VERSION ""

NS_ :

BS_:
BU_: FR FC ADC

BO_ 373 FC_175: 64 FC
 SG_ FC_Obj16WSInfoPosType : 133|4@0+ (1.0000000000,0.0000000000) [0.0000000000|15.0000000000] ""  FC,ADC
 SG_ FC_CRCCheck_175 : 503|16@0+ (1.0000000000,0.0000000000) [0.0000000000|65535.0000000000] ""  FC,ADC
 SG_ FC_RollingCounter_175 : 491|4@0+ (1.0000000000,0.0000000000) [0.0000000000|15.0000000000] ""  FC,ADC
 SG_ FC_Obj16_Img2dBox_RightDown_V : 288|12@0+ (1.0000000000,0.0000000000) [0.0000000000|3000.0000000000] "pix"  FC,ADC
 SG_ FC_Obj16_Img2dBox_LeftTop_V : 284|12@0+ (1.0000000000,0.0000000000) [0.0000000000|3000.0000000000] "pix"  FC,ADC
 SG_ FC_Obj16_Img2dBox_RightDown_U : 264|12@0+ (1.0000000000,0.0000000000) [0.0000000000|4095.0000000000] "pix"  FC,ADC
 SG_ FC_Obj16_Img2dBox_LeftTop_U : 260|12@0+ (1.0000000000,0.0000000000) [0.0000000000|4095.0000000000] "pix"  FC,ADC
 SG_ FC_Obj16_TurnLight : 262|2@0+ (1.0000000000,0.0000000000) [0.0000000000|3.0000000000] ""  FC,ADC
 SG_ FC_Obj16_valid : 263|1@0+ (1.0000000000,0.0000000000) [0.0000000000|1.0000000000] ""  FC,ADC
 SG_ FC_Obj16_Vy_Vnce : 241|10@0+ (0.1250000000,-64.0000000000) [-64.0000000000|63.8750000000] "m/s"  FC,ADC
 SG_ FC_Obj16_Vx_Vnce : 237|12@0+ (0.0625000000,-128.0000000000) [-128.0000000000|127.9375000000] "m/s"  FC,ADC
 SG_ FC_Obj16_CenterAngle : 230|9@0+ (0.0100000000,-1.5700000000) [-1.5700000000|1.5700000000] ""  FC,ADC
 SG_ FC_Obj16_DistInLane : 209|11@0+ (0.0100000000,-10.0000000000) [-10.0000000000|10.0000000000] ""  FC,ADC
 SG_ FC_Obj16_objCutInLane : 211|2@0+ (1.0000000000,0.0000000000) [0.0000000000|2.0000000000] ""  FC,ADC
 SG_ FC_Obj16_objCutInFlag : 201|2@0+ (1.0000000000,0.0000000000) [0.0000000000|2.0000000000] ""  FC,ADC
 SG_ FC_Obj16_CornerPoint_y : 199|14@0+ (0.0100000000,-80.0000000000) [-80.0000000000|80.0000000000] ""  FC,ADC
 SG_ FC_Obj16_CornerPoint_x : 182|15@0+ (0.0100000000,0.0000000000) [0.0000000000|200.0000000000] ""  FC,ADC
 SG_ FC_Obj16_LaneAssignment : 169|3@0+ (1.0000000000,0.0000000000) [0.0000000000|7.0000000000] ""  FC,ADC
 SG_ FC_Obj16_MotionType : 172|3@0+ (1.0000000000,0.0000000000) [0.0000000000|4.0000000000] ""  FC,ADC
 SG_ FC_obj16_Brakelight_Info : 173|1@0+ (1.0000000000,0.0000000000) [0.0000000000|1.0000000000] ""  FC,ADC
 SG_ FC_Obj16_Width : 155|11@0+ (0.0100000000,0.0000000000) [0.0000000000|12.0000000000] "m"  FC,ADC
 SG_ FC_Obj16_Length : 148|9@0+ (0.0500000000,0.0000000000) [0.0000000000|25.5000000000] "m"  FC,ADC
 SG_ FC_Obj16_Height : 141|9@0+ (0.0100000000,0.0000000000) [0.0000000000|5.1100000000] "m"  FC,ADC
 SG_ FC_Obj16_HeadOrientation : 129|4@0+ (1.0000000000,0.0000000000) [0.0000000000|15.0000000000] ""  FC,ADC
 SG_ FC_Obj16_HeadingAngle : 308|10@0+ (0.0100000000,-3.1400000000) [-3.1400000000|3.1400000000] "rad"  FC,ADC
 SG_ FC_Obj16_ExistProb : 112|6@0+ (2.0000000000,0.0000000000) [0.0000000000|100.0000000000] "%"  FC,ADC
 SG_ FC_Obj16_Dy_Vnce : 106|10@0+ (0.0200000000,0.0000000000) [0.0000000000|20.0000000000] "m2"  FC,ADC
 SG_ FC_Obj16_Dy : 88|14@0+ (0.0100000000,-80.0000000000) [-80.0000000000|80.0000000000] "m"  FC,ADC
 SG_ FC_Obj16_Dx_Vnce : 86|14@0+ (0.0500000000,0.0000000000) [0.0000000000|50.0000000000] "m2"  FC,ADC
 SG_ FC_Obj16_Dx : 66|12@0+ (0.0500000000,0.0000000000) [0.0000000000|204.7000000000] "m"  FC,ADC
 SG_ FC_Obj16_RelVy : 60|10@0+ (0.1000000000,-50.0000000000) [-50.0000000000|50.0000000000] "m/s"  FC,ADC
 SG_ FC_Obj16_RelVx : 40|12@0+ (0.1000000000,-154.0000000000) [-154.0000000000|50.0000000000] "m/s"  FC,ADC
 SG_ FC_Obj16_RelAy : 32|8@0+ (0.1000000000,-12.0000000000) [-12.0000000000|12.0000000000] "m/s2"  FC,ADC
 SG_ FC_Obj16_RelAx : 25|9@0+ (0.1000000000,-16.0000000000) [-16.0000000000|16.0000000000] "m/s2"  FC,ADC
 SG_ FC_Obj16_TypeProb : 31|6@0+ (2.0000000000,0.0000000000) [0.0000000000|100.0000000000] "%"  FC,ADC
 SG_ FC_Obj16_Type : 19|4@0+ (1.0000000000,0.0000000000) [0.0000000000|15.0000000000] ""  FC,ADC
 SG_ FC_Obj16_Track_Age : 314|16@0+ (1.0000000000,0.0000000000) [0.0000000000|65535.0000000000] ""  FC,ADC
 SG_ FC_Obj16_Track_ID : 3|8@0+ (1.0000000000,0.0000000000) [0.0000000000|255.0000000000] ""  FC,ADC

BO_ 374 FC_176: 64 FC
 SG_ FC_Obj17WSInfoPosType : 133|4@0+ (1.0000000000,0.0000000000) [0.0000000000|15.0000000000] ""  FC,ADC
 SG_ FC_CRCCheck_176 : 503|16@0+ (1.0000000000,0.0000000000) [0.0000000000|65535.0000000000] ""  FC,ADC
 SG_ FC_RollingCounter_176 : 491|4@0+ (1.0000000000,0.0000000000) [0.0000000000|15.0000000000] ""  FC,ADC
 SG_ FC_Obj17_Img2dBox_RightDown_V : 288|12@0+ (1.0000000000,0.0000000000) [0.0000000000|3000.0000000000] "pix"  FC,ADC
 SG_ FC_Obj17_Img2dBox_LeftTop_V : 284|12@0+ (1.0000000000,0.0000000000) [0.0000000000|3000.0000000000] "pix"  FC,ADC
 SG_ FC_Obj17_Img2dBox_RightDown_U : 264|12@0+ (1.0000000000,0.0000000000) [0.0000000000|4095.0000000000] "pix"  FC,ADC
 SG_ FC_Obj17_Img2dBox_LeftTop_U : 260|12@0+ (1.0000000000,0.0000000000) [0.0000000000|4095.0000000000] "pix"  FC,ADC
 SG_ FC_Obj17_TurnLight : 262|2@0+ (1.0000000000,0.0000000000) [0.0000000000|3.0000000000] ""  FC,ADC
 SG_ FC_Obj17_valid : 263|1@0+ (1.0000000000,0.0000000000) [0.0000000000|1.0000000000] ""  FC,ADC
 SG_ FC_Obj17_Vy_Vnce : 241|10@0+ (0.1250000000,-64.0000000000) [-64.0000000000|63.8750000000] "m/s"  FC,ADC
 SG_ FC_Obj17_Vx_Vnce : 237|12@0+ (0.0625000000,-128.0000000000) [-128.0000000000|127.9375000000] "m/s"  FC,ADC
 SG_ FC_Obj17_CenterAngle : 230|9@0+ (0.0100000000,-1.5700000000) [-1.5700000000|1.5700000000] ""  FC,ADC
 SG_ FC_Obj17_DistInLane : 209|11@0+ (0.0100000000,-10.0000000000) [-10.0000000000|10.0000000000] ""  FC,ADC
 SG_ FC_Obj17_objCutInLane : 211|2@0+ (1.0000000000,0.0000000000) [0.0000000000|2.0000000000] ""  FC,ADC
 SG_ FC_Obj17_objCutInFlag : 201|2@0+ (1.0000000000,0.0000000000) [0.0000000000|2.0000000000] ""  FC,ADC
 SG_ FC_Obj17_CornerPoint_y : 199|14@0+ (0.0100000000,-80.0000000000) [-80.0000000000|80.0000000000] ""  FC,ADC
 SG_ FC_Obj17_CornerPoint_x : 182|15@0+ (0.0100000000,0.0000000000) [0.0000000000|200.0000000000] ""  FC,ADC
 SG_ FC_Obj17_LaneAssignment : 169|3@0+ (1.0000000000,0.0000000000) [0.0000000000|7.0000000000] ""  FC,ADC
 SG_ FC_Obj17_MotionType : 172|3@0+ (1.0000000000,0.0000000000) [0.0000000000|4.0000000000] ""  FC,ADC
 SG_ FC_obj17_Brakelight_Info : 173|1@0+ (1.0000000000,0.0000000000) [0.0000000000|1.0000000000] ""  FC,ADC
 SG_ FC_Obj17_Width : 155|11@0+ (0.0100000000,0.0000000000) [0.0000000000|12.0000000000] "m"  FC,ADC
 SG_ FC_Obj17_Length : 148|9@0+ (0.0500000000,0.0000000000) [0.0000000000|25.5000000000] "m"  FC,ADC
 SG_ FC_Obj17_Height : 141|9@0+ (0.0100000000,0.0000000000) [0.0000000000|5.1100000000] "m"  FC,ADC
 SG_ FC_Obj17_HeadOrientation : 129|4@0+ (1.0000000000,0.0000000000) [0.0000000000|15.0000000000] ""  FC,ADC
 SG_ FC_Obj17_HeadingAngle : 308|10@0+ (0.0100000000,-3.1400000000) [-3.1400000000|3.1400000000] "rad"  FC,ADC
 SG_ FC_Obj17_ExistProb : 112|6@0+ (2.0000000000,0.0000000000) [0.0000000000|100.0000000000] "%"  FC,ADC
 SG_ FC_Obj17_Dy_Vnce : 106|10@0+ (0.0200000000,0.0000000000) [0.0000000000|20.0000000000] "m2"  FC,ADC
 SG_ FC_Obj17_Dy : 88|14@0+ (0.0100000000,-80.0000000000) [-80.0000000000|80.0000000000] "m"  FC,ADC
 SG_ FC_Obj17_Dx_Vnce : 86|14@0+ (0.0500000000,0.0000000000) [0.0000000000|50.0000000000] "m2"  FC,ADC
 SG_ FC_Obj17_Dx : 66|12@0+ (0.0500000000,0.0000000000) [0.0000000000|204.7000000000] "m"  FC,ADC
 SG_ FC_Obj17_RelVy : 60|10@0+ (0.1000000000,-50.0000000000) [-50.0000000000|50.0000000000] "m/s"  FC,ADC
 SG_ FC_Obj17_RelVx : 40|12@0+ (0.1000000000,-154.0000000000) [-154.0000000000|50.0000000000] "m/s"  FC,ADC
 SG_ FC_Obj17_RelAy : 32|8@0+ (0.1000000000,-12.0000000000) [-12.0000000000|12.0000000000] "m/s2"  FC,ADC
 SG_ FC_Obj17_RelAx : 25|9@0+ (0.1000000000,-16.0000000000) [-16.0000000000|16.0000000000] "m/s2"  FC,ADC
 SG_ FC_Obj17_TypeProb : 31|6@0+ (2.0000000000,0.0000000000) [0.0000000000|100.0000000000] "%"  FC,ADC
 SG_ FC_Obj17_Type : 19|4@0+ (1.0000000000,0.0000000000) [0.0000000000|15.0000000000] ""  FC,ADC
 SG_ FC_Obj17_Track_Age : 314|16@0+ (1.0000000000,0.0000000000) [0.0000000000|65535.0000000000] ""  FC,ADC
 SG_ FC_Obj17_Track_ID : 3|8@0+ (1.0000000000,0.0000000000) [0.0000000000|255.0000000000] ""  FC,ADC

BO_ 375 FC_177: 64 FC
 SG_ FC_Obj18WSInfoPosType : 133|4@0+ (1.0000000000,0.0000000000) [0.0000000000|15.0000000000] ""  FC,ADC
 SG_ FC_CRCCheck_177 : 503|16@0+ (1.0000000000,0.0000000000) [0.0000000000|65535.0000000000] ""  FC,ADC
 SG_ FC_RollingCounter_177 : 491|4@0+ (1.0000000000,0.0000000000) [0.0000000000|15.0000000000] ""  FC,ADC
 SG_ FC_Obj18_Img2dBox_RightDown_V : 288|12@0+ (1.0000000000,0.0000000000) [0.0000000000|3000.0000000000] "pix"  FC,ADC
 SG_ FC_Obj18_Img2dBox_LeftTop_V : 284|12@0+ (1.0000000000,0.0000000000) [0.0000000000|3000.0000000000] "pix"  FC,ADC
 SG_ FC_Obj18_Img2dBox_RightDown_U : 264|12@0+ (1.0000000000,0.0000000000) [0.0000000000|4095.0000000000] "pix"  FC,ADC
 SG_ FC_Obj18_Img2dBox_LeftTop_U : 260|12@0+ (1.0000000000,0.0000000000) [0.0000000000|4095.0000000000] "pix"  FC,ADC
 SG_ FC_Obj18_TurnLight : 262|2@0+ (1.0000000000,0.0000000000) [0.0000000000|3.0000000000] ""  FC,ADC
 SG_ FC_Obj18_valid : 263|1@0+ (1.0000000000,0.0000000000) [0.0000000000|1.0000000000] ""  FC,ADC
 SG_ FC_Obj18_Vy_Vnce : 241|10@0+ (0.1250000000,-64.0000000000) [-64.0000000000|63.8750000000] "m/s"  FC,ADC
 SG_ FC_Obj18_Vx_Vnce : 237|12@0+ (0.0625000000,-128.0000000000) [-128.0000000000|127.9375000000] "m/s"  FC,ADC
 SG_ FC_Obj18_CenterAngle : 230|9@0+ (0.0100000000,-1.5700000000) [-1.5700000000|1.5700000000] ""  FC,ADC
 SG_ FC_Obj18_DistInLane : 209|11@0+ (0.0100000000,-10.0000000000) [-10.0000000000|10.0000000000] ""  FC,ADC
 SG_ FC_Obj18_objCutInLane : 211|2@0+ (1.0000000000,0.0000000000) [0.0000000000|2.0000000000] ""  FC,ADC
 SG_ FC_Obj18_objCutInFlag : 201|2@0+ (1.0000000000,0.0000000000) [0.0000000000|2.0000000000] ""  FC,ADC
 SG_ FC_Obj18_CornerPoint_y : 199|14@0+ (0.0100000000,-80.0000000000) [-80.0000000000|80.0000000000] ""  FC,ADC
 SG_ FC_Obj18_CornerPoint_x : 182|15@0+ (0.0100000000,0.0000000000) [0.0000000000|200.0000000000] ""  FC,ADC
 SG_ FC_Obj18_LaneAssignment : 169|3@0+ (1.0000000000,0.0000000000) [0.0000000000|7.0000000000] ""  FC,ADC
 SG_ FC_Obj18_MotionType : 172|3@0+ (1.0000000000,0.0000000000) [0.0000000000|4.0000000000] ""  FC,ADC
 SG_ FC_obj18_Brakelight_Info : 173|1@0+ (1.0000000000,0.0000000000) [0.0000000000|1.0000000000] ""  FC,ADC
 SG_ FC_Obj18_Width : 155|11@0+ (0.0100000000,0.0000000000) [0.0000000000|12.0000000000] "m"  FC,ADC
 SG_ FC_Obj18_Length : 148|9@0+ (0.0500000000,0.0000000000) [0.0000000000|25.5000000000] "m"  FC,ADC
 SG_ FC_Obj18_Height : 141|9@0+ (0.0100000000,0.0000000000) [0.0000000000|5.1100000000] "m"  FC,ADC
 SG_ FC_Obj18_HeadOrientation : 129|4@0+ (1.0000000000,0.0000000000) [0.0000000000|15.0000000000] ""  FC,ADC
 SG_ FC_Obj18_HeadingAngle : 308|10@0+ (0.0100000000,-3.1400000000) [-3.1400000000|3.1400000000] "rad"  FC,ADC
 SG_ FC_Obj18_ExistProb : 112|6@0+ (2.0000000000,0.0000000000) [0.0000000000|100.0000000000] "%"  FC,ADC
 SG_ FC_Obj18_Dy_Vnce : 106|10@0+ (0.0200000000,0.0000000000) [0.0000000000|20.0000000000] "m2"  FC,ADC
 SG_ FC_Obj18_Dy : 88|14@0+ (0.0100000000,-80.0000000000) [-80.0000000000|80.0000000000] "m"  FC,ADC
 SG_ FC_Obj18_Dx_Vnce : 86|14@0+ (0.0500000000,0.0000000000) [0.0000000000|50.0000000000] "m2"  FC,ADC
 SG_ FC_Obj18_Dx : 66|12@0+ (0.0500000000,0.0000000000) [0.0000000000|204.7000000000] "m"  FC,ADC
 SG_ FC_Obj18_RelVy : 60|10@0+ (0.1000000000,-50.0000000000) [-50.0000000000|50.0000000000] "m/s"  FC,ADC
 SG_ FC_Obj18_RelVx : 40|12@0+ (0.1000000000,-154.0000000000) [-154.0000000000|50.0000000000] "m/s"  FC,ADC
 SG_ FC_Obj18_RelAy : 32|8@0+ (0.1000000000,-12.0000000000) [-12.0000000000|12.0000000000] "m/s2"  FC,ADC
 SG_ FC_Obj18_RelAx : 25|9@0+ (0.1000000000,-16.0000000000) [-16.0000000000|16.0000000000] "m/s2"  FC,ADC
 SG_ FC_Obj18_TypeProb : 31|6@0+ (2.0000000000,0.0000000000) [0.0000000000|100.0000000000] "%"  FC,ADC
 SG_ FC_Obj18_Type : 19|4@0+ (1.0000000000,0.0000000000) [0.0000000000|15.0000000000] ""  FC,ADC
 SG_ FC_Obj18_Track_Age : 314|16@0+ (1.0000000000,0.0000000000) [0.0000000000|65535.0000000000] ""  FC,ADC
 SG_ FC_Obj18_Track_ID : 3|8@0+ (1.0000000000,0.0000000000) [0.0000000000|255.0000000000] ""  FC,ADC

BO_ 376 FC_178: 64 FC
 SG_ FC_Obj19WSInfoPosType : 133|4@0+ (1.0000000000,0.0000000000) [0.0000000000|15.0000000000] ""  FC,ADC
 SG_ FC_CRCCheck_178 : 503|16@0+ (1.0000000000,0.0000000000) [0.0000000000|65535.0000000000] ""  FC,ADC
 SG_ FC_RollingCounter_178 : 491|4@0+ (1.0000000000,0.0000000000) [0.0000000000|15.0000000000] ""  FC,ADC
 SG_ FC_Obj19_Img2dBox_RightDown_V : 288|12@0+ (1.0000000000,0.0000000000) [0.0000000000|3000.0000000000] "pix"  FC,ADC
 SG_ FC_Obj19_Img2dBox_LeftTop_V : 284|12@0+ (1.0000000000,0.0000000000) [0.0000000000|3000.0000000000] "pix"  FC,ADC
 SG_ FC_Obj19_Img2dBox_RightDown_U : 264|12@0+ (1.0000000000,0.0000000000) [0.0000000000|4095.0000000000] "pix"  FC,ADC
 SG_ FC_Obj19_Img2dBox_LeftTop_U : 260|12@0+ (1.0000000000,0.0000000000) [0.0000000000|4095.0000000000] "pix"  FC,ADC
 SG_ FC_Obj19_TurnLight : 262|2@0+ (1.0000000000,0.0000000000) [0.0000000000|3.0000000000] ""  FC,ADC
 SG_ FC_Obj19_valid : 263|1@0+ (1.0000000000,0.0000000000) [0.0000000000|1.0000000000] ""  FC,ADC
 SG_ FC_Obj19_Vy_Vnce : 241|10@0+ (0.1250000000,-64.0000000000) [-64.0000000000|63.8750000000] "m/s"  FC,ADC
 SG_ FC_Obj19_Vx_Vnce : 237|12@0+ (0.0625000000,-128.0000000000) [-128.0000000000|127.9375000000] "m/s"  FC,ADC
 SG_ FC_Obj19_CenterAngle : 230|9@0+ (0.0100000000,-1.5700000000) [-1.5700000000|1.5700000000] ""  FC,ADC
 SG_ FC_Obj19_DistInLane : 209|11@0+ (0.0100000000,-10.0000000000) [-10.0000000000|10.0000000000] ""  FC,ADC
 SG_ FC_Obj19_objCutInLane : 211|2@0+ (1.0000000000,0.0000000000) [0.0000000000|2.0000000000] ""  FC,ADC
 SG_ FC_Obj19_objCutInFlag : 201|2@0+ (1.0000000000,0.0000000000) [0.0000000000|2.0000000000] ""  FC,ADC
 SG_ FC_Obj19_CornerPoint_y : 199|14@0+ (0.0100000000,-80.0000000000) [-80.0000000000|80.0000000000] ""  FC,ADC
 SG_ FC_Obj19_CornerPoint_x : 182|15@0+ (0.0100000000,0.0000000000) [0.0000000000|200.0000000000] ""  FC,ADC
 SG_ FC_Obj19_LaneAssignment : 169|3@0+ (1.0000000000,0.0000000000) [0.0000000000|7.0000000000] ""  FC,ADC
 SG_ FC_Obj19_MotionType : 172|3@0+ (1.0000000000,0.0000000000) [0.0000000000|4.0000000000] ""  FC,ADC
 SG_ FC_obj19_Brakelight_Info : 173|1@0+ (1.0000000000,0.0000000000) [0.0000000000|1.0000000000] ""  FC,ADC
 SG_ FC_Obj19_Width : 155|11@0+ (0.0100000000,0.0000000000) [0.0000000000|12.0000000000] "m"  FC,ADC
 SG_ FC_Obj19_Length : 148|9@0+ (0.0500000000,0.0000000000) [0.0000000000|25.5000000000] "m"  FC,ADC
 SG_ FC_Obj19_Height : 141|9@0+ (0.0100000000,0.0000000000) [0.0000000000|5.1100000000] "m"  FC,ADC
 SG_ FC_Obj19_HeadOrientation : 129|4@0+ (1.0000000000,0.0000000000) [0.0000000000|15.0000000000] ""  FC,ADC
 SG_ FC_Obj19_HeadingAngle : 308|10@0+ (0.0100000000,-3.1400000000) [-3.1400000000|3.1400000000] "rad"  FC,ADC
 SG_ FC_Obj19_ExistProb : 112|6@0+ (2.0000000000,0.0000000000) [0.0000000000|100.0000000000] "%"  FC,ADC
 SG_ FC_Obj19_Dy_Vnce : 106|10@0+ (0.0200000000,0.0000000000) [0.0000000000|20.0000000000] "m2"  FC,ADC
 SG_ FC_Obj19_Dy : 88|14@0+ (0.0100000000,-80.0000000000) [-80.0000000000|80.0000000000] "m"  FC,ADC
 SG_ FC_Obj19_Dx_Vnce : 86|14@0+ (0.0500000000,0.0000000000) [0.0000000000|50.0000000000] "m2"  FC,ADC
 SG_ FC_Obj19_Dx : 66|12@0+ (0.0500000000,0.0000000000) [0.0000000000|204.7000000000] "m"  FC,ADC
 SG_ FC_Obj19_RelVy : 60|10@0+ (0.1000000000,-50.0000000000) [-50.0000000000|50.0000000000] "m/s"  FC,ADC
 SG_ FC_Obj19_RelVx : 40|12@0+ (0.1000000000,-154.0000000000) [-154.0000000000|50.0000000000] "m/s"  FC,ADC
 SG_ FC_Obj19_RelAy : 32|8@0+ (0.1000000000,-12.0000000000) [-12.0000000000|12.0000000000] "m/s2"  FC,ADC
 SG_ FC_Obj19_RelAx : 25|9@0+ (0.1000000000,-16.0000000000) [-16.0000000000|16.0000000000] "m/s2"  FC,ADC
 SG_ FC_Obj19_TypeProb : 31|6@0+ (2.0000000000,0.0000000000) [0.0000000000|100.0000000000] "%"  FC,ADC
 SG_ FC_Obj19_Type : 19|4@0+ (1.0000000000,0.0000000000) [0.0000000000|15.0000000000] ""  FC,ADC
 SG_ FC_Obj19_Track_Age : 314|16@0+ (1.0000000000,0.0000000000) [0.0000000000|65535.0000000000] ""  FC,ADC
 SG_ FC_Obj19_Track_ID : 3|8@0+ (1.0000000000,0.0000000000) [0.0000000000|255.0000000000] ""  FC,ADC

BO_ 377 FC_179: 64 FC
 SG_ FC_Obj20WSInfoPosType : 133|4@0+ (1.0000000000,0.0000000000) [0.0000000000|15.0000000000] ""  FC,ADC
 SG_ FC_CRCCheck_179 : 503|16@0+ (1.0000000000,0.0000000000) [0.0000000000|65535.0000000000] ""  FC,ADC
 SG_ FC_RollingCounter_179 : 491|4@0+ (1.0000000000,0.0000000000) [0.0000000000|15.0000000000] ""  FC,ADC
 SG_ FC_Obj20_Img2dBox_RightDown_V : 288|12@0+ (1.0000000000,0.0000000000) [0.0000000000|3000.0000000000] "pix"  FC,ADC
 SG_ FC_Obj20_Img2dBox_LeftTop_V : 284|12@0+ (1.0000000000,0.0000000000) [0.0000000000|3000.0000000000] "pix"  FC,ADC
 SG_ FC_Obj20_Img2dBox_RightDown_U : 264|12@0+ (1.0000000000,0.0000000000) [0.0000000000|4095.0000000000] "pix"  FC,ADC
 SG_ FC_Obj20_Img2dBox_LeftTop_U : 260|12@0+ (1.0000000000,0.0000000000) [0.0000000000|4095.0000000000] "pix"  FC,ADC
 SG_ FC_Obj20_TurnLight : 262|2@0+ (1.0000000000,0.0000000000) [0.0000000000|3.0000000000] ""  FC,ADC
 SG_ FC_Obj20_valid : 263|1@0+ (1.0000000000,0.0000000000) [0.0000000000|1.0000000000] ""  FC,ADC
 SG_ FC_Obj20_Vy_Vnce : 241|10@0+ (0.1250000000,-64.0000000000) [-64.0000000000|63.8750000000] "m/s"  FC,ADC
 SG_ FC_Obj20_Vx_Vnce : 237|12@0+ (0.0625000000,-128.0000000000) [-128.0000000000|127.9375000000] "m/s"  FC,ADC
 SG_ FC_Obj20_CenterAngle : 230|9@0+ (0.0100000000,-1.5700000000) [-1.5700000000|1.5700000000] ""  FC,ADC
 SG_ FC_Obj20_DistInLane : 209|11@0+ (0.0100000000,-10.0000000000) [-10.0000000000|10.0000000000] ""  FC,ADC
 SG_ FC_Obj20_objCutInLane : 211|2@0+ (1.0000000000,0.0000000000) [0.0000000000|2.0000000000] ""  FC,ADC
 SG_ FC_Obj20_objCutInFlag : 201|2@0+ (1.0000000000,0.0000000000) [0.0000000000|2.0000000000] ""  FC,ADC
 SG_ FC_Obj20_CornerPoint_y : 199|14@0+ (0.0100000000,-80.0000000000) [-80.0000000000|80.0000000000] ""  FC,ADC
 SG_ FC_Obj20_CornerPoint_x : 182|15@0+ (0.0100000000,0.0000000000) [0.0000000000|200.0000000000] ""  FC,ADC
 SG_ FC_Obj20_LaneAssignment : 169|3@0+ (1.0000000000,0.0000000000) [0.0000000000|7.0000000000] ""  FC,ADC
 SG_ FC_Obj20_MotionType : 172|3@0+ (1.0000000000,0.0000000000) [0.0000000000|4.0000000000] ""  FC,ADC
 SG_ FC_obj20_Brakelight_Info : 173|1@0+ (1.0000000000,0.0000000000) [0.0000000000|1.0000000000] ""  FC,ADC
 SG_ FC_Obj20_Width : 155|11@0+ (0.0100000000,0.0000000000) [0.0000000000|12.0000000000] "m"  FC,ADC
 SG_ FC_Obj20_Length : 148|9@0+ (0.0500000000,0.0000000000) [0.0000000000|25.5000000000] "m"  FC,ADC
 SG_ FC_Obj20_Height : 141|9@0+ (0.0100000000,0.0000000000) [0.0000000000|5.1100000000] "m"  FC,ADC
 SG_ FC_Obj20_HeadOrientation : 129|4@0+ (1.0000000000,0.0000000000) [0.0000000000|15.0000000000] ""  FC,ADC
 SG_ FC_Obj20_HeadingAngle : 308|10@0+ (0.0100000000,-3.1400000000) [-3.1400000000|3.1400000000] "rad"  FC,ADC
 SG_ FC_Obj20_ExistProb : 112|6@0+ (2.0000000000,0.0000000000) [0.0000000000|100.0000000000] "%"  FC,ADC
 SG_ FC_Obj20_Dy_Vnce : 106|10@0+ (0.0200000000,0.0000000000) [0.0000000000|20.0000000000] "m2"  FC,ADC
 SG_ FC_Obj20_Dy : 88|14@0+ (0.0100000000,-80.0000000000) [-80.0000000000|80.0000000000] "m"  FC,ADC
 SG_ FC_Obj20_Dx_Vnce : 86|14@0+ (0.0500000000,0.0000000000) [0.0000000000|50.0000000000] "m2"  FC,ADC
 SG_ FC_Obj20_Dx : 66|12@0+ (0.0500000000,0.0000000000) [0.0000000000|204.7000000000] "m"  FC,ADC
 SG_ FC_Obj20_RelVy : 60|10@0+ (0.1000000000,-50.0000000000) [-50.0000000000|50.0000000000] "m/s"  FC,ADC
 SG_ FC_Obj20_RelVx : 40|12@0+ (0.1000000000,-154.0000000000) [-154.0000000000|50.0000000000] "m/s"  FC,ADC
 SG_ FC_Obj20_RelAy : 32|8@0+ (0.1000000000,-12.0000000000) [-12.0000000000|12.0000000000] "m/s2"  FC,ADC
 SG_ FC_Obj20_RelAx : 25|9@0+ (0.1000000000,-16.0000000000) [-16.0000000000|16.0000000000] "m/s2"  FC,ADC
 SG_ FC_Obj20_TypeProb : 31|6@0+ (2.0000000000,0.0000000000) [0.0000000000|100.0000000000] "%"  FC,ADC
 SG_ FC_Obj20_Type : 19|4@0+ (1.0000000000,0.0000000000) [0.0000000000|15.0000000000] ""  FC,ADC
 SG_ FC_Obj20_Track_Age : 314|16@0+ (1.0000000000,0.0000000000) [0.0000000000|65535.0000000000] ""  FC,ADC
 SG_ FC_Obj20_Track_ID : 3|8@0+ (1.0000000000,0.0000000000) [0.0000000000|255.0000000000] ""  FC,ADC

BO_ 400 FC_190: 64 FC
 SG_ FC_SenceMode : 21|2@0+ (1.0000000000,0.0000000000) [0.0000000000|3.0000000000] ""  ADC,FC
 SG_ FC_WorkMode : 18|2@0+ (1.0000000000,0.0000000000) [0.0000000000|3.0000000000] ""  ADC,FC
 SG_ FC_CRCCheck_190 : 503|16@0+ (1.0000000000,0.0000000000) [0.0000000000|65535.0000000000] ""  FR,ADC,FC
 SG_ FC_RollingCounter_190 : 491|4@0+ (1.0000000000,0.0000000000) [0.0000000000|15.0000000000] ""  FR,ADC,FC
 SG_ FC_FrameID : 103|32@0+ (1.0000000000,0.0000000000) [0.0000000000|4294967295.0000000000] ""  FR,ADC,FC
 SG_ FC_CameraFailureStatus : 50|3@0+ (1.0000000000,0.0000000000) [0.0000000000|7.0000000000] ""  FR,ADC,FC
 SG_ FC_CameraCalibrationStatus : 41|2@0+ (1.0000000000,0.0000000000) [0.0000000000|3.0000000000] ""  FR,ADC,FC
 SG_ FC_CIPVFlag : 16|1@0+ (1.0000000000,0.0000000000) [0.0000000000|1.0000000000] ""  FR,ADC,FC
 SG_ FC_CIPV_ID : 15|8@0+ (1.0000000000,0.0000000000) [0.0000000000|255.0000000000] ""  FR,ADC,FC

BO_ 403 FC_193: 64 FC
 SG_ ADC_CRCCheck_193 : 503|16@0+ (1.0000000000,0.0000000000) [0.0000000000|65535.0000000000] ""  FC,ADC
 SG_ ADC_RollingCounter_193 : 491|4@0+ (1.0000000000,0.0000000000) [0.0000000000|15.0000000000] ""  FC,ADC
 SG_ FC_ObjMCUTiStamp : 47|8@0+ (1.0000000000,0.0000000000) [0.0000000000|255.0000000000] "um"  FC,ADC
 SG_ FC_ObjTiOut : 37|1@0+ (1.0000000000,0.0000000000) [0.0000000000|1.0000000000] "-"  FC,ADC
 SG_ FC_ObjTiLeap : 38|1@0+ (1.0000000000,0.0000000000) [0.0000000000|1.0000000000] "-"  FC,ADC
 SG_ FC_ObjTiBas : 39|1@0+ (1.0000000000,0.0000000000) [0.0000000000|1.0000000000] "-"  FC,ADC
 SG_ FC_ObjTiStamp : 7|32@0+ (0.0001000000,0.0000000000) [0.0000000000|429496.7295000000] "s"  FC,ADC

BO_ 405 FC_195: 64 FC
 SG_ FC_CRCCheck_195 : 503|16@0+ (1.0000000000,0.0000000000) [0.0000000000|65535.0000000000] ""  FC,ADC
 SG_ FC_RollingCounter_195 : 491|4@0+ (1.0000000000,0.0000000000) [0.0000000000|15.0000000000] ""  FC,ADC
 SG_ FC_TLA4_ShapeType : 228|2@0+ (1.0000000000,0.0000000000) [0.0000000000|3.0000000000] ""  FC,ADC
 SG_ FC_TLA4_BlindingStatus : 230|2@0+ (1.0000000000,0.0000000000) [0.0000000000|3.0000000000] ""  FC,ADC
 SG_ FC_TLA4_Confidence : 221|7@0+ (1.0000000000,0.0000000000) [0.0000000000|100.0000000000] "%"  FC,ADC
 SG_ FC_TLA4_PosZ : 213|8@0+ (0.1000000000,0.0000000000) [0.0000000000|25.6000000000] "m"  FC,ADC
 SG_ FC_TLA4_PosY : 193|12@0+ (0.0100000000,-20.0000000000) [-20.0000000000|20.9500000000] "m"  FC,ADC
 SG_ FC_TLA4_PosX : 188|11@0+ (0.1000000000,0.0000000000) [0.0000000000|204.7000000000] "m"  FC,ADC
 SG_ FC_TLA4_direction : 176|4@0+ (1.0000000000,0.0000000000) [0.0000000000|15.0000000000] ""  FC,ADC
 SG_ FC_TLA4_Color : 179|3@0+ (1.0000000000,0.0000000000) [0.0000000000|7.0000000000] ""  FC,ADC
 SG_ FC_TLA4_ClassificationType : 182|3@0+ (1.0000000000,0.0000000000) [0.0000000000|7.0000000000] ""  FC,ADC
 SG_ FC_TLA3_ShapeType : 175|2@0+ (1.0000000000,0.0000000000) [0.0000000000|3.0000000000] ""  FC,ADC
 SG_ FC_TLA3_BlindingStatus : 161|2@0+ (1.0000000000,0.0000000000) [0.0000000000|3.0000000000] ""  FC,ADC
 SG_ FC_TLA3_Confidence : 152|7@0+ (1.0000000000,0.0000000000) [0.0000000000|100.0000000000] "%"  FC,ADC
 SG_ FC_TLA3_PosZ : 144|8@0+ (0.1000000000,0.0000000000) [0.0000000000|25.6000000000] "m"  FC,ADC
 SG_ FC_TLA3_PosY : 140|12@0+ (0.0100000000,-20.0000000000) [-20.0000000000|20.9500000000] "m"  FC,ADC
 SG_ FC_TLA3_PosX : 135|11@0+ (0.1000000000,0.0000000000) [0.0000000000|204.7000000000] "m"  FC,ADC
 SG_ FC_TLA3_direction : 123|4@0+ (1.0000000000,0.0000000000) [0.0000000000|15.0000000000] ""  FC,ADC
 SG_ FC_TLA3_Color : 126|3@0+ (1.0000000000,0.0000000000) [0.0000000000|7.0000000000] ""  FC,ADC
 SG_ FC_TLA3_ClassificationType : 113|3@0+ (1.0000000000,0.0000000000) [0.0000000000|7.0000000000] ""  FC,ADC
 SG_ FC_TLA2_ShapeType : 106|2@0+ (1.0000000000,0.0000000000) [0.0000000000|3.0000000000] ""  FC,ADC
 SG_ FC_TLA2_BlindingStatus : 108|2@0+ (1.0000000000,0.0000000000) [0.0000000000|3.0000000000] ""  FC,ADC
 SG_ FC_TLA2_Confidence : 99|7@0+ (1.0000000000,0.0000000000) [0.0000000000|100.0000000000] "%"  FC,ADC
 SG_ FC_TLA2_PosZ : 91|8@0+ (0.1000000000,0.0000000000) [0.0000000000|25.6000000000] "m"  FC,ADC
 SG_ FC_TLA2_PosY : 87|12@0+ (0.0100000000,-20.0000000000) [-20.0000000000|20.9500000000] "m"  FC,ADC
 SG_ FC_TLA2_PosX : 66|11@0+ (0.1000000000,0.0000000000) [0.0000000000|204.7000000000] "m"  FC,ADC
 SG_ FC_TLA2_direction : 70|4@0+ (1.0000000000,0.0000000000) [0.0000000000|15.0000000000] ""  FC,ADC
 SG_ FC_TLA2_Color : 57|3@0+ (1.0000000000,0.0000000000) [0.0000000000|7.0000000000] ""  FC,ADC
 SG_ FC_TLA2_ClassificationType : 60|3@0+ (1.0000000000,0.0000000000) [0.0000000000|7.0000000000] ""  FC,ADC
 SG_ FC_TLA1_ShapeType : 53|2@0+ (1.0000000000,0.0000000000) [0.0000000000|3.0000000000] ""  FC,ADC
 SG_ FC_TLA1_BlindingStatus : 55|2@0+ (1.0000000000,0.0000000000) [0.0000000000|3.0000000000] ""  FC,ADC
 SG_ FC_TLA1_Confidence : 46|7@0+ (1.0000000000,0.0000000000) [0.0000000000|100.0000000000] "%"  FC,ADC
 SG_ FC_TLA1_PosZ : 38|8@0+ (0.1000000000,0.0000000000) [0.0000000000|25.6000000000] "m"  FC,ADC
 SG_ FC_TLA1_PosY : 18|12@0+ (0.0100000000,-20.0000000000) [-20.0000000000|20.9500000000] "m"  FC,ADC
 SG_ FC_TLA1_PosX : 13|11@0+ (0.1000000000,0.0000000000) [0.0000000000|204.7000000000] "m"  FC,ADC
 SG_ FC_TLA1_direction : 1|4@0+ (1.0000000000,0.0000000000) [0.0000000000|15.0000000000] ""  FC,ADC
 SG_ FC_TLA1_Color : 4|3@0+ (1.0000000000,0.0000000000) [0.0000000000|7.0000000000] ""  FC,ADC
 SG_ FC_TLA1_ClassificationType : 7|3@0+ (1.0000000000,0.0000000000) [0.0000000000|7.0000000000] ""  FC,ADC

BO_ 406 FC_196: 64 FC
 SG_ FC_CRCCheck_196 : 503|16@0+ (1.0000000000,0.0000000000) [0.0000000000|65535.0000000000] ""  FC,ADC
 SG_ FC_RollingCounter_196 : 491|4@0+ (1.0000000000,0.0000000000) [0.0000000000|15.0000000000] ""  FC,ADC
 SG_ FC_TFLMCUTiStamp : 327|8@0+ (1.0000000000,0.0000000000) [0.0000000000|255.0000000000] "um"  FC,ADC
 SG_ FC_TFLTiOut : 314|1@0+ (1.0000000000,0.0000000000) [0.0000000000|1.0000000000] "-"  FC,ADC
 SG_ FC_TFLTiLeap : 315|1@0+ (1.0000000000,0.0000000000) [0.0000000000|1.0000000000] "-"  FC,ADC
 SG_ FC_TFLTiBas : 316|1@0+ (1.0000000000,0.0000000000) [0.0000000000|1.0000000000] "-"  FC,ADC
 SG_ FC_TFLTiStamp : 284|32@0+ (0.0001000000,0.0000000000) [0.0000000000|429496.7295000000] "s"  FC,ADC
 SG_ FC_TLAMainObjectID : 247|4@0+ (1.0000000000,0.0000000000) [0.0000000000|15.0000000000] ""  FC,ADC
 SG_ FC_TLAObjectsNumber : 235|4@0+ (1.0000000000,0.0000000000) [0.0000000000|15.0000000000] ""  FC,ADC
 SG_ FC_TLA8_ShapeType : 228|2@0+ (1.0000000000,0.0000000000) [0.0000000000|3.0000000000] ""  FC,ADC
 SG_ FC_TLA8_BlindingStatus : 230|2@0+ (1.0000000000,0.0000000000) [0.0000000000|3.0000000000] ""  FC,ADC
 SG_ FC_TLA8_Confidence : 221|7@0+ (1.0000000000,0.0000000000) [0.0000000000|100.0000000000] "%"  FC,ADC
 SG_ FC_TLA8_PosZ : 213|8@0+ (0.1000000000,0.0000000000) [0.0000000000|25.6000000000] "m"  FC,ADC
 SG_ FC_TLA8_PosY : 193|12@0+ (0.0100000000,-20.0000000000) [-20.0000000000|20.9500000000] "m"  FC,ADC
 SG_ FC_TLA8_PosX : 188|11@0+ (0.1000000000,0.0000000000) [0.0000000000|204.7000000000] "m"  FC,ADC
 SG_ FC_TLA8_direction : 176|4@0+ (1.0000000000,0.0000000000) [0.0000000000|15.0000000000] ""  FC,ADC
 SG_ FC_TLA8_Color : 179|3@0+ (1.0000000000,0.0000000000) [0.0000000000|7.0000000000] ""  FC,ADC
 SG_ FC_TLA8_ClassificationType : 182|3@0+ (1.0000000000,0.0000000000) [0.0000000000|7.0000000000] ""  FC,ADC
 SG_ FC_TLA7_ShapeType : 175|2@0+ (1.0000000000,0.0000000000) [0.0000000000|3.0000000000] ""  FC,ADC
 SG_ FC_TLA7_BlindingStatus : 161|2@0+ (1.0000000000,0.0000000000) [0.0000000000|3.0000000000] ""  FC,ADC
 SG_ FC_TLA7_Confidence : 152|7@0+ (1.0000000000,0.0000000000) [0.0000000000|100.0000000000] "%"  FC,ADC
 SG_ FC_TLA7_PosZ : 144|8@0+ (0.1000000000,0.0000000000) [0.0000000000|25.6000000000] "m"  FC,ADC
 SG_ FC_TLA7_PosY : 140|12@0+ (0.0100000000,-20.0000000000) [-20.0000000000|20.9500000000] "m"  FC,ADC
 SG_ FC_TLA7_PosX : 135|11@0+ (0.1000000000,0.0000000000) [0.0000000000|204.7000000000] "m"  FC,ADC
 SG_ FC_TLA7_direction : 123|4@0+ (1.0000000000,0.0000000000) [0.0000000000|15.0000000000] ""  FC,ADC
 SG_ FC_TLA7_Color : 126|3@0+ (1.0000000000,0.0000000000) [0.0000000000|7.0000000000] ""  FC,ADC
 SG_ FC_TLA7_ClassificationType : 113|3@0+ (1.0000000000,0.0000000000) [0.0000000000|7.0000000000] ""  FC,ADC
 SG_ FC_TLA6_ShapeType : 106|2@0+ (1.0000000000,0.0000000000) [0.0000000000|3.0000000000] ""  FC,ADC
 SG_ FC_TLA6_BlindingStatus : 108|2@0+ (1.0000000000,0.0000000000) [0.0000000000|3.0000000000] ""  FC,ADC
 SG_ FC_TLA6_Confidence : 99|7@0+ (1.0000000000,0.0000000000) [0.0000000000|100.0000000000] "%"  FC,ADC
 SG_ FC_TLA6_PosZ : 91|8@0+ (0.1000000000,0.0000000000) [0.0000000000|25.6000000000] "m"  FC,ADC
 SG_ FC_TLA6_PosY : 87|12@0+ (0.0100000000,-20.0000000000) [-20.0000000000|20.9500000000] "m"  FC,ADC
 SG_ FC_TLA6_PosX : 66|11@0+ (0.1000000000,0.0000000000) [0.0000000000|204.7000000000] "m"  FC,ADC
 SG_ FC_TLA6_direction : 70|4@0+ (1.0000000000,0.0000000000) [0.0000000000|15.0000000000] ""  FC,ADC
 SG_ FC_TLA6_Color : 57|3@0+ (1.0000000000,0.0000000000) [0.0000000000|7.0000000000] ""  FC,ADC
 SG_ FC_TLA6_ClassificationType : 60|3@0+ (1.0000000000,0.0000000000) [0.0000000000|7.0000000000] ""  FC,ADC
 SG_ FC_TLA5_ShapeType : 53|2@0+ (1.0000000000,0.0000000000) [0.0000000000|3.0000000000] ""  FC,ADC
 SG_ FC_TLA5_BlindingStatus : 55|2@0+ (1.0000000000,0.0000000000) [0.0000000000|3.0000000000] ""  FC,ADC
 SG_ FC_TLA5_Confidence : 46|7@0+ (1.0000000000,0.0000000000) [0.0000000000|100.0000000000] "%"  FC,ADC
 SG_ FC_TLA5_PosZ : 38|8@0+ (0.1000000000,0.0000000000) [0.0000000000|25.6000000000] "m"  FC,ADC
 SG_ FC_TLA5_PosY : 18|12@0+ (0.0100000000,-20.0000000000) [-20.0000000000|20.9500000000] "m"  FC,ADC
 SG_ FC_TLA5_PosX : 13|11@0+ (0.1000000000,0.0000000000) [0.0000000000|204.7000000000] "m"  FC,ADC
 SG_ FC_TLA5_direction : 1|4@0+ (1.0000000000,0.0000000000) [0.0000000000|15.0000000000] ""  FC,ADC
 SG_ FC_TLA5_Color : 4|3@0+ (1.0000000000,0.0000000000) [0.0000000000|7.0000000000] ""  FC,ADC
 SG_ FC_TLA5_ClassificationType : 7|3@0+ (1.0000000000,0.0000000000) [0.0000000000|7.0000000000] ""  FC,ADC

BO_ 407 FC_197: 64 FC
 SG_ FC_Pole2_LiftAng : 137|9@0+ (0.0100000000,0.0000000000) [0.0000000000|3.1400000000] "rad"  FC,ADC
 SG_ FC_Pole2_Dy : 133|12@0+ (0.0100000000,-20.0000000000) [-20.0000000000|20.9500000000] "m"  FC,ADC
 SG_ FC_Pole2_Dx : 126|9@0+ (0.1000000000,0.0000000000) [0.0000000000|51.1000000000] "m"  FC,ADC
 SG_ FC_Pole2_Type : 154|3@0+ (1.0000000000,0.0000000000) [0.0000000000|7.0000000000] ""  FC,ADC
 SG_ FC_Pole2_Detected : 127|1@0+ (1.0000000000,0.0000000000) [0.0000000000|1.0000000000] ""  FC,ADC
 SG_ FC_Pole1_LiftAng : 104|9@0+ (0.0100000000,0.0000000000) [0.0000000000|3.1400000000] "rad"  FC,ADC
 SG_ FC_Pole1_Dy : 100|12@0+ (0.0100000000,-20.0000000000) [-20.0000000000|20.9500000000] "m"  FC,ADC
 SG_ FC_Pole1_Dx : 93|9@0+ (0.1000000000,0.0000000000) [0.0000000000|51.1000000000] "m"  FC,ADC
 SG_ FC_Pole1_Type : 158|3@0+ (1.0000000000,0.0000000000) [0.0000000000|7.0000000000] ""  FC,ADC
 SG_ FC_Pole1_Detected : 94|1@0+ (1.0000000000,0.0000000000) [0.0000000000|1.0000000000] ""  FC,ADC
 SG_ FC_CRCCheck_197 : 503|16@0+ (1.0000000000,0.0000000000) [0.0000000000|65535.0000000000] ""  FC,ADC
 SG_ FC_RollingCounter_197 : 491|4@0+ (1.0000000000,0.0000000000) [0.0000000000|15.0000000000] ""  FC,ADC
 SG_ FC_SpeedBump_Dist : 61|10@0+ (0.1000000000,0.0000000000) [0.0000000000|102.3000000000] "m"  FC,ADC
 SG_ FC_SpeedBump_Detect : 62|1@0+ (1.0000000000,0.0000000000) [0.0000000000|1.0000000000] ""  FC,ADC
 SG_ FC_Crosswalk_Dist : 40|10@0+ (0.1000000000,0.0000000000) [0.0000000000|102.3000000000] "m"  FC,ADC
 SG_ FC_Crosswalk_Detect : 41|1@0+ (1.0000000000,0.0000000000) [0.0000000000|1.0000000000] ""  FC,ADC
 SG_ FC_StopLine_Dist : 35|10@0+ (0.1000000000,0.0000000000) [0.0000000000|102.3000000000] "m"  FC,ADC
 SG_ FC_StopLine_Detected : 36|1@0+ (1.0000000000,0.0000000000) [0.0000000000|1.0000000000] ""  FC,ADC
 SG_ FC_TSRWarningSign : 24|4@0+ (1.0000000000,0.0000000000) [0.0000000000|15.0000000000] ""  FC,ADC
 SG_ FC_TSRProhibitionSign : 19|5@0+ (1.0000000000,0.0000000000) [0.0000000000|31.0000000000] ""  FC,ADC
 SG_ FC_TSRMandatorySign : 23|4@0+ (1.0000000000,0.0000000000) [0.0000000000|15.0000000000] ""  FC,ADC
 SG_ FC_speedLimitSign_Dy : 72|10@0+ (0.1000000000,-50.0000000000) [-50.0000000000|50.0000000000] "m"  FC,ADC
 SG_ FC_speedLimitSign_Dx : 67|11@0+ (0.1000000000,0.0000000000) [0.0000000000|200.0000000000] "m"  FC,ADC
 SG_ FC_TSRHostSpdLimitUnits : 12|2@0+ (1.0000000000,0.0000000000) [0.0000000000|3.0000000000] ""  FC,ADC
 SG_ FC_SpeedLimitType_1 : 15|3@0+ (1.0000000000,0.0000000000) [0.0000000000|7.0000000000] ""  FC,ADC
 SG_ FC_SpeedLimit_1 : 7|8@0+ (1.0000000000,0.0000000000) [0.0000000000|255.0000000000] ""  FC,ADC

BO_ 408 FC_198: 64 FC
 SG_ FC_CRCCheck_198 : 503|16@0+ (1.0000000000,0.0000000000) [0.0000000000|65535.0000000000] ""  FC,ADC
 SG_ FC_RollingCounter_198 : 491|4@0+ (1.0000000000,0.0000000000) [0.0000000000|15.0000000000] ""  FC,ADC
 SG_ FC_RoadSignConfidence_3 : 112|7@0+ (1.0000000000,0.0000000000) [0.0000000000|100.0000000000] "%"  FC,ADC
 SG_ FC_RoadSignCenterLatRange_3 : 101|9@0+ (0.0500000000,-8.0000000000) [-8.0000000000|17.5500000000] "m"  FC,ADC
 SG_ FC_RoadSignCenterLngRange_3 : 94|9@0+ (0.1000000000,0.0000000000) [0.0000000000|51.1000000000] "m"  FC,ADC
 SG_ FC_RoadSignType_3 : 83|5@0+ (1.0000000000,0.0000000000) [0.0000000000|15.0000000000] ""  FC,ADC
 SG_ FC_RoadSignConfidence_2 : 74|7@0+ (1.0000000000,0.0000000000) [0.0000000000|100.0000000000] "%"  FC,ADC
 SG_ FC_RoadSignCenterLatRange_2 : 63|9@0+ (0.0500000000,-8.0000000000) [-8.0000000000|17.5500000000] "m"  FC,ADC
 SG_ FC_RoadSignCenterLngRange_2 : 40|9@0+ (0.1000000000,0.0000000000) [0.0000000000|51.1000000000] "m"  FC,ADC
 SG_ FC_RoadSignType_2 : 45|5@0+ (1.0000000000,0.0000000000) [0.0000000000|15.0000000000] ""  FC,ADC
 SG_ FC_RoadSignConfidence_1 : 36|7@0+ (1.0000000000,0.0000000000) [0.0000000000|100.0000000000] "%"  FC,ADC
 SG_ FC_RoadSignCenterLatRange_1 : 9|9@0+ (0.0500000000,-8.0000000000) [-8.0000000000|17.5500000000] "m"  FC,ADC
 SG_ FC_RoadSignCenterLngRange_1 : 2|9@0+ (0.1000000000,0.0000000000) [0.0000000000|51.1000000000] "m"  FC,ADC
 SG_ FC_RoadSignType_1 : 7|5@0+ (1.0000000000,0.0000000000) [0.0000000000|15.0000000000] ""  FC,ADC

BO_ 516 FC_204: 64 FC
 SG_ FC_Inner_Parameter_Center_V : 82|12@0+ (1.0000000000,-400.0000000000) [-400.0000000000|2000.0000000000] ""  FC,ADC
 SG_ FC_Inner_Parameter_Center_U : 78|12@0+ (1.0000000000,-500.0000000000) [500.0000000000|4000.0000000000] ""  FC,ADC
 SG_ FC_Inner_Parameter_Focal_V : 59|13@0+ (1.0000000000,-2000.0000000000) [2000.0000000000|4000.0000000000] ""  FC,ADC
 SG_ FC_Inner_Parameter_Focal_U : 40|13@0+ (1.0000000000,-2000.0000000000) [2000.0000000000|4000.0000000000] ""  FC,ADC
 SG_ FC_Exter_Parameter_Dz : 23|9@0+ (0.0100000000,0.0000000000) [0.0000000000|5.0000000000] "m"  FC,ADC
 SG_ FC_Exter_Parameter_Dy : 15|8@0+ (0.0100000000,0.0000000000) [0.0000000000|2.5000000000] "m"  FC,ADC
 SG_ FC_Exter_Parameter_Dx : 7|8@0+ (0.0100000000,-1.0000000000) [1.0000000000|1.0000000000] "m"  FC,ADC
 SG_ FC_DTC2_Status : 158|8@0+ (1.0000000000,0.0000000000) [0.0000000000|255.0000000000] ""  FC,ADC
 SG_ FC_DTC2_LowByte : 150|8@0+ (1.0000000000,0.0000000000) [0.0000000000|255.0000000000] ""  FC,ADC
 SG_ FC_DTC2_MiddByte : 142|8@0+ (1.0000000000,0.0000000000) [0.0000000000|255.0000000000] ""  FC,ADC
 SG_ FC_DTC2_HighByte : 134|8@0+ (1.0000000000,0.0000000000) [0.0000000000|255.0000000000] ""  FC,ADC
 SG_ FC_DTC1_Status : 126|8@0+ (1.0000000000,0.0000000000) [0.0000000000|255.0000000000] ""  FC,ADC
 SG_ FC_DTC1_LowByte : 118|8@0+ (1.0000000000,0.0000000000) [0.0000000000|255.0000000000] ""  FC,ADC
 SG_ FC_DTC1_MiddByte : 110|8@0+ (1.0000000000,0.0000000000) [0.0000000000|255.0000000000] ""  FC,ADC
 SG_ FC_DTC1_HighByte : 102|8@0+ (1.0000000000,0.0000000000) [0.0000000000|255.0000000000] ""  FC,ADC
 SG_ FC_Exter_Parameter_Roll : 47|7@0+ (0.2000000000,-10.0000000000) [-10.0000000000|10.0000000000] "deg"  FC,ADC
 SG_ FC_Exter_Parameter_Yaw : 38|7@0+ (0.2000000000,-10.0000000000) [-10.0000000000|10.0000000000] "deg"  FC,ADC
 SG_ FC_Exter_Parameter_Pitch : 30|8@0+ (0.2000000000,-15.0000000000) [-15.0000000000|15.0000000000] "deg"  FC,ADC

BO_ 264 FC_108: 64 FC
 SG_ FC_CRCCheck_108 : 503|16@0+ (1.0000000000,0.0000000000) [0.0000000000|65535.0000000000] ""  FC,ADC
 SG_ FC_RollingCounter_108 : 491|4@0+ (1.0000000000,0.0000000000) [0.0000000000|15.0000000000] ""  FC,ADC
 SG_ FC_AEBTargetProb : 175|7@0+ (1.0000000000,0.0000000000) [0.0000000000|100.0000000000] "%"  FC,ADC
 SG_ FC_AEBTargetAy : 168|8@0+ (0.1000000000,-12.0000000000) [-12.0000000000|12.0000000000] "m/s2"  FC,ADC
 SG_ FC_AEBTargetAx : 176|9@0+ (0.1000000000,-16.0000000000) [-16.0000000000|16.0000000000] "m/s2"  FC,ADC
 SG_ FC_AEBTargetStatus : 199|2@0+ (1.0000000000,0.0000000000) [0.0000000000|3.0000000000] ""  FC,ADC
 SG_ FC_AEBTargetLatRelSpeed : 197|10@0+ (0.1250000000,-64.0000000000) [-64.0000000000|63.8750000000] "m/s"  FC,ADC
 SG_ FC_RLaneMarkerType : 236|3@0+ (1.0000000000,0.0000000000) [0.0000000000|7.0000000000] ""  FC,ADC
 SG_ FC_HostLaneRightStatus : 224|4@0+ (1.0000000000,0.0000000000) [0.0000000000|15.0000000000] ""  FC,ADC
 SG_ FC_RLaneDistanceFus : 231|7@0+ (0.0500000000,-5.0000000000) [-5.0000000000|1.0000000000] "m"  FC,ADC
 SG_ FC_LLaneMarkerType : 219|3@0+ (1.0000000000,0.0000000000) [0.0000000000|7.0000000000] ""  FC,ADC
 SG_ FC_HostLaneLeftStatus : 223|4@0+ (1.0000000000,0.0000000000) [0.0000000000|15.0000000000] ""  FC,ADC
 SG_ FC_LLaneDistanceFus : 214|7@0+ (0.0500000000,-1.0000000000) [-1.0000000000|5.0000000000] "m"  FC,ADC
 SG_ FC_HMAEnableStatus : 200|1@0+ (1.0000000000,0.0000000000) [0.0000000000|1.0000000000] ""  FC,ADC
 SG_ FC_HMALightDistribution : 201|1@0+ (1.0000000000,0.0000000000) [0.0000000000|1.0000000000] ""  FC,ADC
 SG_ FC_HMAStatus : 203|2@0+ (1.0000000000,0.0000000000) [0.0000000000|3.0000000000] ""  FC,ADC
 SG_ FC_LaneCurvature_0m : 137|7@0+ (0.0005000000,-0.0300000000) [-0.0300000000|0.0300000000] "1/m"  FC,ADC
 SG_ FC_Voiceinfo : 129|5@0+ (1.0000000000,0.0000000000) [0.0000000000|31.0000000000] ""  FC,ADC
 SG_ FC_AEBEnable : 130|1@0+ (1.0000000000,0.0000000000) [0.0000000000|1.0000000000] ""  FC,ADC
 SG_ FC_FCWSettingStatus : 133|3@0+ (1.0000000000,0.0000000000) [0.0000000000|7.0000000000] ""  FC,ADC
 SG_ FC_FCWPreWarning : 134|1@0+ (1.0000000000,0.0000000000) [0.0000000000|1.0000000000] ""  FC,ADC
 SG_ FC_FCWLatentWarning : 135|1@0+ (1.0000000000,0.0000000000) [0.0000000000|1.0000000000] ""  FC,ADC
 SG_ FC_FCWActive : 120|1@0+ (1.0000000000,0.0000000000) [0.0000000000|1.0000000000] ""  FC,ADC
 SG_ FC_FCWStatus : 122|2@0+ (1.0000000000,0.0000000000) [0.0000000000|3.0000000000] ""  FC,ADC
 SG_ FC_AEBTargetLatRange : 116|10@0+ (0.1000000000,-50.0000000000) [-50.0000000000|50.0000000000] "m"  FC,ADC
 SG_ FC_AEBTargetLngRange : 109|9@0+ (0.5000000000,-70.0000000000) [-70.0000000000|180.0000000000] "m"  FC,ADC
 SG_ FC_AEBTargetDetection : 110|1@0+ (1.0000000000,0.0000000000) [0.0000000000|1.0000000000] ""  FC,ADC
 SG_ FC_AEBTargetType : 98|4@0+ (1.0000000000,0.0000000000) [0.0000000000|15.0000000000] ""  FC,ADC
 SG_ FC_AEBTargetRelSpeed : 91|9@0+ (1.0000000000,-250.0000000000) [-250.0000000000|250.0000000000] "km/h"  FC,ADC
 SG_ FC_AEBTextInfo : 95|4@0+ (1.0000000000,0.0000000000) [0.0000000000|15.0000000000] ""  FC,ADC
 SG_ FC_AEBStatus : 81|2@0+ (1.0000000000,0.0000000000) [0.0000000000|3.0000000000] ""  FC,ADC
 SG_ FC_ABAActive : 82|1@0+ (1.0000000000,0.0000000000) [0.0000000000|1.0000000000] ""  FC,ADC
 SG_ FC_ABAlevel : 84|2@0+ (1.0000000000,0.0000000000) [0.0000000000|3.0000000000] ""  FC,ADC
 SG_ FC_AWBActive : 85|1@0+ (1.0000000000,0.0000000000) [0.0000000000|1.0000000000] ""  FC,ADC
 SG_ FC_AWBlevel : 73|4@0+ (1.0000000000,0.0000000000) [0.0000000000|15.0000000000] ""  FC,ADC
 SG_ FC_PrefillActive : 74|1@0+ (1.0000000000,0.0000000000) [0.0000000000|1.0000000000] ""  FC,ADC
 SG_ FC_AEBVehilceHoldReq : 75|1@0+ (1.0000000000,0.0000000000) [0.0000000000|1.0000000000] ""  FC,ADC
 SG_ FC_AEBCtrlType : 79|4@0+ (1.0000000000,0.0000000000) [0.0000000000|15.0000000000] ""  FC,ADC
 SG_ FC_AEBTargetDeceleration : 63|16@0+ (0.0005000000,-16.0000000000) [-16.0000000000|16.0000000000] "m/s2"  FC,ADC
 SG_ FC_AEBActive : 48|1@0+ (1.0000000000,0.0000000000) [0.0000000000|1.0000000000] ""  FC,ADC
 SG_ FC_AEBTargetmode : 50|2@0+ (1.0000000000,0.0000000000) [0.0000000000|3.0000000000] ""  FC,ADC
 SG_ FC_OBJ_AEB_ID : 37|8@0+ (1.0000000000,0.0000000000) [0.0000000000|255.0000000000] ""  FC,ADC
 SG_ FC_ELKEnableStatus : 38|1@0+ (1.0000000000,0.0000000000) [0.0000000000|1.0000000000] ""  FC,ADC
 SG_ FC_ELKInterventionMode : 21|2@0+ (1.0000000000,0.0000000000) [0.0000000000|3.0000000000] ""  FC,ADC
 SG_ FC_ELKMode : 8|3@0+ (1.0000000000,0.0000000000) [0.0000000000|7.0000000000] ""  FC,ADC
 SG_ FC_LDWShakeLevStatus : 10|2@0+ (1.0000000000,0.0000000000) [0.0000000000|3.0000000000] ""  FC,ADC
 SG_ FC_LASWarningModeSelectionSts : 13|3@0+ (1.0000000000,0.0000000000) [0.0000000000|7.0000000000] ""  FC,ADC
 SG_ FC_LASModeSelectionStatus : 0|3@0+ (1.0000000000,0.0000000000) [0.0000000000|7.0000000000] ""  FC,ADC
 SG_ FC_LKATakeoverReq : 1|1@0+ (1.0000000000,0.0000000000) [0.0000000000|1.0000000000] ""  FC,ADC
 SG_ FC_LKAStatus : 3|2@0+ (1.0000000000,0.0000000000) [0.0000000000|3.0000000000] ""  FC,ADC
 SG_ FC_LDWVibrationWarningReq : 5|2@0+ (1.0000000000,0.0000000000) [0.0000000000|3.0000000000] ""  FC,ADC
 SG_ FC_LDWStatus : 7|2@0+ (1.0000000000,0.0000000000) [0.0000000000|3.0000000000] ""  FC,ADC

BO_ 263 FC_107: 64 FC
 SG_ FC_CRCCheck_107 : 503|16@0+ (1.0000000000,0.0000000000) [0.0000000000|65535.0000000000] ""  FC,ADC
 SG_ FC_RollingCounter_107 : 491|4@0+ (1.0000000000,0.0000000000) [0.0000000000|15.0000000000] ""  FC,ADC
 SG_ FC_LatAngReqActive : 35|1@0+ (1.0000000000,0.0000000000) [0.0000000000|1.0000000000] ""  FC,ADC
 SG_ FC_LatAngReq : 17|14@0+ (0.1000000000,-720.0000000000) [-720.0000000000|720.0000000000] "degree"  FC,ADC
 SG_ FC_MotorTorqueMinLimitRequest : 12|11@0+ (0.0200000000,-20.4800000000) [-20.4800000000|20.4600000000] "Nm"  FC,ADC
 SG_ FC_MotorTorqueMaxLimitRequest : 7|11@0+ (0.0200000000,-20.4800000000) [-20.4800000000|20.4600000000] "Nm"  FC,ADC

BO_ 261 ADC_105: 64 ADC
 SG_ ESP_IMUCalibrated : 187|1@0+ (1.0000000000,0.0000000000) [0.0000000000|1.0000000000] ""  ADC,FR
 SG_ ESP_YawRateValid : 189|2@0+ (1.0000000000,0.0000000000) [0.0000000000|3.0000000000] ""  ADC,FR
 SG_ ESP_YawRate : 171|14@0+ (0.0100000000,-81.9100000000) [-81.9100000000|81.9200000000] "degree/s"  ADC,FR
 SG_ ESP_LongAccelValid : 173|2@0+ (1.0000000000,0.0000000000) [0.0000000000|3.0000000000] ""  ADC,FR
 SG_ ESP_LongAccel : 154|13@0+ (0.0100000000,-32.0000000000) [-32.0000000000|49.9100000000] "m/s2"  ADC,FR
 SG_ ESP_LatAccelValid : 156|2@0+ (1.0000000000,0.0000000000) [0.0000000000|3.0000000000] ""  ADC,FR
 SG_ ESP_LatAccel : 137|13@0+ (0.0100000000,-32.0000000000) [-32.0000000000|49.9100000000] "m/s2"  ADC,FR
 SG_ ADC_CRCCheck_105 : 503|16@0+ (1.0000000000,0.0000000000) [0.0000000000|65535.0000000000] ""  ADC,FR
 SG_ ADC_RollingCounter_105 : 491|4@0+ (1.0000000000,0.0000000000) [0.0000000000|15.0000000000] ""  ADC,FR
 SG_ EpsSteerAgSensFilr : 138|1@0+ (1.0000000000,0.0000000000) [0.0000000000|1.0000000000] ""  ADC,FR
 SG_ EpsSteerAgRate : 130|8@0+ (4.0000000000,0.0000000000) [0.0000000000|1016.0000000000] "deg/s"  ADC,FR
 SG_ EpsSasSteerAgVld : 131|1@0+ (1.0000000000,0.0000000000) [0.0000000000|1.0000000000] ""  ADC,FR
 SG_ EpsSasSteerAg : 115|16@0+ (0.1000000000,0.0000000000) [-780.0000000000|780.0000000000] "degree"  ADC,FR
 SG_ EpsSasCalSts : 116|1@0+ (1.0000000000,0.0000000000) [0.0000000000|1.0000000000] ""  ADC,FR
 SG_ VcuRdySts : 117|1@0+ (1.0000000000,0.0000000000) [0.0000000000|1.0000000000] ""  ADC,FR
 SG_ VcuVehGearPosnVld : 118|1@0+ (1.0000000000,0.0000000000) [0.0000000000|1.0000000000] ""  ADC,FR
 SG_ VcuGearPosn : 105|3@0+ (1.0000000000,0.0000000000) [0.0000000000|7.0000000000] ""  ADC,FR
 SG_ WhlSpdReRiPls : 97|8@0+ (1.0000000000,0.0000000000) [0.0000000000|254.0000000000] ""  ADC,FR
 SG_ WhlSpdRiReDir : 99|2@0+ (1.0000000000,0.0000000000) [0.0000000000|3.0000000000] ""  ADC,FR
 SG_ WhlSpdRiReDataVld : 100|1@0+ (1.0000000000,0.0000000000) [0.0000000000|1.0000000000] ""  ADC,FR
 SG_ WhlSpdRiReData : 81|13@0+ (0.0562500000,0.0000000000) [0.0000000000|360.0000000000] "km/h"  ADC,FR
 SG_ WhlSpdFrntRiPls : 73|8@0+ (1.0000000000,0.0000000000) [0.0000000000|254.0000000000] ""  ADC,FR
 SG_ WhlSpdRiFrntDir : 75|2@0+ (1.0000000000,0.0000000000) [0.0000000000|3.0000000000] ""  ADC,FR
 SG_ WhlSpdRiFrntDataVld : 76|1@0+ (1.0000000000,0.0000000000) [0.0000000000|1.0000000000] ""  ADC,FR
 SG_ WhlSpdRiFrntData : 57|13@0+ (0.0562500000,0.0000000000) [0.0000000000|360.0000000000] "km/h"  ADC,FR
 SG_ WhlSpdReLePls : 49|8@0+ (1.0000000000,0.0000000000) [0.0000000000|254.0000000000] ""  ADC,FR
 SG_ WhlSpdLeReDir : 51|2@0+ (1.0000000000,0.0000000000) [0.0000000000|3.0000000000] ""  ADC,FR
 SG_ WhlSpdLeReDataVld : 52|1@0+ (1.0000000000,0.0000000000) [0.0000000000|1.0000000000] ""  ADC,FR
 SG_ WhlSpdLeReData : 33|13@0+ (0.0562500000,0.0000000000) [0.0000000000|360.0000000000] "km/h"  ADC,FR
 SG_ WhlSpdFrntLePls : 25|8@0+ (1.0000000000,0.0000000000) [0.0000000000|254.0000000000] ""  ADC,FR
 SG_ WhlSpdLeFrntDir : 27|2@0+ (1.0000000000,0.0000000000) [0.0000000000|3.0000000000] ""  ADC,FR
 SG_ WhlSpdLeFrntDataVld : 28|1@0+ (1.0000000000,0.0000000000) [0.0000000000|1.0000000000] ""  ADC,FR
 SG_ WhlSpdLeFrntData : 9|13@0+ (0.0562500000,0.0000000000) [0.0000000000|360.0000000000] "km/h"  ADC,FR
 SG_ EspVehSpdVld : 10|1@0+ (1.0000000000,0.0000000000) [0.0000000000|1.0000000000] ""  ADC,FR
 SG_ EspVehSpd : 7|13@0+ (0.0562500000,0.0000000000) [0.0000000000|460.7440000000] "km/h"  ADC,FR

BO_ 512 ADC_200: 16 ADC
 SG_ ADC_SYNC_Sync_Time : 39|32@0+ (1.0000000000,0.0000000000) [0.0000000000|4290000000.0000000000] ""  ADC,FR,FC
 SG_ ADC_SYNC_UserByte_OVS_SGW : 31|8@0+ (1.0000000000,0.0000000000) [0.0000000000|255.0000000000] ""  ADC,FR,FC
 SG_ ADC_SYNC_TimeDomain : 23|4@0+ (1.0000000000,0.0000000000) [0.0000000000|15.0000000000] ""  ADC,FR,FC
 SG_ ADC_SYNC_Sequence : 19|4@0+ (1.0000000000,0.0000000000) [0.0000000000|15.0000000000] ""  ADC,FR,FC
 SG_ ADC_SYNC_CRC : 15|8@0+ (1.0000000000,0.0000000000) [0.0000000000|255.0000000000] ""  ADC,FR,FC
 SG_ ADC_SYNC_Type : 7|8@0+ (1.0000000000,0.0000000000) [0.0000000000|255.0000000000] ""  ADC,FR,FC

BO_ 1107 FR_453: 8 FR

BO_ 1104 ADC_450: 8 ADC

BO_ 411 ADC_19B: 64 ADC
 SG_ ACC_ACCMode : 165|3@0+ (1.0000000000,0.0000000000) [0.0000000000|7.0000000000] ""  ADC,FR,FC
 SG_ ADC_SenceMode : 151|2@0+ (1.0000000000,0.0000000000) [0.0000000000|3.0000000000] ""  ADC,FC
 SG_ ADC_CRCCheck_19B : 503|16@0+ (1.0000000000,0.0000000000) [0.0000000000|65535.0000000000] ""  ADC,FR,FC
 SG_ ADC_RollingCounter_19B : 491|4@0+ (1.0000000000,0.0000000000) [0.0000000000|15.0000000000] ""  ADC,FR,FC
 SG_ BcmPwrStsFb : 225|2@0+ (1.0000000000,0.0000000000) [0.0000000000|3.0000000000] ""  ADC,FR,FC
 SG_ TboxLocalTiYear : 220|8@0+ (1.0000000000,2000.0000000000) [2000.0000000000|2255.0000000000] "year"  ADC,FR,FC
 SG_ TboxLocalTiVld : 221|1@0+ (1.0000000000,0.0000000000) [0.0000000000|1.0000000000] ""  ADC,FR,FC
 SG_ TboxLocalTiSec : 211|6@0+ (1.0000000000,0.0000000000) [0.0000000000|63.0000000000] "second"  ADC,FR,FC
 SG_ TboxLocalTiMth : 215|4@0+ (1.0000000000,0.0000000000) [0.0000000000|15.0000000000] "month"  ADC,FR,FC
 SG_ TboxLocalTiMins : 205|6@0+ (1.0000000000,0.0000000000) [0.0000000000|63.0000000000] "minute"  ADC,FR,FC
 SG_ TboxLocalTiHr : 194|5@0+ (1.0000000000,0.0000000000) [0.0000000000|31.0000000000] "hour"  ADC,FR,FC
 SG_ TboxLocalTiDate : 199|5@0+ (1.0000000000,0.0000000000) [0.0000000000|31.0000000000] "day"  ADC,FR,FC
 SG_ CdcTotMilg : 175|24@0+ (0.1000000000,0.0000000000) [0.0000000000|1677721.5000000000] "Km"  ADC,FR,FC
 SG_ ADC_WorkMode : 148|2@0+ (1.0000000000,0.0000000000) [0.0000000000|3.0000000000] ""  ADC,FR,FC
 SG_ ACC_IACCHWAMode : 162|3@0+ (1.0000000000,0.0000000000) [0.0000000000|7.0000000000] ""  ADC,FR,FC
 SG_ ADS_UDLCStatus : 155|4@0+ (1.0000000000,0.0000000000) [0.0000000000|15.0000000000] ""  ADC,FR,FC
 SG_ ADS_Fail : 145|2@0+ (1.0000000000,0.0000000000) [0.0000000000|3.0000000000] ""  ADC,FR,FC

BO_ 518 FR_206: 64 FR
 SG_ FR_SwVers6 : 63|8@0+ (1.0000000000,0.0000000000) [0.0000000000|255.0000000000] ""  FR,ADC
 SG_ FR_SwVers5 : 55|8@0+ (1.0000000000,0.0000000000) [0.0000000000|255.0000000000] ""  FR,ADC
 SG_ FR_SwVers4 : 39|16@0+ (1.0000000000,0.0000000000) [0.0000000000|65535.0000000000] ""  FR,ADC
 SG_ FR_SwVers3 : 31|8@0+ (1.0000000000,0.0000000000) [0.0000000000|255.0000000000] ""  FR,ADC
 SG_ FR_SwVers2 : 23|8@0+ (1.0000000000,0.0000000000) [0.0000000000|255.0000000000] ""  FR,ADC
 SG_ FR_SwVers1 : 15|8@0+ (1.0000000000,0.0000000000) [0.0000000000|255.0000000000] ""  FR,ADC
 SG_ FR_SwVers0 : 7|8@0+ (1.0000000000,0.0000000000) [0.0000000000|255.0000000000] ""  FR,ADC
 SG_ FR_HwVers6 : 127|8@0+ (1.0000000000,0.0000000000) [0.0000000000|255.0000000000] ""  FR,ADC
 SG_ FR_HwVers5 : 119|8@0+ (1.0000000000,0.0000000000) [0.0000000000|255.0000000000] ""  FR,ADC
 SG_ FR_HwVers4 : 103|16@0+ (1.0000000000,0.0000000000) [0.0000000000|65535.0000000000] ""  FR,ADC
 SG_ FR_HwVers3 : 95|8@0+ (1.0000000000,0.0000000000) [0.0000000000|255.0000000000] ""  FR,ADC
 SG_ FR_HwVers2 : 87|8@0+ (1.0000000000,0.0000000000) [0.0000000000|255.0000000000] ""  FR,ADC
 SG_ FR_HwVers1 : 79|8@0+ (1.0000000000,0.0000000000) [0.0000000000|255.0000000000] ""  FR,ADC
 SG_ FR_HwVers0 : 71|8@0+ (1.0000000000,0.0000000000) [0.0000000000|255.0000000000] ""  FR,ADC

BO_ 519 FC_207: 64 FC
 SG_ FC_SwVers6 : 255|8@0+ (1.0000000000,0.0000000000) [0.0000000000|255.0000000000] ""  FC
 SG_ FC_SwVers5 : 247|8@0+ (1.0000000000,0.0000000000) [0.0000000000|255.0000000000] ""  FC
 SG_ FC_SwVers4 : 231|16@0+ (1.0000000000,0.0000000000) [0.0000000000|65535.0000000000] ""  FC
 SG_ FC_SwVers3 : 223|8@0+ (1.0000000000,0.0000000000) [0.0000000000|255.0000000000] ""  FC
 SG_ FC_SwVers2 : 215|8@0+ (1.0000000000,0.0000000000) [0.0000000000|255.0000000000] ""  FC
 SG_ FC_SwVers1 : 207|8@0+ (1.0000000000,0.0000000000) [0.0000000000|255.0000000000] ""  FC
 SG_ FC_SwVers0 : 199|8@0+ (1.0000000000,0.0000000000) [0.0000000000|255.0000000000] ""  FC
 SG_ FC_HwVers6 : 191|8@0+ (1.0000000000,0.0000000000) [0.0000000000|255.0000000000] ""  FC
 SG_ FC_HwVers5 : 183|8@0+ (1.0000000000,0.0000000000) [0.0000000000|255.0000000000] ""  FC
 SG_ FC_HwVers4 : 167|16@0+ (1.0000000000,0.0000000000) [0.0000000000|65535.0000000000] ""  FC
 SG_ FC_HwVers3 : 159|8@0+ (1.0000000000,0.0000000000) [0.0000000000|255.0000000000] ""  FC
 SG_ FC_HwVers2 : 151|8@0+ (1.0000000000,0.0000000000) [0.0000000000|255.0000000000] ""  FC
 SG_ FC_HwVers1 : 143|8@0+ (1.0000000000,0.0000000000) [0.0000000000|255.0000000000] ""  FC
 SG_ FC_HwVers0 : 135|8@0+ (1.0000000000,0.0000000000) [0.0000000000|255.0000000000] ""  FC

BO_ 837 ADC_345: 64 ADC
 SG_ RLR_CRCCheck_345 : 503|16@0+ (1.0000000000,0.0000000000) [0.0000000000|65535.0000000000] ""  ADC,FC
 SG_ RLR_RollingCounter_345 : 491|4@0+ (1.0000000000,0.0000000000) [0.0000000000|15.0000000000] ""  ADC,FC
 SG_ RLR_ElkOBJ2_RefPointLoc : 304|3@0+ (1.0000000000,0.0000000000) [0.0000000000|7.0000000000] ""  ADC,FC
 SG_ RLR_ElkOBJ2_RefPointDx : 301|13@0+ (0.0625000000,-256.0000000000) [-256.0000000000|255.9380000000] "m"  ADC,FC
 SG_ RLR_ElkOBJ2_RefPointDy : 280|11@0+ (0.1250000000,-128.0000000000) [-128.0000000000|127.8750000000] "m"  ADC,FC
 SG_ RLR_ElkOBJ2_ObstacleProb : 286|6@0+ (2.0000000000,0.0000000000) [0.0000000000|100.0000000000] "%"  ADC,FC
 SG_ RLR_ElkOBJ2_Measured : 272|2@0+ (1.0000000000,0.0000000000) [0.0000000000|3.0000000000] ""  ADC,FC
 SG_ RLR_ElkOBJ2_ExistProb : 278|6@0+ (2.0000000000,0.0000000000) [0.0000000000|100.0000000000] "%"  ADC,FC
 SG_ RLR_ElkOBJ2_Location : 264|2@0+ (1.0000000000,0.0000000000) [0.0000000000|3.0000000000] ""  ADC,FC
 SG_ RLR_ElkOBJ2_RelAx : 257|9@0+ (0.0625000000,-16.0000000000) [-16.0000000000|15.9375000000] "m/s2"  ADC,FC
 SG_ RLR_ElkOBJ2_RelAy : 251|10@0+ (0.0312500000,-16.0000000000) [-16.0000000000|15.9688000000] "m/s2"  ADC,FC
 SG_ RLR_ElkOBJ2_RelVx : 247|12@0+ (0.0625000000,-128.0000000000) [-128.0000000000|127.9380000000] "m/s"  ADC,FC
 SG_ RLR_ElkOBJ2_RelVy : 225|10@0+ (0.1250000000,-64.0000000000) [-64.0000000000|63.8750000000] "m/s"  ADC,FC
 SG_ RLR_ElkOBJ2_Dx : 222|13@0+ (0.0625000000,-256.0000000000) [-256.0000000000|255.9380000000] "m"  ADC,FC
 SG_ RLR_ElkOBJ2_Dy : 201|11@0+ (0.1250000000,-128.0000000000) [-128.0000000000|127.8750000000] "m"  ADC,FC
 SG_ RLR_ElkOBJ2_HeadingAngle : 195|10@0+ (0.0100000000,-3.1400000000) [-3.1400000000|3.1400000000] "rad"  ADC,FC
 SG_ RLR_ElkOBJ2_Length : 188|9@0+ (0.0500000000,0.0000000000) [0.0000000000|25.5000000000] "m"  ADC,FC
 SG_ RLR_ElkOBJ2_Height : 181|9@0+ (0.0100000000,0.0000000000) [0.0000000000|5.1100000000] "m"  ADC,FC
 SG_ RLR_ElkOBJ2_Width : 160|11@0+ (0.0100000000,0.0000000000) [0.0000000000|12.0000000000] "m"  ADC,FC
 SG_ RLR_ElkOBJ2_Type : 163|3@0+ (1.0000000000,0.0000000000) [0.0000000000|7.0000000000] ""  ADC,FC
 SG_ RLR_ElkOBJ2_Track_ID : 154|7@0+ (1.0000000000,0.0000000000) [0.0000000000|127.0000000000] ""  ADC,FC
 SG_ RLR_ElkOBJ1_RefPointLoc : 157|3@0+ (1.0000000000,0.0000000000) [0.0000000000|7.0000000000] ""  ADC,FC
 SG_ RLR_ElkOBJ1_RefPointDx : 138|13@0+ (0.0625000000,-256.0000000000) [-256.0000000000|255.9380000000] "m"  ADC,FC
 SG_ RLR_ElkOBJ1_RefPointDy : 133|11@0+ (0.1250000000,-128.0000000000) [-128.0000000000|127.8750000000] "m"  ADC,FC
 SG_ RLR_ElkOBJ1_ObstacleProb : 123|6@0+ (2.0000000000,0.0000000000) [0.0000000000|100.0000000000] "%"  ADC,FC
 SG_ RLR_ElkOBJ1_Measured : 125|2@0+ (1.0000000000,0.0000000000) [0.0000000000|3.0000000000] ""  ADC,FC
 SG_ RLR_ElkOBJ1_ExistProb : 115|6@0+ (2.0000000000,0.0000000000) [0.0000000000|100.0000000000] "%"  ADC,FC
 SG_ RLR_ElkOBJ1_Location : 117|2@0+ (1.0000000000,0.0000000000) [0.0000000000|3.0000000000] ""  ADC,FC
 SG_ RLR_ElkOBJ1_RelAx : 110|9@0+ (0.0625000000,-16.0000000000) [-16.0000000000|15.9375000000] "m/s2"  ADC,FC
 SG_ RLR_ElkOBJ1_RelAy : 88|10@0+ (0.0312500000,-16.0000000000) [-16.0000000000|15.9688000000] "m/s2"  ADC,FC
 SG_ RLR_ElkOBJ1_RelVx : 84|12@0+ (0.0625000000,-128.0000000000) [-128.0000000000|127.9380000000] "m/s"  ADC,FC
 SG_ RLR_ElkOBJ1_RelVy : 78|10@0+ (0.1250000000,-64.0000000000) [-64.0000000000|63.8750000000] "m/s"  ADC,FC
 SG_ RLR_ElkOBJ1_Dx : 59|13@0+ (0.0625000000,-256.0000000000) [-256.0000000000|255.9380000000] "m"  ADC,FC
 SG_ RLR_ElkOBJ1_Dy : 54|11@0+ (0.1250000000,-128.0000000000) [-128.0000000000|127.8750000000] "m"  ADC,FC
 SG_ RLR_ElkOBJ1_HeadingAngle : 32|10@0+ (0.0100000000,-3.1400000000) [-3.1400000000|3.1400000000] "rad"  ADC,FC
 SG_ RLR_ElkOBJ1_Length : 25|9@0+ (0.0500000000,0.0000000000) [0.0000000000|25.5000000000] "m"  ADC,FC
 SG_ RLR_ElkOBJ1_Height : 18|9@0+ (0.0100000000,0.0000000000) [0.0000000000|5.1100000000] "m"  ADC,FC
 SG_ RLR_ElkOBJ1_Width : 13|11@0+ (0.0100000000,0.0000000000) [0.0000000000|12.0000000000] "m"  ADC,FC
 SG_ RLR_ElkOBJ1_Type : 0|3@0+ (1.0000000000,0.0000000000) [0.0000000000|7.0000000000] ""  ADC,FC
 SG_ RLR_ElkOBJ1_Track_ID : 7|7@0+ (1.0000000000,0.0000000000) [0.0000000000|127.0000000000] ""  ADC,FC

BO_ 838 ADC_346: 64 ADC
 SG_ RLR_CRCCheck_346 : 503|16@0+ (1.0000000000,0.0000000000) [0.0000000000|65535.0000000000] ""  ADC,FC
 SG_ RLR_RollingCounter_346 : 491|4@0+ (1.0000000000,0.0000000000) [0.0000000000|15.0000000000] ""  ADC,FC
 SG_ RLR_ElkOBJ4_RefPointLoc : 304|3@0+ (1.0000000000,0.0000000000) [0.0000000000|7.0000000000] ""  ADC,FC
 SG_ RLR_ElkOBJ4_RefPointDx : 301|13@0+ (0.0625000000,-256.0000000000) [-256.0000000000|255.9380000000] "m"  ADC,FC
 SG_ RLR_ElkOBJ4_RefPointDy : 280|11@0+ (0.1250000000,-128.0000000000) [-128.0000000000|127.8750000000] "m"  ADC,FC
 SG_ RLR_ElkOBJ4_ObstacleProb : 286|6@0+ (2.0000000000,0.0000000000) [0.0000000000|100.0000000000] "%"  ADC,FC
 SG_ RLR_ElkOBJ4_Measured : 272|2@0+ (1.0000000000,0.0000000000) [0.0000000000|3.0000000000] ""  ADC,FC
 SG_ RLR_ElkOBJ4_ExistProb : 278|6@0+ (2.0000000000,0.0000000000) [0.0000000000|100.0000000000] "%"  ADC,FC
 SG_ RLR_ElkOBJ4_Location : 264|2@0+ (1.0000000000,0.0000000000) [0.0000000000|3.0000000000] ""  ADC,FC
 SG_ RLR_ElkOBJ4_RelAx : 257|9@0+ (0.0625000000,-16.0000000000) [-16.0000000000|15.9375000000] "m/s2"  ADC,FC
 SG_ RLR_ElkOBJ4_RelAy : 251|10@0+ (0.0312500000,-16.0000000000) [-16.0000000000|15.9688000000] "m/s2"  ADC,FC
 SG_ RLR_ElkOBJ4_RelVx : 247|12@0+ (0.0625000000,-128.0000000000) [-128.0000000000|127.9380000000] "m/s"  ADC,FC
 SG_ RLR_ElkOBJ4_RelVy : 225|10@0+ (0.1250000000,-64.0000000000) [-64.0000000000|63.8750000000] "m/s"  ADC,FC
 SG_ RLR_ElkOBJ4_Dx : 222|13@0+ (0.0625000000,-256.0000000000) [-256.0000000000|255.9380000000] "m"  ADC,FC
 SG_ RLR_ElkOBJ4_Dy : 201|11@0+ (0.1250000000,-128.0000000000) [-128.0000000000|127.8750000000] "m"  ADC,FC
 SG_ RLR_ElkOBJ4_HeadingAngle : 195|10@0+ (0.0100000000,-3.1400000000) [-3.1400000000|3.1400000000] "rad"  ADC,FC
 SG_ RLR_ElkOBJ4_Length : 188|9@0+ (0.0500000000,0.0000000000) [0.0000000000|25.5000000000] "m"  ADC,FC
 SG_ RLR_ElkOBJ4_Height : 181|9@0+ (0.0100000000,0.0000000000) [0.0000000000|5.1100000000] "m"  ADC,FC
 SG_ RLR_ElkOBJ4_Width : 160|11@0+ (0.0100000000,0.0000000000) [0.0000000000|12.0000000000] "m"  ADC,FC
 SG_ RLR_ElkOBJ4_Type : 163|3@0+ (1.0000000000,0.0000000000) [0.0000000000|7.0000000000] ""  ADC,FC
 SG_ RLR_ElkOBJ4_Track_ID : 154|7@0+ (1.0000000000,0.0000000000) [0.0000000000|127.0000000000] ""  ADC,FC
 SG_ RLR_ElkOBJ3_RefPointLoc : 157|3@0+ (1.0000000000,0.0000000000) [0.0000000000|7.0000000000] ""  ADC,FC
 SG_ RLR_ElkOBJ3_RefPointDx : 138|13@0+ (0.0625000000,-256.0000000000) [-256.0000000000|255.9380000000] "m"  ADC,FC
 SG_ RLR_ElkOBJ3_RefPointDy : 133|11@0+ (0.1250000000,-128.0000000000) [-128.0000000000|127.8750000000] "m"  ADC,FC
 SG_ RLR_ElkOBJ3_ObstacleProb : 123|6@0+ (2.0000000000,0.0000000000) [0.0000000000|100.0000000000] "%"  ADC,FC
 SG_ RLR_ElkOBJ3_Measured : 125|2@0+ (1.0000000000,0.0000000000) [0.0000000000|3.0000000000] ""  ADC,FC
 SG_ RLR_ElkOBJ3_ExistProb : 115|6@0+ (2.0000000000,0.0000000000) [0.0000000000|100.0000000000] "%"  ADC,FC
 SG_ RLR_ElkOBJ3_Location : 117|2@0+ (1.0000000000,0.0000000000) [0.0000000000|3.0000000000] ""  ADC,FC
 SG_ RLR_ElkOBJ3_RelAx : 110|9@0+ (0.0625000000,-16.0000000000) [-16.0000000000|15.9375000000] "m/s2"  ADC,FC
 SG_ RLR_ElkOBJ3_RelAy : 88|10@0+ (0.0312500000,-16.0000000000) [-16.0000000000|15.9688000000] "m/s2"  ADC,FC
 SG_ RLR_ElkOBJ3_RelVx : 84|12@0+ (0.0625000000,-128.0000000000) [-128.0000000000|127.9380000000] "m/s"  ADC,FC
 SG_ RLR_ElkOBJ3_RelVy : 78|10@0+ (0.1250000000,-64.0000000000) [-64.0000000000|63.8750000000] "m/s"  ADC,FC
 SG_ RLR_ElkOBJ3_Dx : 59|13@0+ (0.0625000000,-256.0000000000) [-256.0000000000|255.9380000000] "m"  ADC,FC
 SG_ RLR_ElkOBJ3_Dy : 54|11@0+ (0.1250000000,-128.0000000000) [-128.0000000000|127.8750000000] "m"  ADC,FC
 SG_ RLR_ElkOBJ3_HeadingAngle : 32|10@0+ (0.0100000000,-3.1400000000) [-3.1400000000|3.1400000000] "rad"  ADC,FC
 SG_ RLR_ElkOBJ3_Length : 25|9@0+ (0.0500000000,0.0000000000) [0.0000000000|25.5000000000] "m"  ADC,FC
 SG_ RLR_ElkOBJ3_Height : 18|9@0+ (0.0100000000,0.0000000000) [0.0000000000|5.1100000000] "m"  ADC,FC
 SG_ RLR_ElkOBJ3_Width : 13|11@0+ (0.0100000000,0.0000000000) [0.0000000000|12.0000000000] "m"  ADC,FC
 SG_ RLR_ElkOBJ3_Type : 0|3@0+ (1.0000000000,0.0000000000) [0.0000000000|7.0000000000] ""  ADC,FC
 SG_ RLR_ElkOBJ3_Track_ID : 7|7@0+ (1.0000000000,0.0000000000) [0.0000000000|127.0000000000] ""  ADC,FC

BO_ 836 ADC_344: 64 ADC
 SG_ RRR_WorkMode : 43|2@0+ (1.0000000000,0.0000000000) [0.0000000000|3.0000000000] ""  ADC,FC
 SG_ RLR_WorkMode : 41|2@0+ (1.0000000000,0.0000000000) [0.0000000000|3.0000000000] ""  ADC,FC
 SG_ RLR_Left_ELK_oAlert : 32|2@0+ (1.0000000000,0.0000000000) [0.0000000000|3.0000000000] ""  ADC,FC
 SG_ RLR_ELK_oStatus : 36|2@0+ (1.0000000000,0.0000000000) [0.0000000000|3.0000000000] ""  ADC,FC
 SG_ RLR_ELK_oAlert : 38|2@0+ (1.0000000000,0.0000000000) [0.0000000000|3.0000000000] ""  ADC,FC

BO_ 1428 FR_594: 64 FR
 SG_ FR_NotSleep_BYTE7BIT1 : 6|1@0+ (1.0000000000,0.0000000000) [0.0000000000|1.0000000000] ""  ADC,FR
 SG_ FR_NotSleep_BYTE7BIT0 : 4|1@0+ (1.0000000000,0.0000000000) [0.0000000000|1.0000000000] ""  ADC,FR
 SG_ FR_WakeUp_BYTE4BIT1 : 2|1@0+ (1.0000000000,0.0000000000) [0.0000000000|1.0000000000] ""  ADC,FR
 SG_ FR_WakeUp_BYTE4BIT0 : 0|1@0+ (1.0000000000,0.0000000000) [0.0000000000|1.0000000000] ""  ADC,FR

BO_ 384 FC_180: 64 FC
 SG_ FC_StaticObj10_LaneAssi : 341|2@0+ (1.0000000000,0.0000000000) [0.0000000000|3.0000000000] ""  FC,ADC
 SG_ FC_StaticObj9_LaneAssi : 343|2@0+ (1.0000000000,0.0000000000) [0.0000000000|3.0000000000] ""  FC,ADC
 SG_ FC_StaticObj8_LaneAssi : 329|2@0+ (1.0000000000,0.0000000000) [0.0000000000|3.0000000000] ""  FC,ADC
 SG_ FC_StaticObj7_LaneAssi : 331|2@0+ (1.0000000000,0.0000000000) [0.0000000000|3.0000000000] ""  FC,ADC
 SG_ FC_StaticObj6_LaneAssi : 333|2@0+ (1.0000000000,0.0000000000) [0.0000000000|3.0000000000] ""  FC,ADC
 SG_ FC_StaticObj5_LaneAssi : 335|2@0+ (1.0000000000,0.0000000000) [0.0000000000|3.0000000000] ""  FC,ADC
 SG_ FC_StaticObj4_LaneAssi : 321|2@0+ (1.0000000000,0.0000000000) [0.0000000000|3.0000000000] ""  FC,ADC
 SG_ FC_StaticObj3_LaneAssi : 323|2@0+ (1.0000000000,0.0000000000) [0.0000000000|3.0000000000] ""  FC,ADC
 SG_ FC_StaticObj2_LaneAssi : 325|2@0+ (1.0000000000,0.0000000000) [0.0000000000|3.0000000000] ""  FC,ADC
 SG_ FC_StaticObj1_LaneAssi : 327|2@0+ (1.0000000000,0.0000000000) [0.0000000000|3.0000000000] ""  FC,ADC
 SG_ FC_StaticObj10_Track_ID : 319|8@0+ (1.0000000000,0.0000000000) [0.0000000000|255.0000000000] ""  FC,ADC
 SG_ FC_StaticObj9_Track_ID : 311|8@0+ (1.0000000000,0.0000000000) [0.0000000000|255.0000000000] ""  FC,ADC
 SG_ FC_StaticObj8_Track_ID : 303|8@0+ (1.0000000000,0.0000000000) [0.0000000000|255.0000000000] ""  FC,ADC
 SG_ FC_StaticObj7_Track_ID : 295|8@0+ (1.0000000000,0.0000000000) [0.0000000000|255.0000000000] ""  FC,ADC
 SG_ FC_StaticObj6_Track_ID : 287|8@0+ (1.0000000000,0.0000000000) [0.0000000000|255.0000000000] ""  FC,ADC
 SG_ FC_StaticObj5_Track_ID : 279|8@0+ (1.0000000000,0.0000000000) [0.0000000000|255.0000000000] ""  FC,ADC
 SG_ FC_StaticObj4_Track_ID : 271|8@0+ (1.0000000000,0.0000000000) [0.0000000000|255.0000000000] ""  FC,ADC
 SG_ FC_StaticObj3_Track_ID : 263|8@0+ (1.0000000000,0.0000000000) [0.0000000000|255.0000000000] ""  FC,ADC
 SG_ FC_StaticObj2_Track_ID : 255|8@0+ (1.0000000000,0.0000000000) [0.0000000000|255.0000000000] ""  FC,ADC
 SG_ FC_StaticObj1_Track_ID : 247|8@0+ (1.0000000000,0.0000000000) [0.0000000000|255.0000000000] ""  FC,ADC
 SG_ FC_StaticObj10_Dy : 226|11@0+ (0.0500000000,-51.0000000000) [-51.0000000000|51.3500000000] "m"  FC,ADC
 SG_ FC_StaticObj9_Dy : 221|11@0+ (0.0500000000,-51.0000000000) [-51.0000000000|51.3500000000] "m"  FC,ADC
 SG_ FC_StaticObj8_Dy : 200|11@0+ (0.0500000000,-51.0000000000) [-51.0000000000|51.3500000000] "m"  FC,ADC
 SG_ FC_StaticObj7_Dy : 195|11@0+ (0.0500000000,-51.0000000000) [-51.0000000000|51.3500000000] "m"  FC,ADC
 SG_ FC_StaticObj6_Dy : 190|11@0+ (0.0500000000,-51.0000000000) [-51.0000000000|51.3500000000] "m"  FC,ADC
 SG_ FC_StaticObj5_Dy : 169|11@0+ (0.0500000000,-51.0000000000) [-51.0000000000|51.3500000000] "m"  FC,ADC
 SG_ FC_StaticObj4_Dy : 164|11@0+ (0.0500000000,-51.0000000000) [-51.0000000000|51.3500000000] "m"  FC,ADC
 SG_ FC_StaticObj3_Dy : 159|11@0+ (0.0500000000,-51.0000000000) [-51.0000000000|51.3500000000] "m"  FC,ADC
 SG_ FC_StaticObj2_Dy : 138|11@0+ (0.0500000000,-51.0000000000) [-51.0000000000|51.3500000000] "m"  FC,ADC
 SG_ FC_StaticObj1_Dy : 133|11@0+ (0.0500000000,-51.0000000000) [-51.0000000000|51.3500000000] "m"  FC,ADC
 SG_ FC_StaticObj10_Dx : 127|10@0+ (0.2000000000,0.0000000000) [0.0000000000|204.6000000000] "m"  FC,ADC
 SG_ FC_StaticObj9_Dx : 105|10@0+ (0.2000000000,0.0000000000) [0.0000000000|204.6000000000] "m"  FC,ADC
 SG_ FC_StaticObj8_Dx : 99|10@0+ (0.2000000000,0.0000000000) [0.0000000000|204.6000000000] "m"  FC,ADC
 SG_ FC_StaticObj7_Dx : 93|10@0+ (0.2000000000,0.0000000000) [0.0000000000|204.6000000000] "m"  FC,ADC
 SG_ FC_StaticObj6_Dx : 87|10@0+ (0.2000000000,0.0000000000) [0.0000000000|204.6000000000] "m"  FC,ADC
 SG_ FC_StaticObj5_Dx : 65|10@0+ (0.2000000000,0.0000000000) [0.0000000000|204.6000000000] "m"  FC,ADC
 SG_ FC_StaticObj4_Dx : 59|10@0+ (0.2000000000,0.0000000000) [0.0000000000|204.6000000000] "m"  FC,ADC
 SG_ FC_StaticObj3_Dx : 53|10@0+ (0.2000000000,0.0000000000) [0.0000000000|204.6000000000] "m"  FC,ADC
 SG_ FC_StaticObj2_Dx : 47|10@0+ (0.2000000000,0.0000000000) [0.0000000000|204.6000000000] "m"  FC,ADC
 SG_ FC_StaticObj1_Dx : 25|10@0+ (0.2000000000,0.0000000000) [0.0000000000|204.6000000000] "m"  FC,ADC
 SG_ FC_CRCCheck_180 : 503|16@0+ (1.0000000000,0.0000000000) [0.0000000000|65535.0000000000] ""  ADC,FC
 SG_ FC_RollingCounter_180 : 491|4@0+ (1.0000000000,0.0000000000) [0.0000000000|15.0000000000] ""  ADC,FC
 SG_ FC_StaticObj10_Type : 28|3@0+ (1.0000000000,0.0000000000) [0.0000000000|7.0000000000] ""  ADC,FC
 SG_ FC_StaticObj9_Type : 31|3@0+ (1.0000000000,0.0000000000) [0.0000000000|7.0000000000] ""  ADC,FC
 SG_ FC_StaticObj8_Type : 18|3@0+ (1.0000000000,0.0000000000) [0.0000000000|7.0000000000] ""  ADC,FC
 SG_ FC_StaticObj7_Type : 21|3@0+ (1.0000000000,0.0000000000) [0.0000000000|7.0000000000] ""  ADC,FC
 SG_ FC_StaticObj6_Type : 8|3@0+ (1.0000000000,0.0000000000) [0.0000000000|7.0000000000] ""  ADC,FC
 SG_ FC_StaticObj5_Type : 11|3@0+ (1.0000000000,0.0000000000) [0.0000000000|7.0000000000] ""  ADC,FC
 SG_ FC_StaticObj4_Type : 14|3@0+ (1.0000000000,0.0000000000) [0.0000000000|7.0000000000] ""  ADC,FC
 SG_ FC_StaticObj3_Type : 1|3@0+ (1.0000000000,0.0000000000) [0.0000000000|7.0000000000] ""  ADC,FC
 SG_ FC_StaticObj2_Type : 4|3@0+ (1.0000000000,0.0000000000) [0.0000000000|7.0000000000] ""  ADC,FC
 SG_ FC_StaticObj1_Type : 7|3@0+ (1.0000000000,0.0000000000) [0.0000000000|7.0000000000] ""  ADC,FC

BO_ 513 ADC_201: 8 ADC
 SG_ TC397_TimeSyncInit : 1|2@0+ (1.0000000000,0.0000000000) [0.0000000000|1.0000000000] ""  ADC,FC,FR

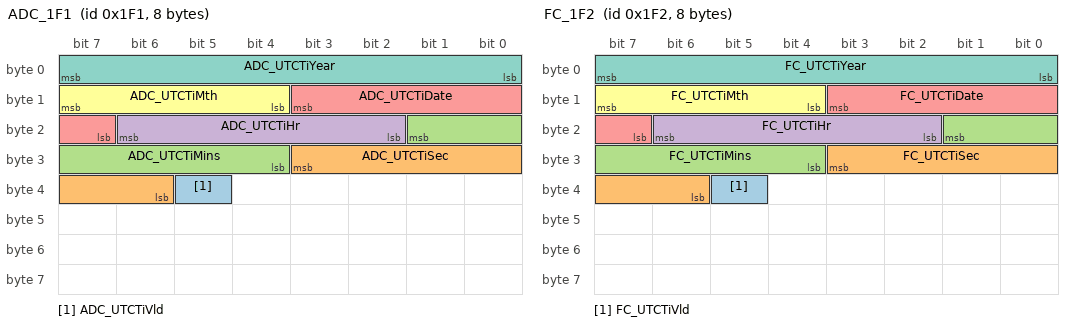
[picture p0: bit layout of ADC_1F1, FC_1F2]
BO_ 497 ADC_1F1: 8 ADC
 SG_ ADC_UTCTiVld : 37|1@0+ (1.0000000000,0.0000000000) [0.0000000000|1.0000000000] ""  ADC,FC
 SG_ ADC_UTCTiSec : 27|6@0+ (1.0000000000,0.0000000000) [0.0000000000|63.0000000000] "second"  ADC,FC
 SG_ ADC_UTCTiMins : 17|6@0+ (1.0000000000,0.0000000000) [0.0000000000|63.0000000000] "minute"  ADC,FC
 SG_ ADC_UTCTiHr : 22|5@0+ (1.0000000000,0.0000000000) [0.0000000000|31.0000000000] "hour"  ADC,FC
 SG_ ADC_UTCTiDate : 11|5@0+ (1.0000000000,0.0000000000) [0.0000000000|31.0000000000] "day"  ADC,FC
 SG_ ADC_UTCTiMth : 15|4@0+ (1.0000000000,0.0000000000) [0.0000000000|15.0000000000] "month"  ADC,FC
 SG_ ADC_UTCTiYear : 7|8@0+ (1.0000000000,2000.0000000000) [2000.0000000000|2255.0000000000] "year"  ADC,FC

BO_ 498 FC_1F2: 8 FC
 SG_ FC_UTCTiVld : 37|1@0+ (1.0000000000,0.0000000000) [0.0000000000|1.0000000000] ""  FC,ADC
 SG_ FC_UTCTiSec : 27|6@0+ (1.0000000000,0.0000000000) [0.0000000000|63.0000000000] "second"  FC,ADC
 SG_ FC_UTCTiMins : 17|6@0+ (1.0000000000,0.0000000000) [0.0000000000|63.0000000000] "minute"  FC,ADC
 SG_ FC_UTCTiHr : 22|5@0+ (1.0000000000,0.0000000000) [0.0000000000|31.0000000000] "hour"  FC,ADC
 SG_ FC_UTCTiDate : 11|5@0+ (1.0000000000,0.0000000000) [0.0000000000|31.0000000000] "day"  FC,ADC
 SG_ FC_UTCTiMth : 15|4@0+ (1.0000000000,0.0000000000) [0.0000000000|15.0000000000] "month"  FC,ADC
 SG_ FC_UTCTiYear : 7|8@0+ (1.0000000000,2000.0000000000) [2000.0000000000|2255.0000000000] "year"  FC,ADC

BO_ 385 FC_181: 64 FC
 SG_ FC_StaticObj20_LaneAssi : 341|2@0+ (1.0000000000,0.0000000000) [0.0000000000|3.0000000000] ""  FC,ADC
 SG_ FC_StaticObj19_LaneAssi : 343|2@0+ (1.0000000000,0.0000000000) [0.0000000000|3.0000000000] ""  FC,ADC
 SG_ FC_StaticObj18_LaneAssi : 329|2@0+ (1.0000000000,0.0000000000) [0.0000000000|3.0000000000] ""  FC,ADC
 SG_ FC_StaticObj17_LaneAssi : 331|2@0+ (1.0000000000,0.0000000000) [0.0000000000|3.0000000000] ""  FC,ADC
 SG_ FC_StaticObj16_LaneAssi : 333|2@0+ (1.0000000000,0.0000000000) [0.0000000000|3.0000000000] ""  FC,ADC
 SG_ FC_StaticObj15_LaneAssi : 335|2@0+ (1.0000000000,0.0000000000) [0.0000000000|3.0000000000] ""  FC,ADC
 SG_ FC_StaticObj14_LaneAssi : 321|2@0+ (1.0000000000,0.0000000000) [0.0000000000|3.0000000000] ""  FC,ADC
 SG_ FC_StaticObj13_LaneAssi : 323|2@0+ (1.0000000000,0.0000000000) [0.0000000000|3.0000000000] ""  FC,ADC
 SG_ FC_StaticObj12_LaneAssi : 325|2@0+ (1.0000000000,0.0000000000) [0.0000000000|3.0000000000] ""  FC,ADC
 SG_ FC_StaticObj11_LaneAssi : 327|2@0+ (1.0000000000,0.0000000000) [0.0000000000|3.0000000000] ""  FC,ADC
 SG_ FC_CRCCheck_181 : 503|16@0+ (1.0000000000,0.0000000000) [0.0000000000|65535.0000000000] ""  ADC,FC
 SG_ FC_RollingCounter_181 : 491|4@0+ (1.0000000000,0.0000000000) [0.0000000000|15.0000000000] ""  ADC,FC
 SG_ FC_StaticObj20_Track_ID : 319|8@0+ (1.0000000000,0.0000000000) [0.0000000000|255.0000000000] ""  FC,ADC
 SG_ FC_StaticObj19_Track_ID : 311|8@0+ (1.0000000000,0.0000000000) [0.0000000000|255.0000000000] ""  FC,ADC
 SG_ FC_StaticObj18_Track_ID : 303|8@0+ (1.0000000000,0.0000000000) [0.0000000000|255.0000000000] ""  FC,ADC
 SG_ FC_StaticObj17_Track_ID : 295|8@0+ (1.0000000000,0.0000000000) [0.0000000000|255.0000000000] ""  FC,ADC
 SG_ FC_StaticObj16_Track_ID : 287|8@0+ (1.0000000000,0.0000000000) [0.0000000000|255.0000000000] ""  FC,ADC
 SG_ FC_StaticObj15_Track_ID : 279|8@0+ (1.0000000000,0.0000000000) [0.0000000000|255.0000000000] ""  FC,ADC
 SG_ FC_StaticObj14_Track_ID : 271|8@0+ (1.0000000000,0.0000000000) [0.0000000000|255.0000000000] ""  FC,ADC
 SG_ FC_StaticObj13_Track_ID : 263|8@0+ (1.0000000000,0.0000000000) [0.0000000000|255.0000000000] ""  FC,ADC
 SG_ FC_StaticObj12_Track_ID : 255|8@0+ (1.0000000000,0.0000000000) [0.0000000000|255.0000000000] ""  FC,ADC
 SG_ FC_StaticObj11_Track_ID : 247|8@0+ (1.0000000000,0.0000000000) [0.0000000000|255.0000000000] ""  FC,ADC
 SG_ FC_StaticObj20_Dy : 226|11@0+ (0.0500000000,-51.0000000000) [-51.0000000000|51.3500000000] "m"  FC,ADC
 SG_ FC_StaticObj19_Dy : 221|11@0+ (0.0500000000,-51.0000000000) [-51.0000000000|51.3500000000] "m"  FC,ADC
 SG_ FC_StaticObj18_Dy : 200|11@0+ (0.0500000000,-51.0000000000) [-51.0000000000|51.3500000000] "m"  FC,ADC
 SG_ FC_StaticObj17_Dy : 195|11@0+ (0.0500000000,-51.0000000000) [-51.0000000000|51.3500000000] "m"  FC,ADC
 SG_ FC_StaticObj16_Dy : 190|11@0+ (0.0500000000,-51.0000000000) [-51.0000000000|51.3500000000] "m"  FC,ADC
 SG_ FC_StaticObj15_Dy : 169|11@0+ (0.0500000000,-51.0000000000) [-51.0000000000|51.3500000000] "m"  FC,ADC
 SG_ FC_StaticObj14_Dy : 164|11@0+ (0.0500000000,-51.0000000000) [-51.0000000000|51.3500000000] "m"  FC,ADC
 SG_ FC_StaticObj13_Dy : 159|11@0+ (0.0500000000,-51.0000000000) [-51.0000000000|51.3500000000] "m"  FC,ADC
 SG_ FC_StaticObj12_Dy : 138|11@0+ (0.0500000000,-51.0000000000) [-51.0000000000|51.3500000000] "m"  FC,ADC
 SG_ FC_StaticObj11_Dy : 133|11@0+ (0.0500000000,-51.0000000000) [-51.0000000000|51.3500000000] "m"  FC,ADC
 SG_ FC_StaticObj20_Dx : 127|10@0+ (0.2000000000,0.0000000000) [0.0000000000|204.6000000000] "m"  FC,ADC
 SG_ FC_StaticObj19_Dx : 105|10@0+ (0.2000000000,0.0000000000) [0.0000000000|204.6000000000] "m"  FC,ADC
 SG_ FC_StaticObj18_Dx : 99|10@0+ (0.2000000000,0.0000000000) [0.0000000000|204.6000000000] "m"  FC,ADC
 SG_ FC_StaticObj17_Dx : 93|10@0+ (0.2000000000,0.0000000000) [0.0000000000|204.6000000000] "m"  FC,ADC
 SG_ FC_StaticObj16_Dx : 87|10@0+ (0.2000000000,0.0000000000) [0.0000000000|204.6000000000] "m"  FC,ADC
 SG_ FC_StaticObj15_Dx : 65|10@0+ (0.2000000000,0.0000000000) [0.0000000000|204.6000000000] "m"  FC,ADC
 SG_ FC_StaticObj14_Dx : 59|10@0+ (0.2000000000,0.0000000000) [0.0000000000|204.6000000000] "m"  FC,ADC
 SG_ FC_StaticObj13_Dx : 53|10@0+ (0.2000000000,0.0000000000) [0.0000000000|204.6000000000] "m"  FC,ADC
 SG_ FC_StaticObj12_Dx : 47|10@0+ (0.2000000000,0.0000000000) [0.0000000000|204.6000000000] "m"  FC,ADC
 SG_ FC_StaticObj11_Dx : 25|10@0+ (0.2000000000,0.0000000000) [0.0000000000|204.6000000000] "m"  FC,ADC
 SG_ FC_StaticObj20_Type : 28|3@0+ (1.0000000000,0.0000000000) [0.0000000000|7.0000000000] ""  ADC,FC
 SG_ FC_StaticObj19_Type : 31|3@0+ (1.0000000000,0.0000000000) [0.0000000000|7.0000000000] ""  ADC,FC
 SG_ FC_StaticObj18_Type : 18|3@0+ (1.0000000000,0.0000000000) [0.0000000000|7.0000000000] ""  ADC,FC
 SG_ FC_StaticObj17_Type : 21|3@0+ (1.0000000000,0.0000000000) [0.0000000000|7.0000000000] ""  ADC,FC
 SG_ FC_StaticObj16_Type : 8|3@0+ (1.0000000000,0.0000000000) [0.0000000000|7.0000000000] ""  ADC,FC
 SG_ FC_StaticObj15_Type : 11|3@0+ (1.0000000000,0.0000000000) [0.0000000000|7.0000000000] ""  ADC,FC
 SG_ FC_StaticObj14_Type : 14|3@0+ (1.0000000000,0.0000000000) [0.0000000000|7.0000000000] ""  ADC,FC
 SG_ FC_StaticObj13_Type : 1|3@0+ (1.0000000000,0.0000000000) [0.0000000000|7.0000000000] ""  ADC,FC
 SG_ FC_StaticObj12_Type : 4|3@0+ (1.0000000000,0.0000000000) [0.0000000000|7.0000000000] ""  ADC,FC
 SG_ FC_StaticObj11_Type : 7|3@0+ (1.0000000000,0.0000000000) [0.0000000000|7.0000000000] ""  ADC,FC

BO_ 1893 ADC_765: 64 ADC

BO_ 1901 FR_76D: 64 FR

BO_ 1937 ADC_791: 8 ADC

BO_ 1945 FR_799: 8 FR

BO_ 2015 ADC_7DF: 64 ADC

CM_ BO_ 373  " ";
CM_ SG_ 373 FC_Obj16WSInfoPosType  " ";
CM_ SG_ 373 FC_CRCCheck_175  " ";
CM_ SG_ 373 FC_RollingCounter_175  " ";
CM_ SG_ 373 FC_Obj16_Img2dBox_RightDown_V  " ";
CM_ SG_ 373 FC_Obj16_Img2dBox_LeftTop_V  " ";
CM_ SG_ 373 FC_Obj16_Img2dBox_RightDown_U  " ";
CM_ SG_ 373 FC_Obj16_Img2dBox_LeftTop_U  " ";
CM_ SG_ 373 FC_Obj16_TurnLight  " ";
CM_ SG_ 373 FC_Obj16_valid  "未收敛目标，输出invalid状态，输出valid状态，信号必须是可性的 ";
CM_ SG_ 373 FC_Obj16_Vy_Vnce  " ";
CM_ SG_ 373 FC_Obj16_Vx_Vnce  " ";
CM_ SG_ 373 FC_Obj16_CenterAngle  " ";
CM_ SG_ 373 FC_Obj16_DistInLane  " ";
CM_ SG_ 373 FC_Obj16_objCutInLane  " ";
CM_ SG_ 373 FC_Obj16_objCutInFlag  " ";
CM_ SG_ 373 FC_Obj16_CornerPoint_y  " ";
CM_ SG_ 373 FC_Obj16_CornerPoint_x  " ";
CM_ SG_ 373 FC_Obj16_LaneAssignment  " ";
CM_ SG_ 373 FC_Obj16_MotionType  " ";
CM_ SG_ 373 FC_obj16_Brakelight_Info  " ";
CM_ SG_ 373 FC_Obj16_Width  " ";
CM_ SG_ 373 FC_Obj16_Length  " ";
CM_ SG_ 373 FC_Obj16_Height  " ";
CM_ SG_ 373 FC_Obj16_HeadOrientation  " ";
CM_ SG_ 373 FC_Obj16_HeadingAngle  " ";
CM_ SG_ 373 FC_Obj16_ExistProb  " ";
CM_ SG_ 373 FC_Obj16_Dy_Vnce  " ";
CM_ SG_ 373 FC_Obj16_Dy  " ";
CM_ SG_ 373 FC_Obj16_Dx_Vnce  " ";
CM_ SG_ 373 FC_Obj16_Dx  " ";
CM_ SG_ 373 FC_Obj16_RelVy  " ";
CM_ SG_ 373 FC_Obj16_RelVx  " ";
CM_ SG_ 373 FC_Obj16_RelAy  " ";
CM_ SG_ 373 FC_Obj16_RelAx  " ";
CM_ SG_ 373 FC_Obj16_TypeProb  " ";
CM_ SG_ 373 FC_Obj16_Type  " ";
CM_ SG_ 373 FC_Obj16_Track_Age  " ";
CM_ SG_ 373 FC_Obj16_Track_ID  " ";

CM_ BO_ 374  " ";
CM_ SG_ 374 FC_Obj17WSInfoPosType  " ";
CM_ SG_ 374 FC_CRCCheck_176  " ";
CM_ SG_ 374 FC_RollingCounter_176  " ";
CM_ SG_ 374 FC_Obj17_Img2dBox_RightDown_V  " ";
CM_ SG_ 374 FC_Obj17_Img2dBox_LeftTop_V  " ";
CM_ SG_ 374 FC_Obj17_Img2dBox_RightDown_U  " ";
CM_ SG_ 374 FC_Obj17_Img2dBox_LeftTop_U  " ";
CM_ SG_ 374 FC_Obj17_TurnLight  " ";
CM_ SG_ 374 FC_Obj17_valid  "未收敛目标，输出invalid状态，输出valid状态，信号必须是可性的 ";
CM_ SG_ 374 FC_Obj17_Vy_Vnce  " ";
CM_ SG_ 374 FC_Obj17_Vx_Vnce  " ";
CM_ SG_ 374 FC_Obj17_CenterAngle  " ";
CM_ SG_ 374 FC_Obj17_DistInLane  " ";
CM_ SG_ 374 FC_Obj17_objCutInLane  " ";
CM_ SG_ 374 FC_Obj17_objCutInFlag  " ";
CM_ SG_ 374 FC_Obj17_CornerPoint_y  " ";
CM_ SG_ 374 FC_Obj17_CornerPoint_x  " ";
CM_ SG_ 374 FC_Obj17_LaneAssignment  " ";
CM_ SG_ 374 FC_Obj17_MotionType  " ";
CM_ SG_ 374 FC_obj17_Brakelight_Info  " ";
CM_ SG_ 374 FC_Obj17_Width  " ";
CM_ SG_ 374 FC_Obj17_Length  " ";
CM_ SG_ 374 FC_Obj17_Height  " ";
CM_ SG_ 374 FC_Obj17_HeadOrientation  " ";
CM_ SG_ 374 FC_Obj17_HeadingAngle  " ";
CM_ SG_ 374 FC_Obj17_ExistProb  " ";
CM_ SG_ 374 FC_Obj17_Dy_Vnce  " ";
CM_ SG_ 374 FC_Obj17_Dy  " ";
CM_ SG_ 374 FC_Obj17_Dx_Vnce  " ";
CM_ SG_ 374 FC_Obj17_Dx  " ";
CM_ SG_ 374 FC_Obj17_RelVy  " ";
CM_ SG_ 374 FC_Obj17_RelVx  " ";
CM_ SG_ 374 FC_Obj17_RelAy  " ";
CM_ SG_ 374 FC_Obj17_RelAx  " ";
CM_ SG_ 374 FC_Obj17_TypeProb  " ";
CM_ SG_ 374 FC_Obj17_Type  " ";
CM_ SG_ 374 FC_Obj17_Track_Age  " ";
CM_ SG_ 374 FC_Obj17_Track_ID  " ";

CM_ BO_ 375  " ";
CM_ SG_ 375 FC_Obj18WSInfoPosType  " ";
CM_ SG_ 375 FC_CRCCheck_177  " ";
CM_ SG_ 375 FC_RollingCounter_177  " ";
CM_ SG_ 375 FC_Obj18_Img2dBox_RightDown_V  " ";
CM_ SG_ 375 FC_Obj18_Img2dBox_LeftTop_V  " ";
CM_ SG_ 375 FC_Obj18_Img2dBox_RightDown_U  " ";
CM_ SG_ 375 FC_Obj18_Img2dBox_LeftTop_U  " ";
CM_ SG_ 375 FC_Obj18_TurnLight  " ";
CM_ SG_ 375 FC_Obj18_valid  "未收敛目标，输出invalid状态，输出valid状态，信号必须是可性的 ";
CM_ SG_ 375 FC_Obj18_Vy_Vnce  " ";
CM_ SG_ 375 FC_Obj18_Vx_Vnce  " ";
CM_ SG_ 375 FC_Obj18_CenterAngle  " ";
CM_ SG_ 375 FC_Obj18_DistInLane  " ";
CM_ SG_ 375 FC_Obj18_objCutInLane  " ";
CM_ SG_ 375 FC_Obj18_objCutInFlag  " ";
CM_ SG_ 375 FC_Obj18_CornerPoint_y  " ";
CM_ SG_ 375 FC_Obj18_CornerPoint_x  " ";
CM_ SG_ 375 FC_Obj18_LaneAssignment  " ";
CM_ SG_ 375 FC_Obj18_MotionType  " ";
CM_ SG_ 375 FC_obj18_Brakelight_Info  " ";
CM_ SG_ 375 FC_Obj18_Width  " ";
CM_ SG_ 375 FC_Obj18_Length  " ";
CM_ SG_ 375 FC_Obj18_Height  " ";
CM_ SG_ 375 FC_Obj18_HeadOrientation  " ";
CM_ SG_ 375 FC_Obj18_HeadingAngle  " ";
CM_ SG_ 375 FC_Obj18_ExistProb  " ";
CM_ SG_ 375 FC_Obj18_Dy_Vnce  " ";
CM_ SG_ 375 FC_Obj18_Dy  " ";
CM_ SG_ 375 FC_Obj18_Dx_Vnce  " ";
CM_ SG_ 375 FC_Obj18_Dx  " ";
CM_ SG_ 375 FC_Obj18_RelVy  " ";
CM_ SG_ 375 FC_Obj18_RelVx  " ";
CM_ SG_ 375 FC_Obj18_RelAy  " ";
CM_ SG_ 375 FC_Obj18_RelAx  " ";
CM_ SG_ 375 FC_Obj18_TypeProb  " ";
CM_ SG_ 375 FC_Obj18_Type  " ";
CM_ SG_ 375 FC_Obj18_Track_Age  " ";
CM_ SG_ 375 FC_Obj18_Track_ID  " ";

CM_ BO_ 376  " ";
CM_ SG_ 376 FC_Obj19WSInfoPosType  " ";
CM_ SG_ 376 FC_CRCCheck_178  " ";
CM_ SG_ 376 FC_RollingCounter_178  " ";
CM_ SG_ 376 FC_Obj19_Img2dBox_RightDown_V  " ";
CM_ SG_ 376 FC_Obj19_Img2dBox_LeftTop_V  " ";
CM_ SG_ 376 FC_Obj19_Img2dBox_RightDown_U  " ";
CM_ SG_ 376 FC_Obj19_Img2dBox_LeftTop_U  " ";
CM_ SG_ 376 FC_Obj19_TurnLight  " ";
CM_ SG_ 376 FC_Obj19_valid  "未收敛目标，输出invalid状态，输出valid状态，信号必须是可性的 ";
CM_ SG_ 376 FC_Obj19_Vy_Vnce  " ";
CM_ SG_ 376 FC_Obj19_Vx_Vnce  " ";
CM_ SG_ 376 FC_Obj19_CenterAngle  " ";
CM_ SG_ 376 FC_Obj19_DistInLane  " ";
CM_ SG_ 376 FC_Obj19_objCutInLane  " ";
CM_ SG_ 376 FC_Obj19_objCutInFlag  " ";
CM_ SG_ 376 FC_Obj19_CornerPoint_y  " ";
CM_ SG_ 376 FC_Obj19_CornerPoint_x  " ";
CM_ SG_ 376 FC_Obj19_LaneAssignment  " ";
CM_ SG_ 376 FC_Obj19_MotionType  " ";
CM_ SG_ 376 FC_obj19_Brakelight_Info  " ";
CM_ SG_ 376 FC_Obj19_Width  " ";
CM_ SG_ 376 FC_Obj19_Length  " ";
CM_ SG_ 376 FC_Obj19_Height  " ";
CM_ SG_ 376 FC_Obj19_HeadOrientation  " ";
CM_ SG_ 376 FC_Obj19_HeadingAngle  " ";
CM_ SG_ 376 FC_Obj19_ExistProb  " ";
CM_ SG_ 376 FC_Obj19_Dy_Vnce  " ";
CM_ SG_ 376 FC_Obj19_Dy  " ";
CM_ SG_ 376 FC_Obj19_Dx_Vnce  " ";
CM_ SG_ 376 FC_Obj19_Dx  " ";
CM_ SG_ 376 FC_Obj19_RelVy  " ";
CM_ SG_ 376 FC_Obj19_RelVx  " ";
CM_ SG_ 376 FC_Obj19_RelAy  " ";
CM_ SG_ 376 FC_Obj19_RelAx  " ";
CM_ SG_ 376 FC_Obj19_TypeProb  " ";
CM_ SG_ 376 FC_Obj19_Type  " ";
CM_ SG_ 376 FC_Obj19_Track_Age  " ";
CM_ SG_ 376 FC_Obj19_Track_ID  " ";

CM_ BO_ 377  " ";
CM_ SG_ 377 FC_Obj20WSInfoPosType  " ";
CM_ SG_ 377 FC_CRCCheck_179  " ";
CM_ SG_ 377 FC_RollingCounter_179  " ";
CM_ SG_ 377 FC_Obj20_Img2dBox_RightDown_V  " ";
CM_ SG_ 377 FC_Obj20_Img2dBox_LeftTop_V  " ";
CM_ SG_ 377 FC_Obj20_Img2dBox_RightDown_U  " ";
CM_ SG_ 377 FC_Obj20_Img2dBox_LeftTop_U  " ";
CM_ SG_ 377 FC_Obj20_TurnLight  " ";
CM_ SG_ 377 FC_Obj20_valid  "未收敛目标，输出invalid状态，输出valid状态，信号必须是可性的 ";
CM_ SG_ 377 FC_Obj20_Vy_Vnce  " ";
CM_ SG_ 377 FC_Obj20_Vx_Vnce  " ";
CM_ SG_ 377 FC_Obj20_CenterAngle  " ";
CM_ SG_ 377 FC_Obj20_DistInLane  " ";
CM_ SG_ 377 FC_Obj20_objCutInLane  " ";
CM_ SG_ 377 FC_Obj20_objCutInFlag  " ";
CM_ SG_ 377 FC_Obj20_CornerPoint_y  " ";
CM_ SG_ 377 FC_Obj20_CornerPoint_x  " ";
CM_ SG_ 377 FC_Obj20_LaneAssignment  " ";
CM_ SG_ 377 FC_Obj20_MotionType  " ";
CM_ SG_ 377 FC_obj20_Brakelight_Info  " ";
CM_ SG_ 377 FC_Obj20_Width  " ";
CM_ SG_ 377 FC_Obj20_Length  " ";
CM_ SG_ 377 FC_Obj20_Height  " ";
CM_ SG_ 377 FC_Obj20_HeadOrientation  " ";
CM_ SG_ 377 FC_Obj20_HeadingAngle  " ";
CM_ SG_ 377 FC_Obj20_ExistProb  " ";
CM_ SG_ 377 FC_Obj20_Dy_Vnce  " ";
CM_ SG_ 377 FC_Obj20_Dy  " ";
CM_ SG_ 377 FC_Obj20_Dx_Vnce  " ";
CM_ SG_ 377 FC_Obj20_Dx  " ";
CM_ SG_ 377 FC_Obj20_RelVy  " ";
CM_ SG_ 377 FC_Obj20_RelVx  " ";
CM_ SG_ 377 FC_Obj20_RelAy  " ";
CM_ SG_ 377 FC_Obj20_RelAx  " ";
CM_ SG_ 377 FC_Obj20_TypeProb  " ";
CM_ SG_ 377 FC_Obj20_Type  " ";
CM_ SG_ 377 FC_Obj20_Track_Age  " ";
CM_ SG_ 377 FC_Obj20_Track_ID  " ";

CM_ BO_ 400  " ";
CM_ SG_ 400 FC_SenceMode  " ";
CM_ SG_ 400 FC_WorkMode  " ";
CM_ SG_ 400 FC_CRCCheck_190  " ";
CM_ SG_ 400 FC_RollingCounter_190  " ";
CM_ SG_ 400 FC_FrameID  " ";
CM_ SG_ 400 FC_CameraFailureStatus  " ";
CM_ SG_ 400 FC_CameraCalibrationStatus  " ";
CM_ SG_ 400 FC_CIPVFlag  " ";
CM_ SG_ 400 FC_CIPV_ID  " ";

CM_ BO_ 403  " ";
CM_ SG_ 403 FC_ObjMCUTiStamp  " ";
CM_ SG_ 403 FC_ObjTiOut  " ";
CM_ SG_ 403 FC_ObjTiLeap  " ";
CM_ SG_ 403 FC_ObjTiBas  " ";
CM_ SG_ 403 FC_ObjTiStamp  " ";

CM_ BO_ 405  " ";
CM_ SG_ 405 FC_CRCCheck_195  " ";
CM_ SG_ 405 FC_RollingCounter_195  " ";
CM_ SG_ 405 FC_TLA4_ShapeType  " ";
CM_ SG_ 405 FC_TLA4_BlindingStatus  " ";
CM_ SG_ 405 FC_TLA4_Confidence  " ";
CM_ SG_ 405 FC_TLA4_PosZ  " ";
CM_ SG_ 405 FC_TLA4_PosY  " ";
CM_ SG_ 405 FC_TLA4_PosX  " ";
CM_ SG_ 405 FC_TLA4_direction  " ";
CM_ SG_ 405 FC_TLA4_Color  " ";
CM_ SG_ 405 FC_TLA4_ClassificationType  " ";
CM_ SG_ 405 FC_TLA3_ShapeType  " ";
CM_ SG_ 405 FC_TLA3_BlindingStatus  " ";
CM_ SG_ 405 FC_TLA3_Confidence  " ";
CM_ SG_ 405 FC_TLA3_PosZ  " ";
CM_ SG_ 405 FC_TLA3_PosY  " ";
CM_ SG_ 405 FC_TLA3_PosX  " ";
CM_ SG_ 405 FC_TLA3_direction  " ";
CM_ SG_ 405 FC_TLA3_Color  " ";
CM_ SG_ 405 FC_TLA3_ClassificationType  " ";
CM_ SG_ 405 FC_TLA2_ShapeType  " ";
CM_ SG_ 405 FC_TLA2_BlindingStatus  " ";
CM_ SG_ 405 FC_TLA2_Confidence  " ";
CM_ SG_ 405 FC_TLA2_PosZ  " ";
CM_ SG_ 405 FC_TLA2_PosY  " ";
CM_ SG_ 405 FC_TLA2_PosX  " ";
CM_ SG_ 405 FC_TLA2_direction  " ";
CM_ SG_ 405 FC_TLA2_Color  " ";
CM_ SG_ 405 FC_TLA2_ClassificationType  " ";
CM_ SG_ 405 FC_TLA1_ShapeType  " ";
CM_ SG_ 405 FC_TLA1_BlindingStatus  " ";
CM_ SG_ 405 FC_TLA1_Confidence  " ";
CM_ SG_ 405 FC_TLA1_PosZ  " ";
CM_ SG_ 405 FC_TLA1_PosY  " ";
CM_ SG_ 405 FC_TLA1_PosX  " ";
CM_ SG_ 405 FC_TLA1_direction  " ";
CM_ SG_ 405 FC_TLA1_Color  " ";
CM_ SG_ 405 FC_TLA1_ClassificationType  " ";

CM_ BO_ 406  " ";
CM_ SG_ 406 FC_CRCCheck_196  " ";
CM_ SG_ 406 FC_RollingCounter_196  " ";
CM_ SG_ 406 FC_TFLMCUTiStamp  " ";
CM_ SG_ 406 FC_TFLTiOut  " ";
CM_ SG_ 406 FC_TFLTiLeap  " ";
CM_ SG_ 406 FC_TFLTiBas  " ";
CM_ SG_ 406 FC_TFLTiStamp  " ";
CM_ SG_ 406 FC_TLAMainObjectID  " ";
CM_ SG_ 406 FC_TLAObjectsNumber  " ";
CM_ SG_ 406 FC_TLA8_ShapeType  " ";
CM_ SG_ 406 FC_TLA8_BlindingStatus  " ";
CM_ SG_ 406 FC_TLA8_Confidence  " ";
CM_ SG_ 406 FC_TLA8_PosZ  " ";
CM_ SG_ 406 FC_TLA8_PosY  " ";
CM_ SG_ 406 FC_TLA8_PosX  " ";
CM_ SG_ 406 FC_TLA8_direction  " ";
CM_ SG_ 406 FC_TLA8_Color  " ";
CM_ SG_ 406 FC_TLA8_ClassificationType  " ";
CM_ SG_ 406 FC_TLA7_ShapeType  " ";
CM_ SG_ 406 FC_TLA7_BlindingStatus  " ";
CM_ SG_ 406 FC_TLA7_Confidence  " ";
CM_ SG_ 406 FC_TLA7_PosZ  " ";
CM_ SG_ 406 FC_TLA7_PosY  " ";
CM_ SG_ 406 FC_TLA7_PosX  " ";
CM_ SG_ 406 FC_TLA7_direction  " ";
CM_ SG_ 406 FC_TLA7_Color  " ";
CM_ SG_ 406 FC_TLA7_ClassificationType  " ";
CM_ SG_ 406 FC_TLA6_ShapeType  " ";
CM_ SG_ 406 FC_TLA6_BlindingStatus  " ";
CM_ SG_ 406 FC_TLA6_Confidence  " ";
CM_ SG_ 406 FC_TLA6_PosZ  " ";
CM_ SG_ 406 FC_TLA6_PosY  " ";
CM_ SG_ 406 FC_TLA6_PosX  " ";
CM_ SG_ 406 FC_TLA6_direction  " ";
CM_ SG_ 406 FC_TLA6_Color  " ";
CM_ SG_ 406 FC_TLA6_ClassificationType  " ";
CM_ SG_ 406 FC_TLA5_ShapeType  " ";
CM_ SG_ 406 FC_TLA5_BlindingStatus  " ";
CM_ SG_ 406 FC_TLA5_Confidence  " ";
CM_ SG_ 406 FC_TLA5_PosZ  " ";
CM_ SG_ 406 FC_TLA5_PosY  " ";
CM_ SG_ 406 FC_TLA5_PosX  " ";
CM_ SG_ 406 FC_TLA5_direction  " ";
CM_ SG_ 406 FC_TLA5_Color  " ";
CM_ SG_ 406 FC_TLA5_ClassificationType  " ";

CM_ BO_ 407  " ";
CM_ SG_ 407 FC_Pole2_LiftAng  " ";
CM_ SG_ 407 FC_Pole2_Dy  " ";
CM_ SG_ 407 FC_Pole2_Dx  " ";
CM_ SG_ 407 FC_Pole2_Type  " ";
CM_ SG_ 407 FC_Pole2_Detected  " ";
CM_ SG_ 407 FC_Pole1_LiftAng  " ";
CM_ SG_ 407 FC_Pole1_Dy  " ";
CM_ SG_ 407 FC_Pole1_Dx  " ";
CM_ SG_ 407 FC_Pole1_Type  " ";
CM_ SG_ 407 FC_Pole1_Detected  " ";
CM_ SG_ 407 FC_CRCCheck_197  " ";
CM_ SG_ 407 FC_RollingCounter_197  " ";
CM_ SG_ 407 FC_SpeedBump_Dist  " ";
CM_ SG_ 407 FC_SpeedBump_Detect  " ";
CM_ SG_ 407 FC_Crosswalk_Dist  " ";
CM_ SG_ 407 FC_Crosswalk_Detect  " ";
CM_ SG_ 407 FC_StopLine_Dist  " ";
CM_ SG_ 407 FC_StopLine_Detected  " ";
CM_ SG_ 407 FC_TSRWarningSign  " ";
CM_ SG_ 407 FC_TSRProhibitionSign  " ";
CM_ SG_ 407 FC_TSRMandatorySign  " ";
CM_ SG_ 407 FC_speedLimitSign_Dy  " ";
CM_ SG_ 407 FC_speedLimitSign_Dx  " ";
CM_ SG_ 407 FC_TSRHostSpdLimitUnits  " ";
CM_ SG_ 407 FC_SpeedLimitType_1  "至少要区分匝道限速 ";
CM_ SG_ 407 FC_SpeedLimit_1  " 多个限速牌输出限速值大 ";

CM_ BO_ 408  "123分别标识本左右车道 ";
CM_ SG_ 408 FC_CRCCheck_198  " ";
CM_ SG_ 408 FC_RollingCounter_198  " ";
CM_ SG_ 408 FC_RoadSignConfidence_3  " ";
CM_ SG_ 408 FC_RoadSignCenterLatRange_3  " ";
CM_ SG_ 408 FC_RoadSignCenterLngRange_3  " ";
CM_ SG_ 408 FC_RoadSignType_3  " ";
CM_ SG_ 408 FC_RoadSignConfidence_2  " ";
CM_ SG_ 408 FC_RoadSignCenterLatRange_2  " ";
CM_ SG_ 408 FC_RoadSignCenterLngRange_2  " ";
CM_ SG_ 408 FC_RoadSignType_2  " ";
CM_ SG_ 408 FC_RoadSignConfidence_1  " ";
CM_ SG_ 408 FC_RoadSignCenterLatRange_1  " ";
CM_ SG_ 408 FC_RoadSignCenterLngRange_1  " ";
CM_ SG_ 408 FC_RoadSignType_1  " ";

CM_ BO_ 516  " ";
CM_ SG_ 516 FC_Inner_Parameter_Center_V  " ";
CM_ SG_ 516 FC_Inner_Parameter_Center_U  " ";
CM_ SG_ 516 FC_Inner_Parameter_Focal_V  " ";
CM_ SG_ 516 FC_Inner_Parameter_Focal_U  " ";
CM_ SG_ 516 FC_Exter_Parameter_Dz  " ";
CM_ SG_ 516 FC_Exter_Parameter_Dy  " ";
CM_ SG_ 516 FC_Exter_Parameter_Dx  " ";
CM_ SG_ 516 FC_DTC2_Status  "DTC上传 ";
CM_ SG_ 516 FC_DTC2_LowByte  "DTC上传 ";
CM_ SG_ 516 FC_DTC2_MiddByte  "DTC上传 ";
CM_ SG_ 516 FC_DTC2_HighByte  "DTC上传 ";
CM_ SG_ 516 FC_DTC1_Status  "DTC上传 ";
CM_ SG_ 516 FC_DTC1_LowByte  "DTC上传 ";
CM_ SG_ 516 FC_DTC1_MiddByte  "DTC上传 ";
CM_ SG_ 516 FC_DTC1_HighByte  "DTC上传 ";
CM_ SG_ 516 FC_Exter_Parameter_Roll  " ";
CM_ SG_ 516 FC_Exter_Parameter_Yaw  " ";
CM_ SG_ 516 FC_Exter_Parameter_Pitch  " ";

CM_ BO_ 264  " ";
CM_ SG_ 264 FC_CRCCheck_108  " ";
CM_ SG_ 264 FC_RollingCounter_108  " ";
CM_ SG_ 264 FC_AEBTargetProb  " ";
CM_ SG_ 264 FC_AEBTargetAy  " ";
CM_ SG_ 264 FC_AEBTargetAx  " ";
CM_ SG_ 264 FC_AEBTargetStatus  " ";
CM_ SG_ 264 FC_AEBTargetLatRelSpeed  " ";
CM_ SG_ 264 FC_RLaneMarkerType  " ";
CM_ SG_ 264 FC_HostLaneRightStatus  " ";
CM_ SG_ 264 FC_RLaneDistanceFus  " ";
CM_ SG_ 264 FC_LLaneMarkerType  " ";
CM_ SG_ 264 FC_HostLaneLeftStatus  " ";
CM_ SG_ 264 FC_LLaneDistanceFus  " ";
CM_ SG_ 264 FC_HMALightDistribution  " ";
CM_ SG_ 264 FC_HMAStatus  " ";
CM_ SG_ 264 FC_LaneCurvature_0m  " ";
CM_ SG_ 264 FC_Voiceinfo  "根据供应商前雷达实际开发功能，发送对应功能报警声音 ";
CM_ SG_ 264 FC_FCWPreWarning  " ";
CM_ SG_ 264 FC_FCWLatentWarning  " ";
CM_ SG_ 264 FC_FCWActive  " ";
CM_ SG_ 264 FC_FCWStatus  " ";
CM_ SG_ 264 FC_AEBTargetLatRange  " ";
CM_ SG_ 264 FC_AEBTargetLngRange  " ";
CM_ SG_ 264 FC_AEBTargetRelSpeed  " ";
CM_ SG_ 264 FC_AEBTextInfo  " ";
CM_ SG_ 264 FC_AEBStatus  " ";
CM_ SG_ 264 FC_ABAActive  " ";
CM_ SG_ 264 FC_ABAlevel  " ";
CM_ SG_ 264 FC_AWBActive  " ";
CM_ SG_ 264 FC_AWBlevel  " ";
CM_ SG_ 264 FC_PrefillActive  " ";
CM_ SG_ 264 FC_AEBVehilceHoldReq  " ";
CM_ SG_ 264 FC_AEBCtrlType  " ";
CM_ SG_ 264 FC_AEBTargetDeceleration  " ";
CM_ SG_ 264 FC_AEBActive  " ";
CM_ SG_ 264 FC_AEBTargetmode  " ";
CM_ SG_ 264 FC_OBJ_AEB_ID  " ";
CM_ SG_ 264 FC_ELKEnableStatus  " ";
CM_ SG_ 264 FC_ELKInterventionMode  " ";
CM_ SG_ 264 FC_ELKMode  " ";
CM_ SG_ 264 FC_LKATakeoverReq  " ";
CM_ SG_ 264 FC_LKAStatus  " ";
CM_ SG_ 264 FC_LDWVibrationWarningReq  " ";
CM_ SG_ 264 FC_LDWStatus  " ";

CM_ BO_ 263  " ";
CM_ SG_ 263 FC_CRCCheck_107  " ";
CM_ SG_ 263 FC_RollingCounter_107  " ";
CM_ SG_ 263 FC_LatAngReqActive  " ";
CM_ SG_ 263 FC_LatAngReq  " ";
CM_ SG_ 263 FC_MotorTorqueMinLimitRequest  " ";
CM_ SG_ 263 FC_MotorTorqueMaxLimitRequest  " ";

CM_ BO_ 261  " ";

CM_ BO_ 512  " ";
CM_ SG_ 512 ADC_SYNC_Sync_Time  " ";
CM_ SG_ 512 ADC_SYNC_UserByte_OVS_SGW  " ";
CM_ SG_ 512 ADC_SYNC_TimeDomain  " ";
CM_ SG_ 512 ADC_SYNC_Sequence  " ";
CM_ SG_ 512 ADC_SYNC_CRC  " ";
CM_ SG_ 512 ADC_SYNC_Type  " ";

CM_ BO_ 1107  "Network management ID ";

CM_ BO_ 1104  "Network management ID ";

CM_ BO_ 411  " ";
CM_ SG_ 411 ACC_ACCMode  " ";
CM_ SG_ 411 ADC_SenceMode  " ";
CM_ SG_ 411 ADC_CRCCheck_19B  " ";
CM_ SG_ 411 ADC_RollingCounter_19B  " ";
CM_ SG_ 411 BcmPwrStsFb  " ";
CM_ SG_ 411 TboxLocalTiYear  " ";
CM_ SG_ 411 TboxLocalTiVld  " ";
CM_ SG_ 411 TboxLocalTiSec  " ";
CM_ SG_ 411 TboxLocalTiMth  " ";
CM_ SG_ 411 TboxLocalTiMins  " ";
CM_ SG_ 411 TboxLocalTiHr  " ";
CM_ SG_ 411 TboxLocalTiDate  " ";
CM_ SG_ 411 CdcTotMilg  " ";
CM_ SG_ 411 ADC_WorkMode  " ";
CM_ SG_ 411 ACC_IACCHWAMode  " ";
CM_ SG_ 411 ADS_UDLCStatus  " ";
CM_ SG_ 411 ADS_Fail  " ";

CM_ BO_ 518  " ";
CM_ SG_ 518 FR_SwVers6  "ASCII码，命名规则按照《QJDT037-2019汽车产品零部件件号和名称编制规范》 ";
CM_ SG_ 518 FR_SwVers5  "ASCII码，命名规则按照《QJDT037-2019汽车产品零部件件号和名称编制规范》 ";
CM_ SG_ 518 FR_SwVers4  "ASCII码，命名规则按照《QJDT037-2019汽车产品零部件件号和名称编制规范》 ";
CM_ SG_ 518 FR_SwVers3  "ASCII码，命名规则按照《QJDT037-2019汽车产品零部件件号和名称编制规范》 ";
CM_ SG_ 518 FR_SwVers2  "ASCII码，命名规则按照《QJDT037-2019汽车产品零部件件号和名称编制规范》 ";
CM_ SG_ 518 FR_SwVers1  "ASCII码，命名规则按照《QJDT037-2019汽车产品零部件件号和名称编制规范》 ";
CM_ SG_ 518 FR_SwVers0  "ASCII码，命名规则按照《QJDT037-2019汽车产品零部件件号和名称编制规范》 ";
CM_ SG_ 518 FR_HwVers6  "ASCII码，命名规则按照《QJDT037-2019汽车产品零部件件号和名称编制规范》 ";
CM_ SG_ 518 FR_HwVers5  "ASCII码，命名规则按照《QJDT037-2019汽车产品零部件件号和名称编制规范》 ";
CM_ SG_ 518 FR_HwVers4  "ASCII码，命名规则按照《QJDT037-2019汽车产品零部件件号和名称编制规范》 ";
CM_ SG_ 518 FR_HwVers3  "ASCII码，命名规则按照《QJDT037-2019汽车产品零部件件号和名称编制规范》 ";
CM_ SG_ 518 FR_HwVers2  "ASCII码，命名规则按照《QJDT037-2019汽车产品零部件件号和名称编制规范》 ";
CM_ SG_ 518 FR_HwVers1  "ASCII码，命名规则按照《QJDT037-2019汽车产品零部件件号和名称编制规范》 ";
CM_ SG_ 518 FR_HwVers0  "ASCII码，命名规则按照《QJDT037-2019汽车产品零部件件号和名称编制规范》 ";

CM_ BO_ 519  " ";
CM_ SG_ 519 FC_SwVers6  "ASCII码，命名规则按照《QJDT037-2019汽车产品零部件件号和名称编制规范》 ";
CM_ SG_ 519 FC_SwVers5  "ASCII码，命名规则按照《QJDT037-2019汽车产品零部件件号和名称编制规范》 ";
CM_ SG_ 519 FC_SwVers4  "ASCII码，命名规则按照《QJDT037-2019汽车产品零部件件号和名称编制规范》 ";
CM_ SG_ 519 FC_SwVers3  "ASCII码，命名规则按照《QJDT037-2019汽车产品零部件件号和名称编制规范》 ";
CM_ SG_ 519 FC_SwVers2  "ASCII码，命名规则按照《QJDT037-2019汽车产品零部件件号和名称编制规范》 ";
CM_ SG_ 519 FC_SwVers1  "ASCII码，命名规则按照《QJDT037-2019汽车产品零部件件号和名称编制规范》 ";
CM_ SG_ 519 FC_SwVers0  "ASCII码，命名规则按照《QJDT037-2019汽车产品零部件件号和名称编制规范》 ";
CM_ SG_ 519 FC_HwVers6  "ASCII码，命名规则按照《QJDT037-2019汽车产品零部件件号和名称编制规范》 ";
CM_ SG_ 519 FC_HwVers5  "ASCII码，命名规则按照《QJDT037-2019汽车产品零部件件号和名称编制规范》 ";
CM_ SG_ 519 FC_HwVers4  "ASCII码，命名规则按照《QJDT037-2019汽车产品零部件件号和名称编制规范》 ";
CM_ SG_ 519 FC_HwVers3  "ASCII码，命名规则按照《QJDT037-2019汽车产品零部件件号和名称编制规范》 ";
CM_ SG_ 519 FC_HwVers2  "ASCII码，命名规则按照《QJDT037-2019汽车产品零部件件号和名称编制规范》 ";
CM_ SG_ 519 FC_HwVers1  "ASCII码，命名规则按照《QJDT037-2019汽车产品零部件件号和名称编制规范》 ";
CM_ SG_ 519 FC_HwVers0  "ASCII码，命名规则按照《QJDT037-2019汽车产品零部件件号和名称编制规范》 ";

CM_ BO_ 837  " ";
CM_ SG_ 837 RLR_CRCCheck_345  " ";
CM_ SG_ 837 RLR_RollingCounter_345  " ";
CM_ SG_ 837 RLR_ElkOBJ2_RefPointLoc  " ";
CM_ SG_ 837 RLR_ElkOBJ2_RefPointDx  " ";
CM_ SG_ 837 RLR_ElkOBJ2_RefPointDy  " ";
CM_ SG_ 837 RLR_ElkOBJ2_ObstacleProb  " ";
CM_ SG_ 837 RLR_ElkOBJ2_Measured  " ";
CM_ SG_ 837 RLR_ElkOBJ2_ExistProb  " ";
CM_ SG_ 837 RLR_ElkOBJ2_Location  " ";
CM_ SG_ 837 RLR_ElkOBJ2_RelAx  " ";
CM_ SG_ 837 RLR_ElkOBJ2_RelAy  " ";
CM_ SG_ 837 RLR_ElkOBJ2_RelVx  " ";
CM_ SG_ 837 RLR_ElkOBJ2_RelVy  " ";
CM_ SG_ 837 RLR_ElkOBJ2_Dx  " ";
CM_ SG_ 837 RLR_ElkOBJ2_Dy  " ";
CM_ SG_ 837 RLR_ElkOBJ2_HeadingAngle  " ";
CM_ SG_ 837 RLR_ElkOBJ2_Length  " ";
CM_ SG_ 837 RLR_ElkOBJ2_Height  " ";
CM_ SG_ 837 RLR_ElkOBJ2_Width  " ";
CM_ SG_ 837 RLR_ElkOBJ2_Type  " ";
CM_ SG_ 837 RLR_ElkOBJ2_Track_ID  " ";
CM_ SG_ 837 RLR_ElkOBJ1_RefPointLoc  " ";
CM_ SG_ 837 RLR_ElkOBJ1_RefPointDx  " ";
CM_ SG_ 837 RLR_ElkOBJ1_RefPointDy  " ";
CM_ SG_ 837 RLR_ElkOBJ1_ObstacleProb  " ";
CM_ SG_ 837 RLR_ElkOBJ1_Measured  " ";
CM_ SG_ 837 RLR_ElkOBJ1_ExistProb  " ";
CM_ SG_ 837 RLR_ElkOBJ1_Location  " ";
CM_ SG_ 837 RLR_ElkOBJ1_RelAx  " ";
CM_ SG_ 837 RLR_ElkOBJ1_RelAy  " ";
CM_ SG_ 837 RLR_ElkOBJ1_RelVx  " ";
CM_ SG_ 837 RLR_ElkOBJ1_RelVy  " ";
CM_ SG_ 837 RLR_ElkOBJ1_Dx  " ";
CM_ SG_ 837 RLR_ElkOBJ1_Dy  " ";
CM_ SG_ 837 RLR_ElkOBJ1_HeadingAngle  " ";
CM_ SG_ 837 RLR_ElkOBJ1_Length  " ";
CM_ SG_ 837 RLR_ElkOBJ1_Height  " ";
CM_ SG_ 837 RLR_ElkOBJ1_Width  " ";
CM_ SG_ 837 RLR_ElkOBJ1_Type  " ";
CM_ SG_ 837 RLR_ElkOBJ1_Track_ID  " ";

CM_ BO_ 838  " ";
CM_ SG_ 838 RLR_CRCCheck_346  " ";
CM_ SG_ 838 RLR_RollingCounter_346  " ";
CM_ SG_ 838 RLR_ElkOBJ4_RefPointLoc  " ";
CM_ SG_ 838 RLR_ElkOBJ4_RefPointDx  " ";
CM_ SG_ 838 RLR_ElkOBJ4_RefPointDy  " ";
CM_ SG_ 838 RLR_ElkOBJ4_ObstacleProb  " ";
CM_ SG_ 838 RLR_ElkOBJ4_Measured  " ";
CM_ SG_ 838 RLR_ElkOBJ4_ExistProb  " ";
CM_ SG_ 838 RLR_ElkOBJ4_Location  " ";
CM_ SG_ 838 RLR_ElkOBJ4_RelAx  " ";
CM_ SG_ 838 RLR_ElkOBJ4_RelAy  " ";
CM_ SG_ 838 RLR_ElkOBJ4_RelVx  " ";
CM_ SG_ 838 RLR_ElkOBJ4_RelVy  " ";
CM_ SG_ 838 RLR_ElkOBJ4_Dx  " ";
CM_ SG_ 838 RLR_ElkOBJ4_Dy  " ";
CM_ SG_ 838 RLR_ElkOBJ4_HeadingAngle  " ";
CM_ SG_ 838 RLR_ElkOBJ4_Length  " ";
CM_ SG_ 838 RLR_ElkOBJ4_Height  " ";
CM_ SG_ 838 RLR_ElkOBJ4_Width  " ";
CM_ SG_ 838 RLR_ElkOBJ4_Type  " ";
CM_ SG_ 838 RLR_ElkOBJ4_Track_ID  " ";
CM_ SG_ 838 RLR_ElkOBJ3_RefPointLoc  " ";
CM_ SG_ 838 RLR_ElkOBJ3_RefPointDx  " ";
CM_ SG_ 838 RLR_ElkOBJ3_RefPointDy  " ";
CM_ SG_ 838 RLR_ElkOBJ3_ObstacleProb  " ";
CM_ SG_ 838 RLR_ElkOBJ3_Measured  " ";
CM_ SG_ 838 RLR_ElkOBJ3_ExistProb  " ";
CM_ SG_ 838 RLR_ElkOBJ3_Location  " ";
CM_ SG_ 838 RLR_ElkOBJ3_RelAx  " ";
CM_ SG_ 838 RLR_ElkOBJ3_RelAy  " ";
CM_ SG_ 838 RLR_ElkOBJ3_RelVx  " ";
CM_ SG_ 838 RLR_ElkOBJ3_RelVy  " ";
CM_ SG_ 838 RLR_ElkOBJ3_Dx  " ";
CM_ SG_ 838 RLR_ElkOBJ3_Dy  " ";
CM_ SG_ 838 RLR_ElkOBJ3_HeadingAngle  " ";
CM_ SG_ 838 RLR_ElkOBJ3_Length  " ";
CM_ SG_ 838 RLR_ElkOBJ3_Height  " ";
CM_ SG_ 838 RLR_ElkOBJ3_Width  " ";
CM_ SG_ 838 RLR_ElkOBJ3_Type  " ";
CM_ SG_ 838 RLR_ElkOBJ3_Track_ID  " ";

CM_ BO_ 836  " ";
CM_ SG_ 836 RRR_WorkMode  " ";
CM_ SG_ 836 RLR_WorkMode  " ";
CM_ SG_ 836 RLR_Left_ELK_oAlert  " ";
CM_ SG_ 836 RLR_ELK_oStatus  " ";
CM_ SG_ 836 RLR_ELK_oAlert  " ";

CM_ BO_ 1428  " ";
CM_ SG_ 1428 FR_NotSleep_BYTE7BIT1  " ";
CM_ SG_ 1428 FR_NotSleep_BYTE7BIT0  " ";
CM_ SG_ 1428 FR_WakeUp_BYTE4BIT1  " ";
CM_ SG_ 1428 FR_WakeUp_BYTE4BIT0  " ";

CM_ BO_ 384  "一、1-20的优先级：三角警示牌、锥形筒；
二、水马作为FS边界输出（C385） ";
CM_ SG_ 384 FC_StaticObj10_LaneAssi  " ";
CM_ SG_ 384 FC_StaticObj9_LaneAssi  " ";
CM_ SG_ 384 FC_StaticObj8_LaneAssi  " ";
CM_ SG_ 384 FC_StaticObj7_LaneAssi  " ";
CM_ SG_ 384 FC_StaticObj6_LaneAssi  " ";
CM_ SG_ 384 FC_StaticObj5_LaneAssi  " ";
CM_ SG_ 384 FC_StaticObj4_LaneAssi  " ";
CM_ SG_ 384 FC_StaticObj3_LaneAssi  " ";
CM_ SG_ 384 FC_StaticObj2_LaneAssi  " ";
CM_ SG_ 384 FC_StaticObj1_LaneAssi  " ";
CM_ SG_ 384 FC_StaticObj10_Track_ID  " ";
CM_ SG_ 384 FC_StaticObj9_Track_ID  " ";
CM_ SG_ 384 FC_StaticObj8_Track_ID  " ";
CM_ SG_ 384 FC_StaticObj7_Track_ID  " ";
CM_ SG_ 384 FC_StaticObj6_Track_ID  " ";
CM_ SG_ 384 FC_StaticObj5_Track_ID  " ";
CM_ SG_ 384 FC_StaticObj4_Track_ID  " ";
CM_ SG_ 384 FC_StaticObj3_Track_ID  " ";
CM_ SG_ 384 FC_StaticObj2_Track_ID  " ";
CM_ SG_ 384 FC_StaticObj1_Track_ID  " ";
CM_ SG_ 384 FC_StaticObj10_Dy  " ";
CM_ SG_ 384 FC_StaticObj9_Dy  " ";
CM_ SG_ 384 FC_StaticObj8_Dy  " ";
CM_ SG_ 384 FC_StaticObj7_Dy  " ";
CM_ SG_ 384 FC_StaticObj6_Dy  " ";
CM_ SG_ 384 FC_StaticObj5_Dy  " ";
CM_ SG_ 384 FC_StaticObj4_Dy  " ";
CM_ SG_ 384 FC_StaticObj3_Dy  " ";
CM_ SG_ 384 FC_StaticObj2_Dy  " ";
CM_ SG_ 384 FC_StaticObj1_Dy  " ";
CM_ SG_ 384 FC_StaticObj10_Dx  " ";
CM_ SG_ 384 FC_StaticObj9_Dx  " ";
CM_ SG_ 384 FC_StaticObj8_Dx  " ";
CM_ SG_ 384 FC_StaticObj7_Dx  " ";
CM_ SG_ 384 FC_StaticObj6_Dx  " ";
CM_ SG_ 384 FC_StaticObj5_Dx  " ";
CM_ SG_ 384 FC_StaticObj4_Dx  " ";
CM_ SG_ 384 FC_StaticObj3_Dx  " ";
CM_ SG_ 384 FC_StaticObj2_Dx  " ";
CM_ SG_ 384 FC_StaticObj1_Dx  " ";
CM_ SG_ 384 FC_CRCCheck_180  " ";
CM_ SG_ 384 FC_RollingCounter_180  " ";
CM_ SG_ 384 FC_StaticObj10_Type  " ";
CM_ SG_ 384 FC_StaticObj9_Type  " ";
CM_ SG_ 384 FC_StaticObj8_Type  " ";
CM_ SG_ 384 FC_StaticObj7_Type  " ";
CM_ SG_ 384 FC_StaticObj6_Type  " ";
CM_ SG_ 384 FC_StaticObj5_Type  " ";
CM_ SG_ 384 FC_StaticObj4_Type  " ";
CM_ SG_ 384 FC_StaticObj3_Type  " ";
CM_ SG_ 384 FC_StaticObj2_Type  " ";
CM_ SG_ 384 FC_StaticObj1_Type  " ";

CM_ BO_ 513  "时间帧，3帧，
周期100ms ";
CM_ SG_ 513 TC397_TimeSyncInit  "时间帧，3帧，
周期100ms ";

CM_ BO_ 497  " ";
CM_ SG_ 497 ADC_UTCTiVld  " ";
CM_ SG_ 497 ADC_UTCTiSec  " ";
CM_ SG_ 497 ADC_UTCTiMins  " ";
CM_ SG_ 497 ADC_UTCTiHr  " ";
CM_ SG_ 497 ADC_UTCTiDate  " ";
CM_ SG_ 497 ADC_UTCTiMth  " ";
CM_ SG_ 497 ADC_UTCTiYear  " ";

CM_ BO_ 498  " ";
CM_ SG_ 498 FC_UTCTiVld  " ";
CM_ SG_ 498 FC_UTCTiSec  " ";
CM_ SG_ 498 FC_UTCTiMins  " ";
CM_ SG_ 498 FC_UTCTiHr  " ";
CM_ SG_ 498 FC_UTCTiDate  " ";
CM_ SG_ 498 FC_UTCTiMth  " ";
CM_ SG_ 498 FC_UTCTiYear  " ";

CM_ BO_ 385  "一、1-20的优先级：三角警示牌、锥形筒；
二、水马作为FS边界输出（C385） ";
CM_ SG_ 385 FC_StaticObj20_LaneAssi  " ";
CM_ SG_ 385 FC_StaticObj19_LaneAssi  " ";
CM_ SG_ 385 FC_StaticObj18_LaneAssi  " ";
CM_ SG_ 385 FC_StaticObj17_LaneAssi  " ";
CM_ SG_ 385 FC_StaticObj16_LaneAssi  " ";
CM_ SG_ 385 FC_StaticObj15_LaneAssi  " ";
CM_ SG_ 385 FC_StaticObj14_LaneAssi  " ";
CM_ SG_ 385 FC_StaticObj13_LaneAssi  " ";
CM_ SG_ 385 FC_StaticObj12_LaneAssi  " ";
CM_ SG_ 385 FC_StaticObj11_LaneAssi  " ";
CM_ SG_ 385 FC_CRCCheck_181  " ";
CM_ SG_ 385 FC_RollingCounter_181  " ";
CM_ SG_ 385 FC_StaticObj20_Track_ID  " ";
CM_ SG_ 385 FC_StaticObj19_Track_ID  " ";
CM_ SG_ 385 FC_StaticObj18_Track_ID  " ";
CM_ SG_ 385 FC_StaticObj17_Track_ID  " ";
CM_ SG_ 385 FC_StaticObj16_Track_ID  " ";
CM_ SG_ 385 FC_StaticObj15_Track_ID  " ";
CM_ SG_ 385 FC_StaticObj14_Track_ID  " ";
CM_ SG_ 385 FC_StaticObj13_Track_ID  " ";
CM_ SG_ 385 FC_StaticObj12_Track_ID  " ";
CM_ SG_ 385 FC_StaticObj11_Track_ID  " ";
CM_ SG_ 385 FC_StaticObj20_Dy  " ";
CM_ SG_ 385 FC_StaticObj19_Dy  " ";
CM_ SG_ 385 FC_StaticObj18_Dy  " ";
CM_ SG_ 385 FC_StaticObj17_Dy  " ";
CM_ SG_ 385 FC_StaticObj16_Dy  " ";
CM_ SG_ 385 FC_StaticObj15_Dy  " ";
CM_ SG_ 385 FC_StaticObj14_Dy  " ";
CM_ SG_ 385 FC_StaticObj13_Dy  " ";
CM_ SG_ 385 FC_StaticObj12_Dy  " ";
CM_ SG_ 385 FC_StaticObj11_Dy  " ";
CM_ SG_ 385 FC_StaticObj20_Dx  " ";
CM_ SG_ 385 FC_StaticObj19_Dx  " ";
CM_ SG_ 385 FC_StaticObj18_Dx  " ";
CM_ SG_ 385 FC_StaticObj17_Dx  " ";
CM_ SG_ 385 FC_StaticObj16_Dx  " ";
CM_ SG_ 385 FC_StaticObj15_Dx  " ";
CM_ SG_ 385 FC_StaticObj14_Dx  " ";
CM_ SG_ 385 FC_StaticObj13_Dx  " ";
CM_ SG_ 385 FC_StaticObj12_Dx  " ";
CM_ SG_ 385 FC_StaticObj11_Dx  " ";
CM_ SG_ 385 FC_StaticObj20_Type  " ";
CM_ SG_ 385 FC_StaticObj19_Type  " ";
CM_ SG_ 385 FC_StaticObj18_Type  " ";
CM_ SG_ 385 FC_StaticObj17_Type  " ";
CM_ SG_ 385 FC_StaticObj16_Type  " ";
CM_ SG_ 385 FC_StaticObj15_Type  " ";
CM_ SG_ 385 FC_StaticObj14_Type  " ";
CM_ SG_ 385 FC_StaticObj13_Type  " ";
CM_ SG_ 385 FC_StaticObj12_Type  " ";
CM_ SG_ 385 FC_StaticObj11_Type  " ";

CM_ BO_ 1893  "物理寻址 ";

CM_ BO_ 1901  "物理寻址 ";

CM_ BO_ 1937  "物理寻址 ";

CM_ BO_ 1945  "物理寻址 ";

CM_ BO_ 2015  "功能寻址 ";

BA_DEF_ SG_  "GenSigStartValue" INT 0 0;
BA_DEF_ SG_  "GenSigInvalidValue" STRING  ;
BA_DEF_ SG_  "GenSigCycleTime" INT 0 0;
BA_DEF_ SG_  "GenSigSendType" ENUM  "Cyclic","OnWrite","OnWriteWithRepetition","OnChange","OnChangeWithRepetition","IfActive","IfActiveWithRepetition","NoSigSendType","NotUsed","NotUsed","NotUsed","NotUsed","NotUsed";
BA_DEF_ BO_  "GenMsgSendType" ENUM  "Cyclic","Event","NotUsed","NotUsed","NotUsed","Cyclic","NotUsed","IfActive","NoMsgSendType","NotUsed";
BA_DEF_ BO_  "GenMsgILSupport" ENUM  "No","Yes";
BA_DEF_ BO_  "GenMsgCycleTime" INT 0 65535;
BA_DEF_ BO_  "CANFD_BRS" ENUM  "0","1";
BA_DEF_ BO_  "VFrameFormat" ENUM  "StandardCAN","ExtendedCAN","reserved","reserved","reserved","reserved","reserved","reserved","reserved","reserved","reserved","reserved","reserved","reserved","StandardCAN_FD","ExtendedCAN_FD";
BA_DEF_DEF_  "GenSigStartValue" 0;
BA_DEF_DEF_  "GenSigInvalidValue" "/";
BA_DEF_DEF_  "GenSigCycleTime" 0;
BA_DEF_DEF_  "GenSigSendType" "Cyclic";
BA_DEF_DEF_  "GenMsgSendType" "NoMsgSendType";
BA_DEF_DEF_  "GenMsgILSupport" "Yes";
BA_DEF_DEF_  "GenMsgCycleTime" 0;
BA_DEF_DEF_  "CANFD_BRS" "1";
BA_DEF_DEF_  "VFrameFormat" "StandardCAN";
BA_ "GenMsgCycleTime" BO_ 373 60;
BA_ "GenMsgSendType" BO_ 373 0;
BA_ "VFrameFormat" BO_ 373 14;
BA_ "GenMsgCycleTime" BO_ 374 60;
BA_ "GenMsgSendType" BO_ 374 0;
BA_ "VFrameFormat" BO_ 374 14;
BA_ "GenMsgCycleTime" BO_ 375 60;
BA_ "GenMsgSendType" BO_ 375 0;
BA_ "VFrameFormat" BO_ 375 14;
BA_ "GenMsgCycleTime" BO_ 376 60;
BA_ "GenMsgSendType" BO_ 376 0;
BA_ "VFrameFormat" BO_ 376 14;
BA_ "GenMsgCycleTime" BO_ 377 60;
BA_ "GenMsgSendType" BO_ 377 0;
BA_ "VFrameFormat" BO_ 377 14;
BA_ "GenMsgCycleTime" BO_ 400 60;
BA_ "GenMsgSendType" BO_ 400 0;
BA_ "VFrameFormat" BO_ 400 14;
BA_ "GenMsgCycleTime" BO_ 403 60;
BA_ "GenMsgSendType" BO_ 403 0;
BA_ "VFrameFormat" BO_ 403 14;
BA_ "GenMsgCycleTime" BO_ 405 60;
BA_ "GenMsgSendType" BO_ 405 0;
BA_ "VFrameFormat" BO_ 405 14;
BA_ "GenMsgCycleTime" BO_ 406 60;
BA_ "GenMsgSendType" BO_ 406 0;
BA_ "VFrameFormat" BO_ 406 14;
BA_ "GenMsgCycleTime" BO_ 407 100;
BA_ "GenMsgSendType" BO_ 407 0;
BA_ "VFrameFormat" BO_ 407 14;
BA_ "GenMsgCycleTime" BO_ 408 100;
BA_ "GenMsgSendType" BO_ 408 0;
BA_ "VFrameFormat" BO_ 408 14;
BA_ "GenMsgCycleTime" BO_ 516 500;
BA_ "GenMsgSendType" BO_ 516 0;
BA_ "VFrameFormat" BO_ 516 14;
BA_ "GenMsgCycleTime" BO_ 264 20;
BA_ "GenMsgSendType" BO_ 264 0;
BA_ "VFrameFormat" BO_ 264 14;
BA_ "GenMsgCycleTime" BO_ 263 10;
BA_ "GenMsgSendType" BO_ 263 0;
BA_ "VFrameFormat" BO_ 263 14;
BA_ "GenMsgCycleTime" BO_ 261 10;
BA_ "GenMsgSendType" BO_ 261 0;
BA_ "VFrameFormat" BO_ 261 14;
BA_ "GenMsgCycleTime" BO_ 512 500;
BA_ "GenMsgSendType" BO_ 512 0;
BA_ "VFrameFormat" BO_ 512 14;
BA_ "GenMsgSendType" BO_ 1107 1;
BA_ "VFrameFormat" BO_ 1107 14;
BA_ "GenMsgSendType" BO_ 1104 1;
BA_ "VFrameFormat" BO_ 1104 14;
BA_ "GenMsgCycleTime" BO_ 411 100;
BA_ "GenMsgSendType" BO_ 411 0;
BA_ "VFrameFormat" BO_ 411 14;
BA_ "GenMsgCycleTime" BO_ 518 1000;
BA_ "GenMsgSendType" BO_ 518 0;
BA_ "VFrameFormat" BO_ 518 14;
BA_ "GenMsgCycleTime" BO_ 519 1000;
BA_ "GenMsgSendType" BO_ 519 0;
BA_ "VFrameFormat" BO_ 519 14;
BA_ "GenMsgCycleTime" BO_ 837 50;
BA_ "GenMsgSendType" BO_ 837 0;
BA_ "VFrameFormat" BO_ 837 14;
BA_ "GenMsgCycleTime" BO_ 838 50;
BA_ "GenMsgSendType" BO_ 838 0;
BA_ "VFrameFormat" BO_ 838 14;
BA_ "GenMsgCycleTime" BO_ 836 50;
BA_ "GenMsgSendType" BO_ 836 0;
BA_ "VFrameFormat" BO_ 836 14;
BA_ "GenMsgCycleTime" BO_ 1428 1000;
BA_ "GenMsgSendType" BO_ 1428 0;
BA_ "VFrameFormat" BO_ 1428 14;
BA_ "GenMsgCycleTime" BO_ 384 60;
BA_ "GenMsgSendType" BO_ 384 0;
BA_ "VFrameFormat" BO_ 384 14;
BA_ "GenMsgSendType" BO_ 513 1;
BA_ "VFrameFormat" BO_ 513 14;
BA_ "GenMsgCycleTime" BO_ 497 100;
BA_ "GenMsgSendType" BO_ 497 0;
BA_ "VFrameFormat" BO_ 497 14;
BA_ "GenMsgCycleTime" BO_ 498 100;
BA_ "GenMsgSendType" BO_ 498 0;
BA_ "VFrameFormat" BO_ 498 14;
BA_ "GenMsgCycleTime" BO_ 385 60;
BA_ "GenMsgSendType" BO_ 385 0;
BA_ "VFrameFormat" BO_ 385 14;
BA_ "GenMsgSendType" BO_ 1893 1;
BA_ "VFrameFormat" BO_ 1893 14;
BA_ "GenMsgSendType" BO_ 1901 1;
BA_ "VFrameFormat" BO_ 1901 14;
BA_ "GenMsgSendType" BO_ 1937 1;
BA_ "VFrameFormat" BO_ 1937 14;
BA_ "GenMsgSendType" BO_ 1945 1;
BA_ "VFrameFormat" BO_ 1945 14;
BA_ "GenMsgSendType" BO_ 2015 1;
BA_ "VFrameFormat" BO_ 2015 14;

BA_ "GenSigCycleTime" SG_ 373 FC_Obj16WSInfoPosType 60;
BA_ "GenSigCycleTime" SG_ 373 FC_CRCCheck_175 60;
BA_ "GenSigCycleTime" SG_ 373 FC_RollingCounter_175 60;
BA_ "GenSigCycleTime" SG_ 373 FC_Obj16_Img2dBox_RightDown_V 60;
BA_ "GenSigCycleTime" SG_ 373 FC_Obj16_Img2dBox_LeftTop_V 60;
BA_ "GenSigCycleTime" SG_ 373 FC_Obj16_Img2dBox_RightDown_U 60;
BA_ "GenSigCycleTime" SG_ 373 FC_Obj16_Img2dBox_LeftTop_U 60;
BA_ "GenSigCycleTime" SG_ 373 FC_Obj16_TurnLight 60;
BA_ "GenSigCycleTime" SG_ 373 FC_Obj16_valid 60;
BA_ "GenSigCycleTime" SG_ 373 FC_Obj16_Vy_Vnce 60;
BA_ "GenSigCycleTime" SG_ 373 FC_Obj16_Vx_Vnce 60;
BA_ "GenSigCycleTime" SG_ 373 FC_Obj16_CenterAngle 60;
BA_ "GenSigCycleTime" SG_ 373 FC_Obj16_DistInLane 60;
BA_ "GenSigCycleTime" SG_ 373 FC_Obj16_objCutInLane 60;
BA_ "GenSigCycleTime" SG_ 373 FC_Obj16_objCutInFlag 60;
BA_ "GenSigCycleTime" SG_ 373 FC_Obj16_CornerPoint_y 60;
BA_ "GenSigCycleTime" SG_ 373 FC_Obj16_CornerPoint_x 60;
BA_ "GenSigCycleTime" SG_ 373 FC_Obj16_LaneAssignment 60;
BA_ "GenSigCycleTime" SG_ 373 FC_Obj16_MotionType 60;
BA_ "GenSigCycleTime" SG_ 373 FC_obj16_Brakelight_Info 60;
BA_ "GenSigCycleTime" SG_ 373 FC_Obj16_Width 60;
BA_ "GenSigCycleTime" SG_ 373 FC_Obj16_Length 60;
BA_ "GenSigCycleTime" SG_ 373 FC_Obj16_Height 60;
BA_ "GenSigCycleTime" SG_ 373 FC_Obj16_HeadOrientation 60;
BA_ "GenSigCycleTime" SG_ 373 FC_Obj16_HeadingAngle 60;
BA_ "GenSigCycleTime" SG_ 373 FC_Obj16_ExistProb 60;
BA_ "GenSigCycleTime" SG_ 373 FC_Obj16_Dy_Vnce 60;
BA_ "GenSigCycleTime" SG_ 373 FC_Obj16_Dy 60;
BA_ "GenSigCycleTime" SG_ 373 FC_Obj16_Dx_Vnce 60;
BA_ "GenSigCycleTime" SG_ 373 FC_Obj16_Dx 60;
BA_ "GenSigCycleTime" SG_ 373 FC_Obj16_RelVy 60;
BA_ "GenSigCycleTime" SG_ 373 FC_Obj16_RelVx 60;
BA_ "GenSigCycleTime" SG_ 373 FC_Obj16_RelAy 60;
BA_ "GenSigCycleTime" SG_ 373 FC_Obj16_RelAx 60;
BA_ "GenSigCycleTime" SG_ 373 FC_Obj16_TypeProb 60;
BA_ "GenSigCycleTime" SG_ 373 FC_Obj16_Type 60;
BA_ "GenSigCycleTime" SG_ 373 FC_Obj16_Track_Age 60;
BA_ "GenSigCycleTime" SG_ 373 FC_Obj16_Track_ID 60;

BA_ "GenSigCycleTime" SG_ 374 FC_Obj17WSInfoPosType 60;
BA_ "GenSigCycleTime" SG_ 374 FC_CRCCheck_176 60;
BA_ "GenSigCycleTime" SG_ 374 FC_RollingCounter_176 60;
BA_ "GenSigCycleTime" SG_ 374 FC_Obj17_Img2dBox_RightDown_V 60;
BA_ "GenSigCycleTime" SG_ 374 FC_Obj17_Img2dBox_LeftTop_V 60;
BA_ "GenSigCycleTime" SG_ 374 FC_Obj17_Img2dBox_RightDown_U 60;
BA_ "GenSigCycleTime" SG_ 374 FC_Obj17_Img2dBox_LeftTop_U 60;
BA_ "GenSigCycleTime" SG_ 374 FC_Obj17_TurnLight 60;
BA_ "GenSigCycleTime" SG_ 374 FC_Obj17_valid 60;
BA_ "GenSigCycleTime" SG_ 374 FC_Obj17_Vy_Vnce 60;
BA_ "GenSigCycleTime" SG_ 374 FC_Obj17_Vx_Vnce 60;
BA_ "GenSigCycleTime" SG_ 374 FC_Obj17_CenterAngle 60;
BA_ "GenSigCycleTime" SG_ 374 FC_Obj17_DistInLane 60;
BA_ "GenSigCycleTime" SG_ 374 FC_Obj17_objCutInLane 60;
BA_ "GenSigCycleTime" SG_ 374 FC_Obj17_objCutInFlag 60;
BA_ "GenSigCycleTime" SG_ 374 FC_Obj17_CornerPoint_y 60;
BA_ "GenSigCycleTime" SG_ 374 FC_Obj17_CornerPoint_x 60;
BA_ "GenSigCycleTime" SG_ 374 FC_Obj17_LaneAssignment 60;
BA_ "GenSigCycleTime" SG_ 374 FC_Obj17_MotionType 60;
BA_ "GenSigCycleTime" SG_ 374 FC_obj17_Brakelight_Info 60;
BA_ "GenSigCycleTime" SG_ 374 FC_Obj17_Width 60;
BA_ "GenSigCycleTime" SG_ 374 FC_Obj17_Length 60;
BA_ "GenSigCycleTime" SG_ 374 FC_Obj17_Height 60;
BA_ "GenSigCycleTime" SG_ 374 FC_Obj17_HeadOrientation 60;
BA_ "GenSigCycleTime" SG_ 374 FC_Obj17_HeadingAngle 60;
BA_ "GenSigCycleTime" SG_ 374 FC_Obj17_ExistProb 60;
BA_ "GenSigCycleTime" SG_ 374 FC_Obj17_Dy_Vnce 60;
BA_ "GenSigCycleTime" SG_ 374 FC_Obj17_Dy 60;
BA_ "GenSigCycleTime" SG_ 374 FC_Obj17_Dx_Vnce 60;
BA_ "GenSigCycleTime" SG_ 374 FC_Obj17_Dx 60;
BA_ "GenSigCycleTime" SG_ 374 FC_Obj17_RelVy 60;
BA_ "GenSigCycleTime" SG_ 374 FC_Obj17_RelVx 60;
BA_ "GenSigCycleTime" SG_ 374 FC_Obj17_RelAy 60;
BA_ "GenSigCycleTime" SG_ 374 FC_Obj17_RelAx 60;
BA_ "GenSigCycleTime" SG_ 374 FC_Obj17_TypeProb 60;
BA_ "GenSigCycleTime" SG_ 374 FC_Obj17_Type 60;
BA_ "GenSigCycleTime" SG_ 374 FC_Obj17_Track_Age 60;
BA_ "GenSigCycleTime" SG_ 374 FC_Obj17_Track_ID 60;

BA_ "GenSigCycleTime" SG_ 375 FC_Obj18WSInfoPosType 60;
BA_ "GenSigCycleTime" SG_ 375 FC_CRCCheck_177 60;
BA_ "GenSigCycleTime" SG_ 375 FC_RollingCounter_177 60;
BA_ "GenSigCycleTime" SG_ 375 FC_Obj18_Img2dBox_RightDown_V 60;
BA_ "GenSigCycleTime" SG_ 375 FC_Obj18_Img2dBox_LeftTop_V 60;
BA_ "GenSigCycleTime" SG_ 375 FC_Obj18_Img2dBox_RightDown_U 60;
BA_ "GenSigCycleTime" SG_ 375 FC_Obj18_Img2dBox_LeftTop_U 60;
BA_ "GenSigCycleTime" SG_ 375 FC_Obj18_TurnLight 60;
BA_ "GenSigCycleTime" SG_ 375 FC_Obj18_valid 60;
BA_ "GenSigCycleTime" SG_ 375 FC_Obj18_Vy_Vnce 60;
BA_ "GenSigCycleTime" SG_ 375 FC_Obj18_Vx_Vnce 60;
BA_ "GenSigCycleTime" SG_ 375 FC_Obj18_CenterAngle 60;
BA_ "GenSigCycleTime" SG_ 375 FC_Obj18_DistInLane 60;
BA_ "GenSigCycleTime" SG_ 375 FC_Obj18_objCutInLane 60;
BA_ "GenSigCycleTime" SG_ 375 FC_Obj18_objCutInFlag 60;
BA_ "GenSigCycleTime" SG_ 375 FC_Obj18_CornerPoint_y 60;
BA_ "GenSigCycleTime" SG_ 375 FC_Obj18_CornerPoint_x 60;
BA_ "GenSigCycleTime" SG_ 375 FC_Obj18_LaneAssignment 60;
BA_ "GenSigCycleTime" SG_ 375 FC_Obj18_MotionType 60;
BA_ "GenSigCycleTime" SG_ 375 FC_obj18_Brakelight_Info 60;
BA_ "GenSigCycleTime" SG_ 375 FC_Obj18_Width 60;
BA_ "GenSigCycleTime" SG_ 375 FC_Obj18_Length 60;
BA_ "GenSigCycleTime" SG_ 375 FC_Obj18_Height 60;
BA_ "GenSigCycleTime" SG_ 375 FC_Obj18_HeadOrientation 60;
BA_ "GenSigCycleTime" SG_ 375 FC_Obj18_HeadingAngle 60;
BA_ "GenSigCycleTime" SG_ 375 FC_Obj18_ExistProb 60;
BA_ "GenSigCycleTime" SG_ 375 FC_Obj18_Dy_Vnce 60;
BA_ "GenSigCycleTime" SG_ 375 FC_Obj18_Dy 60;
BA_ "GenSigCycleTime" SG_ 375 FC_Obj18_Dx_Vnce 60;
BA_ "GenSigCycleTime" SG_ 375 FC_Obj18_Dx 60;
BA_ "GenSigCycleTime" SG_ 375 FC_Obj18_RelVy 60;
BA_ "GenSigCycleTime" SG_ 375 FC_Obj18_RelVx 60;
BA_ "GenSigCycleTime" SG_ 375 FC_Obj18_RelAy 60;
BA_ "GenSigCycleTime" SG_ 375 FC_Obj18_RelAx 60;
BA_ "GenSigCycleTime" SG_ 375 FC_Obj18_TypeProb 60;
BA_ "GenSigCycleTime" SG_ 375 FC_Obj18_Type 60;
BA_ "GenSigCycleTime" SG_ 375 FC_Obj18_Track_Age 60;
BA_ "GenSigCycleTime" SG_ 375 FC_Obj18_Track_ID 60;

BA_ "GenSigCycleTime" SG_ 376 FC_Obj19WSInfoPosType 60;
BA_ "GenSigCycleTime" SG_ 376 FC_CRCCheck_178 60;
BA_ "GenSigCycleTime" SG_ 376 FC_RollingCounter_178 60;
BA_ "GenSigCycleTime" SG_ 376 FC_Obj19_Img2dBox_RightDown_V 60;
BA_ "GenSigCycleTime" SG_ 376 FC_Obj19_Img2dBox_LeftTop_V 60;
BA_ "GenSigCycleTime" SG_ 376 FC_Obj19_Img2dBox_RightDown_U 60;
BA_ "GenSigCycleTime" SG_ 376 FC_Obj19_Img2dBox_LeftTop_U 60;
BA_ "GenSigCycleTime" SG_ 376 FC_Obj19_TurnLight 60;
BA_ "GenSigCycleTime" SG_ 376 FC_Obj19_valid 60;
BA_ "GenSigCycleTime" SG_ 376 FC_Obj19_Vy_Vnce 60;
BA_ "GenSigCycleTime" SG_ 376 FC_Obj19_Vx_Vnce 60;
BA_ "GenSigCycleTime" SG_ 376 FC_Obj19_CenterAngle 60;
BA_ "GenSigCycleTime" SG_ 376 FC_Obj19_DistInLane 60;
BA_ "GenSigCycleTime" SG_ 376 FC_Obj19_objCutInLane 60;
BA_ "GenSigCycleTime" SG_ 376 FC_Obj19_objCutInFlag 60;
BA_ "GenSigCycleTime" SG_ 376 FC_Obj19_CornerPoint_y 60;
BA_ "GenSigCycleTime" SG_ 376 FC_Obj19_CornerPoint_x 60;
BA_ "GenSigCycleTime" SG_ 376 FC_Obj19_LaneAssignment 60;
BA_ "GenSigCycleTime" SG_ 376 FC_Obj19_MotionType 60;
BA_ "GenSigCycleTime" SG_ 376 FC_obj19_Brakelight_Info 60;
BA_ "GenSigCycleTime" SG_ 376 FC_Obj19_Width 60;
BA_ "GenSigCycleTime" SG_ 376 FC_Obj19_Length 60;
BA_ "GenSigCycleTime" SG_ 376 FC_Obj19_Height 60;
BA_ "GenSigCycleTime" SG_ 376 FC_Obj19_HeadOrientation 60;
BA_ "GenSigCycleTime" SG_ 376 FC_Obj19_HeadingAngle 60;
BA_ "GenSigCycleTime" SG_ 376 FC_Obj19_ExistProb 60;
BA_ "GenSigCycleTime" SG_ 376 FC_Obj19_Dy_Vnce 60;
BA_ "GenSigCycleTime" SG_ 376 FC_Obj19_Dy 60;
BA_ "GenSigCycleTime" SG_ 376 FC_Obj19_Dx_Vnce 60;
BA_ "GenSigCycleTime" SG_ 376 FC_Obj19_Dx 60;
BA_ "GenSigCycleTime" SG_ 376 FC_Obj19_RelVy 60;
BA_ "GenSigCycleTime" SG_ 376 FC_Obj19_RelVx 60;
BA_ "GenSigCycleTime" SG_ 376 FC_Obj19_RelAy 60;
BA_ "GenSigCycleTime" SG_ 376 FC_Obj19_RelAx 60;
BA_ "GenSigCycleTime" SG_ 376 FC_Obj19_TypeProb 60;
BA_ "GenSigCycleTime" SG_ 376 FC_Obj19_Type 60;
BA_ "GenSigCycleTime" SG_ 376 FC_Obj19_Track_Age 60;
BA_ "GenSigCycleTime" SG_ 376 FC_Obj19_Track_ID 60;

BA_ "GenSigCycleTime" SG_ 377 FC_Obj20WSInfoPosType 60;
BA_ "GenSigCycleTime" SG_ 377 FC_CRCCheck_179 60;
BA_ "GenSigCycleTime" SG_ 377 FC_RollingCounter_179 60;
BA_ "GenSigCycleTime" SG_ 377 FC_Obj20_Img2dBox_RightDown_V 60;
BA_ "GenSigCycleTime" SG_ 377 FC_Obj20_Img2dBox_LeftTop_V 60;
BA_ "GenSigCycleTime" SG_ 377 FC_Obj20_Img2dBox_RightDown_U 60;
BA_ "GenSigCycleTime" SG_ 377 FC_Obj20_Img2dBox_LeftTop_U 60;
BA_ "GenSigCycleTime" SG_ 377 FC_Obj20_TurnLight 60;
BA_ "GenSigCycleTime" SG_ 377 FC_Obj20_valid 60;
BA_ "GenSigCycleTime" SG_ 377 FC_Obj20_Vy_Vnce 60;
BA_ "GenSigCycleTime" SG_ 377 FC_Obj20_Vx_Vnce 60;
BA_ "GenSigCycleTime" SG_ 377 FC_Obj20_CenterAngle 60;
BA_ "GenSigCycleTime" SG_ 377 FC_Obj20_DistInLane 60;
BA_ "GenSigCycleTime" SG_ 377 FC_Obj20_objCutInLane 60;
BA_ "GenSigCycleTime" SG_ 377 FC_Obj20_objCutInFlag 60;
BA_ "GenSigCycleTime" SG_ 377 FC_Obj20_CornerPoint_y 60;
BA_ "GenSigCycleTime" SG_ 377 FC_Obj20_CornerPoint_x 60;
BA_ "GenSigCycleTime" SG_ 377 FC_Obj20_LaneAssignment 60;
BA_ "GenSigCycleTime" SG_ 377 FC_Obj20_MotionType 60;
BA_ "GenSigCycleTime" SG_ 377 FC_obj20_Brakelight_Info 60;
BA_ "GenSigCycleTime" SG_ 377 FC_Obj20_Width 60;
BA_ "GenSigCycleTime" SG_ 377 FC_Obj20_Length 60;
BA_ "GenSigCycleTime" SG_ 377 FC_Obj20_Height 60;
BA_ "GenSigCycleTime" SG_ 377 FC_Obj20_HeadOrientation 60;
BA_ "GenSigCycleTime" SG_ 377 FC_Obj20_HeadingAngle 60;
BA_ "GenSigCycleTime" SG_ 377 FC_Obj20_ExistProb 60;
BA_ "GenSigCycleTime" SG_ 377 FC_Obj20_Dy_Vnce 60;
BA_ "GenSigCycleTime" SG_ 377 FC_Obj20_Dy 60;
BA_ "GenSigCycleTime" SG_ 377 FC_Obj20_Dx_Vnce 60;
BA_ "GenSigCycleTime" SG_ 377 FC_Obj20_Dx 60;
BA_ "GenSigCycleTime" SG_ 377 FC_Obj20_RelVy 60;
BA_ "GenSigCycleTime" SG_ 377 FC_Obj20_RelVx 60;
BA_ "GenSigCycleTime" SG_ 377 FC_Obj20_RelAy 60;
BA_ "GenSigCycleTime" SG_ 377 FC_Obj20_RelAx 60;
BA_ "GenSigCycleTime" SG_ 377 FC_Obj20_TypeProb 60;
BA_ "GenSigCycleTime" SG_ 377 FC_Obj20_Type 60;
BA_ "GenSigCycleTime" SG_ 377 FC_Obj20_Track_Age 60;
BA_ "GenSigCycleTime" SG_ 377 FC_Obj20_Track_ID 60;

BA_ "GenSigCycleTime" SG_ 400 FC_SenceMode 60;
BA_ "GenSigCycleTime" SG_ 400 FC_WorkMode 60;
BA_ "GenSigCycleTime" SG_ 400 FC_CRCCheck_190 60;
BA_ "GenSigCycleTime" SG_ 400 FC_RollingCounter_190 60;
BA_ "GenSigCycleTime" SG_ 400 FC_FrameID 60;
BA_ "GenSigCycleTime" SG_ 400 FC_CameraFailureStatus 60;
BA_ "GenSigInvalidValue" SG_ 400 FC_CameraFailureStatus "7";
BA_ "GenSigCycleTime" SG_ 400 FC_CameraCalibrationStatus 60;
BA_ "GenSigInvalidValue" SG_ 400 FC_CameraCalibrationStatus "3";
BA_ "GenSigCycleTime" SG_ 400 FC_CIPVFlag 60;
BA_ "GenSigCycleTime" SG_ 400 FC_CIPV_ID 60;

BA_ "GenSigCycleTime" SG_ 403 ADC_CRCCheck_193 60;
BA_ "GenSigCycleTime" SG_ 403 ADC_RollingCounter_193 60;
BA_ "GenSigCycleTime" SG_ 403 FC_ObjMCUTiStamp 60;
BA_ "GenSigCycleTime" SG_ 403 FC_ObjTiOut 60;
BA_ "GenSigCycleTime" SG_ 403 FC_ObjTiLeap 60;
BA_ "GenSigCycleTime" SG_ 403 FC_ObjTiBas 60;
BA_ "GenSigCycleTime" SG_ 403 FC_ObjTiStamp 60;

BA_ "GenSigCycleTime" SG_ 405 FC_CRCCheck_195 60;
BA_ "GenSigCycleTime" SG_ 405 FC_RollingCounter_195 60;
BA_ "GenSigCycleTime" SG_ 405 FC_TLA4_ShapeType 60;
BA_ "GenSigInvalidValue" SG_ 405 FC_TLA4_ShapeType "3";
BA_ "GenSigCycleTime" SG_ 405 FC_TLA4_BlindingStatus 60;
BA_ "GenSigCycleTime" SG_ 405 FC_TLA4_Confidence 60;
BA_ "GenSigCycleTime" SG_ 405 FC_TLA4_PosZ 60;
BA_ "GenSigCycleTime" SG_ 405 FC_TLA4_PosY 60;
BA_ "GenSigCycleTime" SG_ 405 FC_TLA4_PosX 60;
BA_ "GenSigCycleTime" SG_ 405 FC_TLA4_direction 60;
BA_ "GenSigInvalidValue" SG_ 405 FC_TLA4_direction "15";
BA_ "GenSigCycleTime" SG_ 405 FC_TLA4_Color 60;
BA_ "GenSigInvalidValue" SG_ 405 FC_TLA4_Color "7";
BA_ "GenSigCycleTime" SG_ 405 FC_TLA4_ClassificationType 60;
BA_ "GenSigInvalidValue" SG_ 405 FC_TLA4_ClassificationType "7";
BA_ "GenSigCycleTime" SG_ 405 FC_TLA3_ShapeType 60;
BA_ "GenSigInvalidValue" SG_ 405 FC_TLA3_ShapeType "3";
BA_ "GenSigCycleTime" SG_ 405 FC_TLA3_BlindingStatus 60;
BA_ "GenSigCycleTime" SG_ 405 FC_TLA3_Confidence 60;
BA_ "GenSigCycleTime" SG_ 405 FC_TLA3_PosZ 60;
BA_ "GenSigCycleTime" SG_ 405 FC_TLA3_PosY 60;
BA_ "GenSigCycleTime" SG_ 405 FC_TLA3_PosX 60;
BA_ "GenSigCycleTime" SG_ 405 FC_TLA3_direction 60;
BA_ "GenSigInvalidValue" SG_ 405 FC_TLA3_direction "15";
BA_ "GenSigCycleTime" SG_ 405 FC_TLA3_Color 60;
BA_ "GenSigInvalidValue" SG_ 405 FC_TLA3_Color "7";
BA_ "GenSigCycleTime" SG_ 405 FC_TLA3_ClassificationType 60;
BA_ "GenSigInvalidValue" SG_ 405 FC_TLA3_ClassificationType "7";
BA_ "GenSigCycleTime" SG_ 405 FC_TLA2_ShapeType 60;
BA_ "GenSigInvalidValue" SG_ 405 FC_TLA2_ShapeType "3";
BA_ "GenSigCycleTime" SG_ 405 FC_TLA2_BlindingStatus 60;
BA_ "GenSigCycleTime" SG_ 405 FC_TLA2_Confidence 60;
BA_ "GenSigCycleTime" SG_ 405 FC_TLA2_PosZ 60;
BA_ "GenSigCycleTime" SG_ 405 FC_TLA2_PosY 60;
BA_ "GenSigCycleTime" SG_ 405 FC_TLA2_PosX 60;
BA_ "GenSigCycleTime" SG_ 405 FC_TLA2_direction 60;
BA_ "GenSigInvalidValue" SG_ 405 FC_TLA2_direction "15";
BA_ "GenSigCycleTime" SG_ 405 FC_TLA2_Color 60;
BA_ "GenSigInvalidValue" SG_ 405 FC_TLA2_Color "7";
BA_ "GenSigCycleTime" SG_ 405 FC_TLA2_ClassificationType 60;
BA_ "GenSigInvalidValue" SG_ 405 FC_TLA2_ClassificationType "7";
BA_ "GenSigCycleTime" SG_ 405 FC_TLA1_ShapeType 60;
BA_ "GenSigInvalidValue" SG_ 405 FC_TLA1_ShapeType "3";
BA_ "GenSigCycleTime" SG_ 405 FC_TLA1_BlindingStatus 60;
BA_ "GenSigCycleTime" SG_ 405 FC_TLA1_Confidence 60;
BA_ "GenSigCycleTime" SG_ 405 FC_TLA1_PosZ 60;
BA_ "GenSigCycleTime" SG_ 405 FC_TLA1_PosY 60;
BA_ "GenSigCycleTime" SG_ 405 FC_TLA1_PosX 60;
BA_ "GenSigCycleTime" SG_ 405 FC_TLA1_direction 60;
BA_ "GenSigInvalidValue" SG_ 405 FC_TLA1_direction "15";
BA_ "GenSigCycleTime" SG_ 405 FC_TLA1_Color 60;
BA_ "GenSigInvalidValue" SG_ 405 FC_TLA1_Color "7";
BA_ "GenSigCycleTime" SG_ 405 FC_TLA1_ClassificationType 60;
BA_ "GenSigInvalidValue" SG_ 405 FC_TLA1_ClassificationType "7";

BA_ "GenSigCycleTime" SG_ 406 FC_CRCCheck_196 60;
BA_ "GenSigCycleTime" SG_ 406 FC_RollingCounter_196 60;
BA_ "GenSigCycleTime" SG_ 406 FC_TFLMCUTiStamp 60;
BA_ "GenSigCycleTime" SG_ 406 FC_TFLTiOut 60;
BA_ "GenSigCycleTime" SG_ 406 FC_TFLTiLeap 60;
BA_ "GenSigCycleTime" SG_ 406 FC_TFLTiBas 60;
BA_ "GenSigCycleTime" SG_ 406 FC_TFLTiStamp 60;
BA_ "GenSigCycleTime" SG_ 406 FC_TLAMainObjectID 60;
BA_ "GenSigCycleTime" SG_ 406 FC_TLAObjectsNumber 60;
BA_ "GenSigCycleTime" SG_ 406 FC_TLA8_ShapeType 60;
BA_ "GenSigInvalidValue" SG_ 406 FC_TLA8_ShapeType "3";
BA_ "GenSigCycleTime" SG_ 406 FC_TLA8_BlindingStatus 60;
BA_ "GenSigCycleTime" SG_ 406 FC_TLA8_Confidence 60;
BA_ "GenSigCycleTime" SG_ 406 FC_TLA8_PosZ 60;
BA_ "GenSigCycleTime" SG_ 406 FC_TLA8_PosY 60;
BA_ "GenSigCycleTime" SG_ 406 FC_TLA8_PosX 60;
BA_ "GenSigCycleTime" SG_ 406 FC_TLA8_direction 60;
BA_ "GenSigInvalidValue" SG_ 406 FC_TLA8_direction "15";
BA_ "GenSigCycleTime" SG_ 406 FC_TLA8_Color 60;
BA_ "GenSigInvalidValue" SG_ 406 FC_TLA8_Color "7";
BA_ "GenSigCycleTime" SG_ 406 FC_TLA8_ClassificationType 60;
BA_ "GenSigInvalidValue" SG_ 406 FC_TLA8_ClassificationType "7";
BA_ "GenSigCycleTime" SG_ 406 FC_TLA7_ShapeType 60;
BA_ "GenSigInvalidValue" SG_ 406 FC_TLA7_ShapeType "3";
BA_ "GenSigCycleTime" SG_ 406 FC_TLA7_BlindingStatus 60;
BA_ "GenSigCycleTime" SG_ 406 FC_TLA7_Confidence 60;
BA_ "GenSigCycleTime" SG_ 406 FC_TLA7_PosZ 60;
BA_ "GenSigCycleTime" SG_ 406 FC_TLA7_PosY 60;
BA_ "GenSigCycleTime" SG_ 406 FC_TLA7_PosX 60;
BA_ "GenSigCycleTime" SG_ 406 FC_TLA7_direction 60;
BA_ "GenSigInvalidValue" SG_ 406 FC_TLA7_direction "15";
BA_ "GenSigCycleTime" SG_ 406 FC_TLA7_Color 60;
BA_ "GenSigInvalidValue" SG_ 406 FC_TLA7_Color "7";
BA_ "GenSigCycleTime" SG_ 406 FC_TLA7_ClassificationType 60;
BA_ "GenSigInvalidValue" SG_ 406 FC_TLA7_ClassificationType "7";
BA_ "GenSigCycleTime" SG_ 406 FC_TLA6_ShapeType 60;
BA_ "GenSigInvalidValue" SG_ 406 FC_TLA6_ShapeType "3";
BA_ "GenSigCycleTime" SG_ 406 FC_TLA6_BlindingStatus 60;
BA_ "GenSigCycleTime" SG_ 406 FC_TLA6_Confidence 60;
BA_ "GenSigCycleTime" SG_ 406 FC_TLA6_PosZ 60;
BA_ "GenSigCycleTime" SG_ 406 FC_TLA6_PosY 60;
BA_ "GenSigCycleTime" SG_ 406 FC_TLA6_PosX 60;
BA_ "GenSigCycleTime" SG_ 406 FC_TLA6_direction 60;
BA_ "GenSigInvalidValue" SG_ 406 FC_TLA6_direction "15";
BA_ "GenSigCycleTime" SG_ 406 FC_TLA6_Color 60;
BA_ "GenSigInvalidValue" SG_ 406 FC_TLA6_Color "7";
BA_ "GenSigCycleTime" SG_ 406 FC_TLA6_ClassificationType 60;
BA_ "GenSigInvalidValue" SG_ 406 FC_TLA6_ClassificationType "7";
BA_ "GenSigCycleTime" SG_ 406 FC_TLA5_ShapeType 60;
BA_ "GenSigInvalidValue" SG_ 406 FC_TLA5_ShapeType "3";
BA_ "GenSigCycleTime" SG_ 406 FC_TLA5_BlindingStatus 60;
BA_ "GenSigCycleTime" SG_ 406 FC_TLA5_Confidence 60;
BA_ "GenSigCycleTime" SG_ 406 FC_TLA5_PosZ 60;
BA_ "GenSigCycleTime" SG_ 406 FC_TLA5_PosY 60;
BA_ "GenSigCycleTime" SG_ 406 FC_TLA5_PosX 60;
BA_ "GenSigCycleTime" SG_ 406 FC_TLA5_direction 60;
BA_ "GenSigInvalidValue" SG_ 406 FC_TLA5_direction "15";
BA_ "GenSigCycleTime" SG_ 406 FC_TLA5_Color 60;
BA_ "GenSigInvalidValue" SG_ 406 FC_TLA5_Color "7";
BA_ "GenSigCycleTime" SG_ 406 FC_TLA5_ClassificationType 60;
BA_ "GenSigInvalidValue" SG_ 406 FC_TLA5_ClassificationType "7";

BA_ "GenSigCycleTime" SG_ 407 FC_Pole2_LiftAng 100;
BA_ "GenSigCycleTime" SG_ 407 FC_Pole2_Dy 100;
BA_ "GenSigStartValue" SG_ 407 FC_Pole2_Dy 2000.000000;
BA_ "GenSigCycleTime" SG_ 407 FC_Pole2_Dx 100;
BA_ "GenSigCycleTime" SG_ 407 FC_Pole2_Type 100;
BA_ "GenSigCycleTime" SG_ 407 FC_Pole2_Detected 100;
BA_ "GenSigCycleTime" SG_ 407 FC_Pole1_LiftAng 100;
BA_ "GenSigCycleTime" SG_ 407 FC_Pole1_Dy 100;
BA_ "GenSigStartValue" SG_ 407 FC_Pole1_Dy 2000.000000;
BA_ "GenSigCycleTime" SG_ 407 FC_Pole1_Dx 100;
BA_ "GenSigCycleTime" SG_ 407 FC_Pole1_Type 100;
BA_ "GenSigCycleTime" SG_ 407 FC_Pole1_Detected 100;
BA_ "GenSigCycleTime" SG_ 407 FC_CRCCheck_197 100;
BA_ "GenSigCycleTime" SG_ 407 FC_RollingCounter_197 100;
BA_ "GenSigCycleTime" SG_ 407 FC_SpeedBump_Dist 100;
BA_ "GenSigCycleTime" SG_ 407 FC_SpeedBump_Detect 100;
BA_ "GenSigCycleTime" SG_ 407 FC_Crosswalk_Dist 100;
BA_ "GenSigCycleTime" SG_ 407 FC_Crosswalk_Detect 100;
BA_ "GenSigCycleTime" SG_ 407 FC_StopLine_Dist 100;
BA_ "GenSigCycleTime" SG_ 407 FC_StopLine_Detected 100;
BA_ "GenSigCycleTime" SG_ 407 FC_TSRWarningSign 100;
BA_ "GenSigCycleTime" SG_ 407 FC_TSRProhibitionSign 100;
BA_ "GenSigCycleTime" SG_ 407 FC_TSRMandatorySign 100;
BA_ "GenSigCycleTime" SG_ 407 FC_speedLimitSign_Dy 100;
BA_ "GenSigStartValue" SG_ 407 FC_speedLimitSign_Dy 500.000000;
BA_ "GenSigCycleTime" SG_ 407 FC_speedLimitSign_Dx 100;
BA_ "GenSigCycleTime" SG_ 407 FC_TSRHostSpdLimitUnits 100;
BA_ "GenSigInvalidValue" SG_ 407 FC_TSRHostSpdLimitUnits "0";
BA_ "GenSigCycleTime" SG_ 407 FC_SpeedLimitType_1 100;
BA_ "GenSigCycleTime" SG_ 407 FC_SpeedLimit_1 100;

BA_ "GenSigCycleTime" SG_ 408 FC_CRCCheck_198 100;
BA_ "GenSigCycleTime" SG_ 408 FC_RollingCounter_198 100;
BA_ "GenSigCycleTime" SG_ 408 FC_RoadSignConfidence_3 100;
BA_ "GenSigCycleTime" SG_ 408 FC_RoadSignCenterLatRange_3 100;
BA_ "GenSigCycleTime" SG_ 408 FC_RoadSignCenterLngRange_3 100;
BA_ "GenSigCycleTime" SG_ 408 FC_RoadSignType_3 100;
BA_ "GenSigCycleTime" SG_ 408 FC_RoadSignConfidence_2 100;
BA_ "GenSigCycleTime" SG_ 408 FC_RoadSignCenterLatRange_2 100;
BA_ "GenSigCycleTime" SG_ 408 FC_RoadSignCenterLngRange_2 100;
BA_ "GenSigCycleTime" SG_ 408 FC_RoadSignType_2 100;
BA_ "GenSigCycleTime" SG_ 408 FC_RoadSignConfidence_1 100;
BA_ "GenSigCycleTime" SG_ 408 FC_RoadSignCenterLatRange_1 100;
BA_ "GenSigCycleTime" SG_ 408 FC_RoadSignCenterLngRange_1 100;
BA_ "GenSigCycleTime" SG_ 408 FC_RoadSignType_1 100;

BA_ "GenSigCycleTime" SG_ 516 FC_Inner_Parameter_Center_V 500;
BA_ "GenSigCycleTime" SG_ 516 FC_Inner_Parameter_Center_U 500;
BA_ "GenSigCycleTime" SG_ 516 FC_Inner_Parameter_Focal_V 500;
BA_ "GenSigCycleTime" SG_ 516 FC_Inner_Parameter_Focal_U 500;
BA_ "GenSigCycleTime" SG_ 516 FC_Exter_Parameter_Dz 500;
BA_ "GenSigCycleTime" SG_ 516 FC_Exter_Parameter_Dy 500;
BA_ "GenSigCycleTime" SG_ 516 FC_Exter_Parameter_Dx 500;
BA_ "GenSigCycleTime" SG_ 516 FC_DTC2_Status 500;
BA_ "GenSigCycleTime" SG_ 516 FC_DTC2_LowByte 500;
BA_ "GenSigCycleTime" SG_ 516 FC_DTC2_MiddByte 500;
BA_ "GenSigCycleTime" SG_ 516 FC_DTC2_HighByte 500;
BA_ "GenSigCycleTime" SG_ 516 FC_DTC1_Status 500;
BA_ "GenSigCycleTime" SG_ 516 FC_DTC1_LowByte 500;
BA_ "GenSigCycleTime" SG_ 516 FC_DTC1_MiddByte 500;
BA_ "GenSigCycleTime" SG_ 516 FC_DTC1_HighByte 500;
BA_ "GenSigCycleTime" SG_ 516 FC_Exter_Parameter_Roll 500;
BA_ "GenSigCycleTime" SG_ 516 FC_Exter_Parameter_Yaw 500;
BA_ "GenSigCycleTime" SG_ 516 FC_Exter_Parameter_Pitch 500;

BA_ "GenSigCycleTime" SG_ 264 FC_CRCCheck_108 20;
BA_ "GenSigCycleTime" SG_ 264 FC_RollingCounter_108 20;
BA_ "GenSigCycleTime" SG_ 264 FC_AEBTargetProb 20;
BA_ "GenSigCycleTime" SG_ 264 FC_AEBTargetAy 20;
BA_ "GenSigCycleTime" SG_ 264 FC_AEBTargetAx 20;
BA_ "GenSigCycleTime" SG_ 264 FC_AEBTargetStatus 20;
BA_ "GenSigCycleTime" SG_ 264 FC_AEBTargetLatRelSpeed 20;
BA_ "GenSigCycleTime" SG_ 264 FC_RLaneMarkerType 20;
BA_ "GenSigStartValue" SG_ 264 FC_RLaneMarkerType 7.000000;
BA_ "GenSigCycleTime" SG_ 264 FC_HostLaneRightStatus 20;
BA_ "GenSigCycleTime" SG_ 264 FC_RLaneDistanceFus 20;
BA_ "GenSigStartValue" SG_ 264 FC_RLaneDistanceFus 100.000000;
BA_ "GenSigCycleTime" SG_ 264 FC_LLaneMarkerType 20;
BA_ "GenSigStartValue" SG_ 264 FC_LLaneMarkerType 7.000000;
BA_ "GenSigCycleTime" SG_ 264 FC_HostLaneLeftStatus 20;
BA_ "GenSigCycleTime" SG_ 264 FC_LLaneDistanceFus 20;
BA_ "GenSigStartValue" SG_ 264 FC_LLaneDistanceFus 20.000000;
BA_ "GenSigCycleTime" SG_ 264 FC_HMAEnableStatus 20;
BA_ "GenSigCycleTime" SG_ 264 FC_HMALightDistribution 20;
BA_ "GenSigCycleTime" SG_ 264 FC_HMAStatus 20;
BA_ "GenSigInvalidValue" SG_ 264 FC_HMAStatus "3";
BA_ "GenSigCycleTime" SG_ 264 FC_LaneCurvature_0m 20;
BA_ "GenSigStartValue" SG_ 264 FC_LaneCurvature_0m 60.000000;
BA_ "GenSigCycleTime" SG_ 264 FC_Voiceinfo 20;
BA_ "GenSigCycleTime" SG_ 264 FC_AEBEnable 20;
BA_ "GenSigStartValue" SG_ 264 FC_AEBEnable 1.000000;
BA_ "GenSigCycleTime" SG_ 264 FC_FCWSettingStatus 20;
BA_ "GenSigStartValue" SG_ 264 FC_FCWSettingStatus 1.000000;
BA_ "GenSigCycleTime" SG_ 264 FC_FCWPreWarning 20;
BA_ "GenSigCycleTime" SG_ 264 FC_FCWLatentWarning 20;
BA_ "GenSigCycleTime" SG_ 264 FC_FCWActive 20;
BA_ "GenSigCycleTime" SG_ 264 FC_FCWStatus 20;
BA_ "GenSigInvalidValue" SG_ 264 FC_FCWStatus "3";
BA_ "GenSigCycleTime" SG_ 264 FC_AEBTargetLatRange 20;
BA_ "GenSigStartValue" SG_ 264 FC_AEBTargetLatRange 500.000000;
BA_ "GenSigCycleTime" SG_ 264 FC_AEBTargetLngRange 20;
BA_ "GenSigStartValue" SG_ 264 FC_AEBTargetLngRange 500.000000;
BA_ "GenSigCycleTime" SG_ 264 FC_AEBTargetDetection 20;
BA_ "GenSigCycleTime" SG_ 264 FC_AEBTargetType 20;
BA_ "GenSigStartValue" SG_ 264 FC_AEBTargetType 15.000000;
BA_ "GenSigCycleTime" SG_ 264 FC_AEBTargetRelSpeed 20;
BA_ "GenSigStartValue" SG_ 264 FC_AEBTargetRelSpeed 250.000000;
BA_ "GenSigCycleTime" SG_ 264 FC_AEBTextInfo 20;
BA_ "GenSigCycleTime" SG_ 264 FC_AEBStatus 20;
BA_ "GenSigInvalidValue" SG_ 264 FC_AEBStatus "3";
BA_ "GenSigCycleTime" SG_ 264 FC_ABAActive 20;
BA_ "GenSigInvalidValue" SG_ 264 FC_ABAActive "0";
BA_ "GenSigCycleTime" SG_ 264 FC_ABAlevel 20;
BA_ "GenSigStartValue" SG_ 264 FC_ABAlevel 3.000000;
BA_ "GenSigInvalidValue" SG_ 264 FC_ABAlevel "3";
BA_ "GenSigCycleTime" SG_ 264 FC_AWBActive 20;
BA_ "GenSigInvalidValue" SG_ 264 FC_AWBActive "0";
BA_ "GenSigCycleTime" SG_ 264 FC_AWBlevel 20;
BA_ "GenSigInvalidValue" SG_ 264 FC_AWBlevel "0";
BA_ "GenSigCycleTime" SG_ 264 FC_PrefillActive 20;
BA_ "GenSigInvalidValue" SG_ 264 FC_PrefillActive "0";
BA_ "GenSigCycleTime" SG_ 264 FC_AEBVehilceHoldReq 20;
BA_ "GenSigInvalidValue" SG_ 264 FC_AEBVehilceHoldReq "0";
BA_ "GenSigCycleTime" SG_ 264 FC_AEBCtrlType 20;
BA_ "GenSigCycleTime" SG_ 264 FC_AEBTargetDeceleration 20;
BA_ "GenSigCycleTime" SG_ 264 FC_AEBActive 20;
BA_ "GenSigCycleTime" SG_ 264 FC_AEBTargetmode 20;
BA_ "GenSigCycleTime" SG_ 264 FC_OBJ_AEB_ID 20;
BA_ "GenSigCycleTime" SG_ 264 FC_ELKEnableStatus 20;
BA_ "GenSigCycleTime" SG_ 264 FC_ELKInterventionMode 20;
BA_ "GenSigCycleTime" SG_ 264 FC_ELKMode 20;
BA_ "GenSigInvalidValue" SG_ 264 FC_ELKMode "3";
BA_ "GenSigCycleTime" SG_ 264 FC_LDWShakeLevStatus 20;
BA_ "GenSigStartValue" SG_ 264 FC_LDWShakeLevStatus 2.000000;
BA_ "GenSigCycleTime" SG_ 264 FC_LASWarningModeSelectionSts 20;
BA_ "GenSigStartValue" SG_ 264 FC_LASWarningModeSelectionSts 2.000000;
BA_ "GenSigCycleTime" SG_ 264 FC_LASModeSelectionStatus 20;
BA_ "GenSigStartValue" SG_ 264 FC_LASModeSelectionStatus 1.000000;
BA_ "GenSigCycleTime" SG_ 264 FC_LKATakeoverReq 20;
BA_ "GenSigCycleTime" SG_ 264 FC_LKAStatus 20;
BA_ "GenSigInvalidValue" SG_ 264 FC_LKAStatus "3";
BA_ "GenSigCycleTime" SG_ 264 FC_LDWVibrationWarningReq 20;
BA_ "GenSigCycleTime" SG_ 264 FC_LDWStatus 20;
BA_ "GenSigInvalidValue" SG_ 264 FC_LDWStatus "3";

BA_ "GenSigCycleTime" SG_ 263 FC_CRCCheck_107 10;
BA_ "GenSigCycleTime" SG_ 263 FC_RollingCounter_107 10;
BA_ "GenSigCycleTime" SG_ 263 FC_LatAngReqActive 10;
BA_ "GenSigCycleTime" SG_ 263 FC_LatAngReq 10;
BA_ "GenSigCycleTime" SG_ 263 FC_MotorTorqueMinLimitRequest 10;
BA_ "GenSigCycleTime" SG_ 263 FC_MotorTorqueMaxLimitRequest 10;

BA_ "GenSigCycleTime" SG_ 261 ESP_IMUCalibrated 10;
BA_ "GenSigCycleTime" SG_ 261 ESP_YawRateValid 10;
BA_ "GenSigCycleTime" SG_ 261 ESP_YawRate 10;
BA_ "GenSigInvalidValue" SG_ 261 ESP_YawRate "16383";
BA_ "GenSigCycleTime" SG_ 261 ESP_LongAccelValid 10;
BA_ "GenSigCycleTime" SG_ 261 ESP_LongAccel 10;
BA_ "GenSigStartValue" SG_ 261 ESP_LongAccel 3200.000000;
BA_ "GenSigInvalidValue" SG_ 261 ESP_LongAccel "8191";
BA_ "GenSigCycleTime" SG_ 261 ESP_LatAccelValid 10;
BA_ "GenSigCycleTime" SG_ 261 ESP_LatAccel 10;
BA_ "GenSigStartValue" SG_ 261 ESP_LatAccel 3200.000000;
BA_ "GenSigInvalidValue" SG_ 261 ESP_LatAccel "8191";
BA_ "GenSigCycleTime" SG_ 261 ADC_CRCCheck_105 10;
BA_ "GenSigCycleTime" SG_ 261 ADC_RollingCounter_105 10;
BA_ "GenSigCycleTime" SG_ 261 EpsSteerAgSensFilr 10;
BA_ "GenSigInvalidValue" SG_ 261 EpsSteerAgSensFilr "1";
BA_ "GenSigCycleTime" SG_ 261 EpsSteerAgRate 10;
BA_ "GenSigInvalidValue" SG_ 261 EpsSteerAgRate "255";
BA_ "GenSigCycleTime" SG_ 261 EpsSasSteerAgVld 10;
BA_ "GenSigInvalidValue" SG_ 261 EpsSasSteerAgVld "1";
BA_ "GenSigCycleTime" SG_ 261 EpsSasSteerAg 10;
BA_ "GenSigInvalidValue" SG_ 261 EpsSasSteerAg "32767";
BA_ "GenSigCycleTime" SG_ 261 EpsSasCalSts 10;
BA_ "GenSigCycleTime" SG_ 261 VcuRdySts 10;
BA_ "GenSigInvalidValue" SG_ 261 VcuRdySts "NA";
BA_ "GenSigCycleTime" SG_ 261 VcuVehGearPosnVld 10;
BA_ "GenSigInvalidValue" SG_ 261 VcuVehGearPosnVld "1";
BA_ "GenSigCycleTime" SG_ 261 VcuGearPosn 10;
BA_ "GenSigInvalidValue" SG_ 261 VcuGearPosn "NA";
BA_ "GenSigCycleTime" SG_ 261 WhlSpdReRiPls 10;
BA_ "GenSigInvalidValue" SG_ 261 WhlSpdReRiPls "255";
BA_ "GenSigCycleTime" SG_ 261 WhlSpdRiReDir 10;
BA_ "GenSigInvalidValue" SG_ 261 WhlSpdRiReDir "3";
BA_ "GenSigCycleTime" SG_ 261 WhlSpdRiReDataVld 10;
BA_ "GenSigInvalidValue" SG_ 261 WhlSpdRiReDataVld "1";
BA_ "GenSigCycleTime" SG_ 261 WhlSpdRiReData 10;
BA_ "GenSigInvalidValue" SG_ 261 WhlSpdRiReData "8191";
BA_ "GenSigCycleTime" SG_ 261 WhlSpdFrntRiPls 10;
BA_ "GenSigInvalidValue" SG_ 261 WhlSpdFrntRiPls "255";
BA_ "GenSigCycleTime" SG_ 261 WhlSpdRiFrntDir 10;
BA_ "GenSigInvalidValue" SG_ 261 WhlSpdRiFrntDir "3";
BA_ "GenSigCycleTime" SG_ 261 WhlSpdRiFrntDataVld 10;
BA_ "GenSigInvalidValue" SG_ 261 WhlSpdRiFrntDataVld "1";
BA_ "GenSigCycleTime" SG_ 261 WhlSpdRiFrntData 10;
BA_ "GenSigInvalidValue" SG_ 261 WhlSpdRiFrntData "8191";
BA_ "GenSigCycleTime" SG_ 261 WhlSpdReLePls 10;
BA_ "GenSigInvalidValue" SG_ 261 WhlSpdReLePls "255";
BA_ "GenSigCycleTime" SG_ 261 WhlSpdLeReDir 10;
BA_ "GenSigInvalidValue" SG_ 261 WhlSpdLeReDir "3";
BA_ "GenSigCycleTime" SG_ 261 WhlSpdLeReDataVld 10;
BA_ "GenSigInvalidValue" SG_ 261 WhlSpdLeReDataVld "1";
BA_ "GenSigCycleTime" SG_ 261 WhlSpdLeReData 10;
BA_ "GenSigInvalidValue" SG_ 261 WhlSpdLeReData "8191";
BA_ "GenSigCycleTime" SG_ 261 WhlSpdFrntLePls 10;
BA_ "GenSigInvalidValue" SG_ 261 WhlSpdFrntLePls "255";
BA_ "GenSigCycleTime" SG_ 261 WhlSpdLeFrntDir 10;
BA_ "GenSigInvalidValue" SG_ 261 WhlSpdLeFrntDir "3";
BA_ "GenSigCycleTime" SG_ 261 WhlSpdLeFrntDataVld 10;
BA_ "GenSigInvalidValue" SG_ 261 WhlSpdLeFrntDataVld "1";
BA_ "GenSigCycleTime" SG_ 261 WhlSpdLeFrntData 10;
BA_ "GenSigInvalidValue" SG_ 261 WhlSpdLeFrntData "8191";
BA_ "GenSigCycleTime" SG_ 261 EspVehSpdVld 10;
BA_ "GenSigInvalidValue" SG_ 261 EspVehSpdVld "1";
BA_ "GenSigCycleTime" SG_ 261 EspVehSpd 10;
BA_ "GenSigInvalidValue" SG_ 261 EspVehSpd "8191";

BA_ "GenSigCycleTime" SG_ 512 ADC_SYNC_Sync_Time 500;
BA_ "GenSigCycleTime" SG_ 512 ADC_SYNC_UserByte_OVS_SGW 500;
BA_ "GenSigCycleTime" SG_ 512 ADC_SYNC_TimeDomain 500;
BA_ "GenSigCycleTime" SG_ 512 ADC_SYNC_Sequence 500;
BA_ "GenSigCycleTime" SG_ 512 ADC_SYNC_CRC 500;
BA_ "GenSigCycleTime" SG_ 512 ADC_SYNC_Type 500;

BA_ "GenSigCycleTime" SG_ 411 ACC_ACCMode 100;
BA_ "GenSigInvalidValue" SG_ 411 ACC_ACCMode "7";
BA_ "GenSigCycleTime" SG_ 411 ADC_SenceMode 100;
BA_ "GenSigInvalidValue" SG_ 411 ADC_SenceMode "2";
BA_ "GenSigCycleTime" SG_ 411 ADC_CRCCheck_19B 100;
BA_ "GenSigCycleTime" SG_ 411 ADC_RollingCounter_19B 100;
BA_ "GenSigCycleTime" SG_ 411 BcmPwrStsFb 100;
BA_ "GenSigCycleTime" SG_ 411 TboxLocalTiYear 100;
BA_ "GenSigCycleTime" SG_ 411 TboxLocalTiVld 100;
BA_ "GenSigCycleTime" SG_ 411 TboxLocalTiSec 100;
BA_ "GenSigCycleTime" SG_ 411 TboxLocalTiMth 100;
BA_ "GenSigCycleTime" SG_ 411 TboxLocalTiMins 100;
BA_ "GenSigCycleTime" SG_ 411 TboxLocalTiHr 100;
BA_ "GenSigCycleTime" SG_ 411 TboxLocalTiDate 100;
BA_ "GenSigCycleTime" SG_ 411 CdcTotMilg 100;
BA_ "GenSigInvalidValue" SG_ 411 CdcTotMilg "16777215";
BA_ "GenSigCycleTime" SG_ 411 ADC_WorkMode 100;
BA_ "GenSigCycleTime" SG_ 411 ACC_IACCHWAMode 100;
BA_ "GenSigInvalidValue" SG_ 411 ACC_IACCHWAMode "7";
BA_ "GenSigCycleTime" SG_ 411 ADS_UDLCStatus 100;
BA_ "GenSigInvalidValue" SG_ 411 ADS_UDLCStatus "6";
BA_ "GenSigCycleTime" SG_ 411 ADS_Fail 100;

BA_ "GenSigCycleTime" SG_ 518 FR_SwVers6 1000;
BA_ "GenSigInvalidValue" SG_ 518 FR_SwVers6 "NA";
BA_ "GenSigCycleTime" SG_ 518 FR_SwVers5 1000;
BA_ "GenSigInvalidValue" SG_ 518 FR_SwVers5 "NA";
BA_ "GenSigCycleTime" SG_ 518 FR_SwVers4 1000;
BA_ "GenSigInvalidValue" SG_ 518 FR_SwVers4 "NA";
BA_ "GenSigCycleTime" SG_ 518 FR_SwVers3 1000;
BA_ "GenSigInvalidValue" SG_ 518 FR_SwVers3 "NA";
BA_ "GenSigCycleTime" SG_ 518 FR_SwVers2 1000;
BA_ "GenSigInvalidValue" SG_ 518 FR_SwVers2 "NA";
BA_ "GenSigCycleTime" SG_ 518 FR_SwVers1 1000;
BA_ "GenSigInvalidValue" SG_ 518 FR_SwVers1 "NA";
BA_ "GenSigCycleTime" SG_ 518 FR_SwVers0 1000;
BA_ "GenSigInvalidValue" SG_ 518 FR_SwVers0 "NA";
BA_ "GenSigCycleTime" SG_ 518 FR_HwVers6 1000;
BA_ "GenSigInvalidValue" SG_ 518 FR_HwVers6 "NA";
BA_ "GenSigCycleTime" SG_ 518 FR_HwVers5 1000;
BA_ "GenSigInvalidValue" SG_ 518 FR_HwVers5 "NA";
BA_ "GenSigCycleTime" SG_ 518 FR_HwVers4 1000;
BA_ "GenSigInvalidValue" SG_ 518 FR_HwVers4 "NA";
BA_ "GenSigCycleTime" SG_ 518 FR_HwVers3 1000;
BA_ "GenSigInvalidValue" SG_ 518 FR_HwVers3 "NA";
BA_ "GenSigCycleTime" SG_ 518 FR_HwVers2 1000;
BA_ "GenSigInvalidValue" SG_ 518 FR_HwVers2 "NA";
BA_ "GenSigCycleTime" SG_ 518 FR_HwVers1 1000;
BA_ "GenSigInvalidValue" SG_ 518 FR_HwVers1 "NA";
BA_ "GenSigCycleTime" SG_ 518 FR_HwVers0 1000;
BA_ "GenSigInvalidValue" SG_ 518 FR_HwVers0 "NA";

BA_ "GenSigCycleTime" SG_ 519 FC_SwVers6 1000;
BA_ "GenSigInvalidValue" SG_ 519 FC_SwVers6 "NA";
BA_ "GenSigCycleTime" SG_ 519 FC_SwVers5 1000;
BA_ "GenSigInvalidValue" SG_ 519 FC_SwVers5 "NA";
BA_ "GenSigCycleTime" SG_ 519 FC_SwVers4 1000;
BA_ "GenSigInvalidValue" SG_ 519 FC_SwVers4 "NA";
BA_ "GenSigCycleTime" SG_ 519 FC_SwVers3 1000;
BA_ "GenSigInvalidValue" SG_ 519 FC_SwVers3 "NA";
BA_ "GenSigCycleTime" SG_ 519 FC_SwVers2 1000;
BA_ "GenSigInvalidValue" SG_ 519 FC_SwVers2 "NA";
BA_ "GenSigCycleTime" SG_ 519 FC_SwVers1 1000;
BA_ "GenSigInvalidValue" SG_ 519 FC_SwVers1 "NA";
BA_ "GenSigCycleTime" SG_ 519 FC_SwVers0 1000;
BA_ "GenSigInvalidValue" SG_ 519 FC_SwVers0 "NA";
BA_ "GenSigCycleTime" SG_ 519 FC_HwVers6 1000;
BA_ "GenSigInvalidValue" SG_ 519 FC_HwVers6 "NA";
BA_ "GenSigCycleTime" SG_ 519 FC_HwVers5 1000;
BA_ "GenSigInvalidValue" SG_ 519 FC_HwVers5 "NA";
BA_ "GenSigCycleTime" SG_ 519 FC_HwVers4 1000;
BA_ "GenSigInvalidValue" SG_ 519 FC_HwVers4 "NA";
BA_ "GenSigCycleTime" SG_ 519 FC_HwVers3 1000;
BA_ "GenSigInvalidValue" SG_ 519 FC_HwVers3 "NA";
BA_ "GenSigCycleTime" SG_ 519 FC_HwVers2 1000;
BA_ "GenSigInvalidValue" SG_ 519 FC_HwVers2 "NA";
BA_ "GenSigCycleTime" SG_ 519 FC_HwVers1 1000;
BA_ "GenSigInvalidValue" SG_ 519 FC_HwVers1 "NA";
BA_ "GenSigCycleTime" SG_ 519 FC_HwVers0 1000;
BA_ "GenSigInvalidValue" SG_ 519 FC_HwVers0 "NA";

BA_ "GenSigCycleTime" SG_ 837 RLR_CRCCheck_345 50;
BA_ "GenSigCycleTime" SG_ 837 RLR_RollingCounter_345 50;
BA_ "GenSigCycleTime" SG_ 837 RLR_ElkOBJ2_RefPointLoc 50;
BA_ "GenSigCycleTime" SG_ 837 RLR_ElkOBJ2_RefPointDx 50;
BA_ "GenSigCycleTime" SG_ 837 RLR_ElkOBJ2_RefPointDy 50;
BA_ "GenSigCycleTime" SG_ 837 RLR_ElkOBJ2_ObstacleProb 50;
BA_ "GenSigCycleTime" SG_ 837 RLR_ElkOBJ2_Measured 50;
BA_ "GenSigInvalidValue" SG_ 837 RLR_ElkOBJ2_Measured "0";
BA_ "GenSigCycleTime" SG_ 837 RLR_ElkOBJ2_ExistProb 50;
BA_ "GenSigInvalidValue" SG_ 837 RLR_ElkOBJ2_ExistProb "0";
BA_ "GenSigCycleTime" SG_ 837 RLR_ElkOBJ2_Location 50;
BA_ "GenSigInvalidValue" SG_ 837 RLR_ElkOBJ2_Location "0";
BA_ "GenSigCycleTime" SG_ 837 RLR_ElkOBJ2_RelAx 50;
BA_ "GenSigCycleTime" SG_ 837 RLR_ElkOBJ2_RelAy 50;
BA_ "GenSigCycleTime" SG_ 837 RLR_ElkOBJ2_RelVx 50;
BA_ "GenSigCycleTime" SG_ 837 RLR_ElkOBJ2_RelVy 50;
BA_ "GenSigCycleTime" SG_ 837 RLR_ElkOBJ2_Dx 50;
BA_ "GenSigCycleTime" SG_ 837 RLR_ElkOBJ2_Dy 50;
BA_ "GenSigCycleTime" SG_ 837 RLR_ElkOBJ2_HeadingAngle 50;
BA_ "GenSigCycleTime" SG_ 837 RLR_ElkOBJ2_Length 50;
BA_ "GenSigCycleTime" SG_ 837 RLR_ElkOBJ2_Height 50;
BA_ "GenSigCycleTime" SG_ 837 RLR_ElkOBJ2_Width 50;
BA_ "GenSigCycleTime" SG_ 837 RLR_ElkOBJ2_Type 50;
BA_ "GenSigInvalidValue" SG_ 837 RLR_ElkOBJ2_Type "0";
BA_ "GenSigCycleTime" SG_ 837 RLR_ElkOBJ2_Track_ID 50;
BA_ "GenSigCycleTime" SG_ 837 RLR_ElkOBJ1_RefPointLoc 50;
BA_ "GenSigCycleTime" SG_ 837 RLR_ElkOBJ1_RefPointDx 50;
BA_ "GenSigCycleTime" SG_ 837 RLR_ElkOBJ1_RefPointDy 50;
BA_ "GenSigCycleTime" SG_ 837 RLR_ElkOBJ1_ObstacleProb 50;
BA_ "GenSigCycleTime" SG_ 837 RLR_ElkOBJ1_Measured 50;
BA_ "GenSigInvalidValue" SG_ 837 RLR_ElkOBJ1_Measured "0";
BA_ "GenSigCycleTime" SG_ 837 RLR_ElkOBJ1_ExistProb 50;
BA_ "GenSigInvalidValue" SG_ 837 RLR_ElkOBJ1_ExistProb "0";
BA_ "GenSigCycleTime" SG_ 837 RLR_ElkOBJ1_Location 50;
BA_ "GenSigInvalidValue" SG_ 837 RLR_ElkOBJ1_Location "0";
BA_ "GenSigCycleTime" SG_ 837 RLR_ElkOBJ1_RelAx 50;
BA_ "GenSigCycleTime" SG_ 837 RLR_ElkOBJ1_RelAy 50;
BA_ "GenSigCycleTime" SG_ 837 RLR_ElkOBJ1_RelVx 50;
BA_ "GenSigCycleTime" SG_ 837 RLR_ElkOBJ1_RelVy 50;
BA_ "GenSigCycleTime" SG_ 837 RLR_ElkOBJ1_Dx 50;
BA_ "GenSigCycleTime" SG_ 837 RLR_ElkOBJ1_Dy 50;
BA_ "GenSigCycleTime" SG_ 837 RLR_ElkOBJ1_HeadingAngle 50;
BA_ "GenSigCycleTime" SG_ 837 RLR_ElkOBJ1_Length 50;
BA_ "GenSigCycleTime" SG_ 837 RLR_ElkOBJ1_Height 50;
BA_ "GenSigCycleTime" SG_ 837 RLR_ElkOBJ1_Width 50;
BA_ "GenSigCycleTime" SG_ 837 RLR_ElkOBJ1_Type 50;
BA_ "GenSigInvalidValue" SG_ 837 RLR_ElkOBJ1_Type "0";
BA_ "GenSigCycleTime" SG_ 837 RLR_ElkOBJ1_Track_ID 50;

BA_ "GenSigCycleTime" SG_ 838 RLR_CRCCheck_346 50;
BA_ "GenSigCycleTime" SG_ 838 RLR_RollingCounter_346 50;
BA_ "GenSigCycleTime" SG_ 838 RLR_ElkOBJ4_RefPointLoc 50;
BA_ "GenSigCycleTime" SG_ 838 RLR_ElkOBJ4_RefPointDx 50;
BA_ "GenSigCycleTime" SG_ 838 RLR_ElkOBJ4_RefPointDy 50;
BA_ "GenSigCycleTime" SG_ 838 RLR_ElkOBJ4_ObstacleProb 50;
BA_ "GenSigCycleTime" SG_ 838 RLR_ElkOBJ4_Measured 50;
BA_ "GenSigInvalidValue" SG_ 838 RLR_ElkOBJ4_Measured "0";
BA_ "GenSigCycleTime" SG_ 838 RLR_ElkOBJ4_ExistProb 50;
BA_ "GenSigInvalidValue" SG_ 838 RLR_ElkOBJ4_ExistProb "0";
BA_ "GenSigCycleTime" SG_ 838 RLR_ElkOBJ4_Location 50;
BA_ "GenSigInvalidValue" SG_ 838 RLR_ElkOBJ4_Location "0";
BA_ "GenSigCycleTime" SG_ 838 RLR_ElkOBJ4_RelAx 50;
BA_ "GenSigCycleTime" SG_ 838 RLR_ElkOBJ4_RelAy 50;
BA_ "GenSigCycleTime" SG_ 838 RLR_ElkOBJ4_RelVx 50;
BA_ "GenSigCycleTime" SG_ 838 RLR_ElkOBJ4_RelVy 50;
BA_ "GenSigCycleTime" SG_ 838 RLR_ElkOBJ4_Dx 50;
BA_ "GenSigCycleTime" SG_ 838 RLR_ElkOBJ4_Dy 50;
BA_ "GenSigCycleTime" SG_ 838 RLR_ElkOBJ4_HeadingAngle 50;
BA_ "GenSigCycleTime" SG_ 838 RLR_ElkOBJ4_Length 50;
BA_ "GenSigCycleTime" SG_ 838 RLR_ElkOBJ4_Height 50;
BA_ "GenSigCycleTime" SG_ 838 RLR_ElkOBJ4_Width 50;
BA_ "GenSigCycleTime" SG_ 838 RLR_ElkOBJ4_Type 50;
BA_ "GenSigInvalidValue" SG_ 838 RLR_ElkOBJ4_Type "0";
BA_ "GenSigCycleTime" SG_ 838 RLR_ElkOBJ4_Track_ID 50;
BA_ "GenSigCycleTime" SG_ 838 RLR_ElkOBJ3_RefPointLoc 50;
BA_ "GenSigCycleTime" SG_ 838 RLR_ElkOBJ3_RefPointDx 50;
BA_ "GenSigCycleTime" SG_ 838 RLR_ElkOBJ3_RefPointDy 50;
BA_ "GenSigCycleTime" SG_ 838 RLR_ElkOBJ3_ObstacleProb 50;
BA_ "GenSigCycleTime" SG_ 838 RLR_ElkOBJ3_Measured 50;
BA_ "GenSigInvalidValue" SG_ 838 RLR_ElkOBJ3_Measured "0";
BA_ "GenSigCycleTime" SG_ 838 RLR_ElkOBJ3_ExistProb 50;
BA_ "GenSigInvalidValue" SG_ 838 RLR_ElkOBJ3_ExistProb "0";
BA_ "GenSigCycleTime" SG_ 838 RLR_ElkOBJ3_Location 50;
BA_ "GenSigInvalidValue" SG_ 838 RLR_ElkOBJ3_Location "0";
BA_ "GenSigCycleTime" SG_ 838 RLR_ElkOBJ3_RelAx 50;
BA_ "GenSigCycleTime" SG_ 838 RLR_ElkOBJ3_RelAy 50;
BA_ "GenSigCycleTime" SG_ 838 RLR_ElkOBJ3_RelVx 50;
BA_ "GenSigCycleTime" SG_ 838 RLR_ElkOBJ3_RelVy 50;
BA_ "GenSigCycleTime" SG_ 838 RLR_ElkOBJ3_Dx 50;
BA_ "GenSigCycleTime" SG_ 838 RLR_ElkOBJ3_Dy 50;
BA_ "GenSigCycleTime" SG_ 838 RLR_ElkOBJ3_HeadingAngle 50;
BA_ "GenSigCycleTime" SG_ 838 RLR_ElkOBJ3_Length 50;
BA_ "GenSigCycleTime" SG_ 838 RLR_ElkOBJ3_Height 50;
BA_ "GenSigCycleTime" SG_ 838 RLR_ElkOBJ3_Width 50;
BA_ "GenSigCycleTime" SG_ 838 RLR_ElkOBJ3_Type 50;
BA_ "GenSigInvalidValue" SG_ 838 RLR_ElkOBJ3_Type "0";
BA_ "GenSigCycleTime" SG_ 838 RLR_ElkOBJ3_Track_ID 50;

BA_ "GenSigCycleTime" SG_ 836 RRR_WorkMode 50;
BA_ "GenSigCycleTime" SG_ 836 RLR_WorkMode 50;
BA_ "GenSigCycleTime" SG_ 836 RLR_Left_ELK_oAlert 50;
BA_ "GenSigCycleTime" SG_ 836 RLR_ELK_oStatus 50;
BA_ "GenSigInvalidValue" SG_ 836 RLR_ELK_oStatus "3";
BA_ "GenSigCycleTime" SG_ 836 RLR_ELK_oAlert 50;

BA_ "GenSigCycleTime" SG_ 1428 FR_NotSleep_BYTE7BIT1 1000;
BA_ "GenSigCycleTime" SG_ 1428 FR_NotSleep_BYTE7BIT0 1000;
BA_ "GenSigCycleTime" SG_ 1428 FR_WakeUp_BYTE4BIT1 1000;
BA_ "GenSigCycleTime" SG_ 1428 FR_WakeUp_BYTE4BIT0 1000;

BA_ "GenSigCycleTime" SG_ 384 FC_StaticObj10_LaneAssi 60;
BA_ "GenSigCycleTime" SG_ 384 FC_StaticObj9_LaneAssi 60;
BA_ "GenSigCycleTime" SG_ 384 FC_StaticObj8_LaneAssi 60;
BA_ "GenSigCycleTime" SG_ 384 FC_StaticObj7_LaneAssi 60;
BA_ "GenSigCycleTime" SG_ 384 FC_StaticObj6_LaneAssi 60;
BA_ "GenSigCycleTime" SG_ 384 FC_StaticObj5_LaneAssi 60;
BA_ "GenSigCycleTime" SG_ 384 FC_StaticObj4_LaneAssi 60;
BA_ "GenSigCycleTime" SG_ 384 FC_StaticObj3_LaneAssi 60;
BA_ "GenSigCycleTime" SG_ 384 FC_StaticObj2_LaneAssi 60;
BA_ "GenSigCycleTime" SG_ 384 FC_StaticObj1_LaneAssi 60;
BA_ "GenSigCycleTime" SG_ 384 FC_StaticObj10_Track_ID 60;
BA_ "GenSigCycleTime" SG_ 384 FC_StaticObj9_Track_ID 60;
BA_ "GenSigCycleTime" SG_ 384 FC_StaticObj8_Track_ID 60;
BA_ "GenSigCycleTime" SG_ 384 FC_StaticObj7_Track_ID 60;
BA_ "GenSigCycleTime" SG_ 384 FC_StaticObj6_Track_ID 60;
BA_ "GenSigCycleTime" SG_ 384 FC_StaticObj5_Track_ID 60;
BA_ "GenSigCycleTime" SG_ 384 FC_StaticObj4_Track_ID 60;
BA_ "GenSigCycleTime" SG_ 384 FC_StaticObj3_Track_ID 60;
BA_ "GenSigCycleTime" SG_ 384 FC_StaticObj2_Track_ID 60;
BA_ "GenSigCycleTime" SG_ 384 FC_StaticObj1_Track_ID 60;
BA_ "GenSigCycleTime" SG_ 384 FC_StaticObj10_Dy 60;
BA_ "GenSigCycleTime" SG_ 384 FC_StaticObj9_Dy 60;
BA_ "GenSigCycleTime" SG_ 384 FC_StaticObj8_Dy 60;
BA_ "GenSigCycleTime" SG_ 384 FC_StaticObj7_Dy 60;
BA_ "GenSigCycleTime" SG_ 384 FC_StaticObj6_Dy 60;
BA_ "GenSigCycleTime" SG_ 384 FC_StaticObj5_Dy 60;
BA_ "GenSigCycleTime" SG_ 384 FC_StaticObj4_Dy 60;
BA_ "GenSigCycleTime" SG_ 384 FC_StaticObj3_Dy 60;
BA_ "GenSigCycleTime" SG_ 384 FC_StaticObj2_Dy 60;
BA_ "GenSigCycleTime" SG_ 384 FC_StaticObj1_Dy 60;
BA_ "GenSigCycleTime" SG_ 384 FC_StaticObj10_Dx 60;
BA_ "GenSigCycleTime" SG_ 384 FC_StaticObj9_Dx 60;
BA_ "GenSigCycleTime" SG_ 384 FC_StaticObj8_Dx 60;
BA_ "GenSigCycleTime" SG_ 384 FC_StaticObj7_Dx 60;
BA_ "GenSigCycleTime" SG_ 384 FC_StaticObj6_Dx 60;
BA_ "GenSigCycleTime" SG_ 384 FC_StaticObj5_Dx 60;
BA_ "GenSigCycleTime" SG_ 384 FC_StaticObj4_Dx 60;
BA_ "GenSigCycleTime" SG_ 384 FC_StaticObj3_Dx 60;
BA_ "GenSigCycleTime" SG_ 384 FC_StaticObj2_Dx 60;
BA_ "GenSigCycleTime" SG_ 384 FC_StaticObj1_Dx 60;
BA_ "GenSigCycleTime" SG_ 384 FC_CRCCheck_180 60;
BA_ "GenSigCycleTime" SG_ 384 FC_RollingCounter_180 60;
BA_ "GenSigCycleTime" SG_ 384 FC_StaticObj10_Type 60;
BA_ "GenSigCycleTime" SG_ 384 FC_StaticObj9_Type 60;
BA_ "GenSigCycleTime" SG_ 384 FC_StaticObj8_Type 60;
BA_ "GenSigCycleTime" SG_ 384 FC_StaticObj7_Type 60;
BA_ "GenSigCycleTime" SG_ 384 FC_StaticObj6_Type 60;
BA_ "GenSigCycleTime" SG_ 384 FC_StaticObj5_Type 60;
BA_ "GenSigCycleTime" SG_ 384 FC_StaticObj4_Type 60;
BA_ "GenSigCycleTime" SG_ 384 FC_StaticObj3_Type 60;
BA_ "GenSigCycleTime" SG_ 384 FC_StaticObj2_Type 60;
BA_ "GenSigCycleTime" SG_ 384 FC_StaticObj1_Type 60;

BA_ "GenSigCycleTime" SG_ 497 ADC_UTCTiVld 100;
BA_ "GenSigStartValue" SG_ 497 ADC_UTCTiVld 1.000000;
BA_ "GenSigCycleTime" SG_ 497 ADC_UTCTiSec 100;
BA_ "GenSigCycleTime" SG_ 497 ADC_UTCTiMins 100;
BA_ "GenSigCycleTime" SG_ 497 ADC_UTCTiHr 100;
BA_ "GenSigCycleTime" SG_ 497 ADC_UTCTiDate 100;
BA_ "GenSigStartValue" SG_ 497 ADC_UTCTiDate 1.000000;
BA_ "GenSigCycleTime" SG_ 497 ADC_UTCTiMth 100;
BA_ "GenSigStartValue" SG_ 497 ADC_UTCTiMth 1.000000;
BA_ "GenSigCycleTime" SG_ 497 ADC_UTCTiYear 100;

BA_ "GenSigCycleTime" SG_ 498 FC_UTCTiVld 100;
BA_ "GenSigStartValue" SG_ 498 FC_UTCTiVld 1.000000;
BA_ "GenSigCycleTime" SG_ 498 FC_UTCTiSec 100;
BA_ "GenSigCycleTime" SG_ 498 FC_UTCTiMins 100;
BA_ "GenSigCycleTime" SG_ 498 FC_UTCTiHr 100;
BA_ "GenSigCycleTime" SG_ 498 FC_UTCTiDate 100;
BA_ "GenSigStartValue" SG_ 498 FC_UTCTiDate 1.000000;
BA_ "GenSigCycleTime" SG_ 498 FC_UTCTiMth 100;
BA_ "GenSigStartValue" SG_ 498 FC_UTCTiMth 1.000000;
BA_ "GenSigCycleTime" SG_ 498 FC_UTCTiYear 100;

BA_ "GenSigCycleTime" SG_ 385 FC_StaticObj20_LaneAssi 60;
BA_ "GenSigCycleTime" SG_ 385 FC_StaticObj19_LaneAssi 60;
BA_ "GenSigCycleTime" SG_ 385 FC_StaticObj18_LaneAssi 60;
BA_ "GenSigCycleTime" SG_ 385 FC_StaticObj17_LaneAssi 60;
BA_ "GenSigCycleTime" SG_ 385 FC_StaticObj16_LaneAssi 60;
BA_ "GenSigCycleTime" SG_ 385 FC_StaticObj15_LaneAssi 60;
BA_ "GenSigCycleTime" SG_ 385 FC_StaticObj14_LaneAssi 60;
BA_ "GenSigCycleTime" SG_ 385 FC_StaticObj13_LaneAssi 60;
BA_ "GenSigCycleTime" SG_ 385 FC_StaticObj12_LaneAssi 60;
BA_ "GenSigCycleTime" SG_ 385 FC_StaticObj11_LaneAssi 60;
BA_ "GenSigCycleTime" SG_ 385 FC_CRCCheck_181 60;
BA_ "GenSigCycleTime" SG_ 385 FC_RollingCounter_181 60;
BA_ "GenSigCycleTime" SG_ 385 FC_StaticObj20_Track_ID 60;
BA_ "GenSigCycleTime" SG_ 385 FC_StaticObj19_Track_ID 60;
BA_ "GenSigCycleTime" SG_ 385 FC_StaticObj18_Track_ID 60;
BA_ "GenSigCycleTime" SG_ 385 FC_StaticObj17_Track_ID 60;
BA_ "GenSigCycleTime" SG_ 385 FC_StaticObj16_Track_ID 60;
BA_ "GenSigCycleTime" SG_ 385 FC_StaticObj15_Track_ID 60;
BA_ "GenSigCycleTime" SG_ 385 FC_StaticObj14_Track_ID 60;
BA_ "GenSigCycleTime" SG_ 385 FC_StaticObj13_Track_ID 60;
BA_ "GenSigCycleTime" SG_ 385 FC_StaticObj12_Track_ID 60;
BA_ "GenSigCycleTime" SG_ 385 FC_StaticObj11_Track_ID 60;
BA_ "GenSigCycleTime" SG_ 385 FC_StaticObj20_Dy 60;
BA_ "GenSigCycleTime" SG_ 385 FC_StaticObj19_Dy 60;
BA_ "GenSigCycleTime" SG_ 385 FC_StaticObj18_Dy 60;
BA_ "GenSigCycleTime" SG_ 385 FC_StaticObj17_Dy 60;
BA_ "GenSigCycleTime" SG_ 385 FC_StaticObj16_Dy 60;
BA_ "GenSigCycleTime" SG_ 385 FC_StaticObj15_Dy 60;
BA_ "GenSigCycleTime" SG_ 385 FC_StaticObj14_Dy 60;
BA_ "GenSigCycleTime" SG_ 385 FC_StaticObj13_Dy 60;
BA_ "GenSigCycleTime" SG_ 385 FC_StaticObj12_Dy 60;
BA_ "GenSigCycleTime" SG_ 385 FC_StaticObj11_Dy 60;
BA_ "GenSigCycleTime" SG_ 385 FC_StaticObj20_Dx 60;
BA_ "GenSigCycleTime" SG_ 385 FC_StaticObj19_Dx 60;
BA_ "GenSigCycleTime" SG_ 385 FC_StaticObj18_Dx 60;
BA_ "GenSigCycleTime" SG_ 385 FC_StaticObj17_Dx 60;
BA_ "GenSigCycleTime" SG_ 385 FC_StaticObj16_Dx 60;
BA_ "GenSigCycleTime" SG_ 385 FC_StaticObj15_Dx 60;
BA_ "GenSigCycleTime" SG_ 385 FC_StaticObj14_Dx 60;
BA_ "GenSigCycleTime" SG_ 385 FC_StaticObj13_Dx 60;
BA_ "GenSigCycleTime" SG_ 385 FC_StaticObj12_Dx 60;
BA_ "GenSigCycleTime" SG_ 385 FC_StaticObj11_Dx 60;
BA_ "GenSigCycleTime" SG_ 385 FC_StaticObj20_Type 60;
BA_ "GenSigCycleTime" SG_ 385 FC_StaticObj19_Type 60;
BA_ "GenSigCycleTime" SG_ 385 FC_StaticObj18_Type 60;
BA_ "GenSigCycleTime" SG_ 385 FC_StaticObj17_Type 60;
BA_ "GenSigCycleTime" SG_ 385 FC_StaticObj16_Type 60;
BA_ "GenSigCycleTime" SG_ 385 FC_StaticObj15_Type 60;
BA_ "GenSigCycleTime" SG_ 385 FC_StaticObj14_Type 60;
BA_ "GenSigCycleTime" SG_ 385 FC_StaticObj13_Type 60;
BA_ "GenSigCycleTime" SG_ 385 FC_StaticObj12_Type 60;
BA_ "GenSigCycleTime" SG_ 385 FC_StaticObj11_Type 60;

VAL_ 373 FC_Obj16WSInfoPosType 0 "Unknown" 1 "RearLeft" 2 "RearCenter" 3 "RearRgiht" 4 "FrontLeft" 5 "FrontCenter" 6 "FrontRgiht" 7 "LeftCenter" 8 "RgihtCenter" 9 "Center" 10 "预留;";
VAL_ 373 FC_Obj16_TurnLight 0 "";
VAL_ 373 FC_Obj16_valid 0 "";
VAL_ 373 FC_Obj16_objCutInLane 0 "invalid" 1 "measured;
0x2=predicted;";
VAL_ 373 FC_Obj16_objCutInFlag 0 "invalid" 1 "cutin_hostLane" 2 "cutin_fov";
VAL_ 373 FC_Obj16_LaneAssignment 0 "UNKNOWN    
1=LEFT_LEFT    
2=LEFT    
3=HOST    
4=RIGHT     
5=RIGHT_RIGHT
0x6-0x7=Reserved";
VAL_ 373 FC_Obj16_MotionType 0 "Unknown" 1 "Moving" 2 "Stationary" 3 "Stopped" 4 "Moving Slowly";
VAL_ 373 FC_obj16_Brakelight_Info 0 "off" 1 "on ";
VAL_ 373 FC_Obj16_HeadOrientation 0 "Unknown" 1 "Head Front" 2 "Head Left Front" 3 "Head Left" 4 "Head Left Back" 5 "Head Back" 6 "Head Right Back" 7 "Head Right" 8 "Head right front" 9 "Reserved";
VAL_ 373 FC_Obj16_Type 0 "Not Detected;
0x1=car" 2 "truck" 3 "bicycle/motorbike" 4 "pedestrian" 5 "general" 6 "animal" 7 "uncertain" 8 " bus; 
 0x9~0xF = Reserved;";

VAL_ 374 FC_Obj17WSInfoPosType 0 "Unknown" 1 "RearLeft" 2 "RearCenter" 3 "RearRgiht" 4 "FrontLeft" 5 "FrontCenter" 6 "FrontRgiht" 7 "LeftCenter" 8 "RgihtCenter" 9 "Center" 10 "预留;";
VAL_ 374 FC_Obj17_TurnLight 0 "";
VAL_ 374 FC_Obj17_valid 0 "";
VAL_ 374 FC_Obj17_objCutInLane 0 "invalid" 1 "measured;
0x2=predicted;";
VAL_ 374 FC_Obj17_objCutInFlag 0 "invalid" 1 "cutin_hostLane" 2 "cutin_fov";
VAL_ 374 FC_Obj17_LaneAssignment 0 "UNKNOWN    
1=LEFT_LEFT    
2=LEFT    
3=HOST    
4=RIGHT     
5=RIGHT_RIGHT
0x6-0x7=Reserved";
VAL_ 374 FC_Obj17_MotionType 0 "Unknown" 1 "Moving" 2 "Stationary" 3 "Stopped" 4 "Moving Slowly";
VAL_ 374 FC_obj17_Brakelight_Info 0 "off" 1 "on ";
VAL_ 374 FC_Obj17_HeadOrientation 0 "Unknown" 1 "Head Front" 2 "Head Left Front" 3 "Head Left" 4 "Head Left Back" 5 "Head Back" 6 "Head Right Back" 7 "Head Right" 8 "Head right front" 9 "Reserved";
VAL_ 374 FC_Obj17_Type 0 "Not Detected;
0x1=car" 2 "truck" 3 "bicycle/motorbike" 4 "pedestrian" 5 "general" 6 "animal" 7 "uncertain" 8 " bus; 
 0x9~0xF = Reserved;";

VAL_ 375 FC_Obj18WSInfoPosType 0 "Unknown" 1 "RearLeft" 2 "RearCenter" 3 "RearRgiht" 4 "FrontLeft" 5 "FrontCenter" 6 "FrontRgiht" 7 "LeftCenter" 8 "RgihtCenter" 9 "Center" 10 "预留;";
VAL_ 375 FC_Obj18_TurnLight 0 "";
VAL_ 375 FC_Obj18_valid 0 "";
VAL_ 375 FC_Obj18_objCutInLane 0 "invalid" 1 "measured;
0x2=predicted;";
VAL_ 375 FC_Obj18_objCutInFlag 0 "invalid" 1 "cutin_hostLane" 2 "cutin_fov";
VAL_ 375 FC_Obj18_LaneAssignment 0 "UNKNOWN    
1=LEFT_LEFT    
2=LEFT    
3=HOST    
4=RIGHT     
5=RIGHT_RIGHT
0x6-0x7=Reserved";
VAL_ 375 FC_Obj18_MotionType 0 "Unknown" 1 "Moving" 2 "Stationary" 3 "Stopped" 4 "Moving Slowly";
VAL_ 375 FC_obj18_Brakelight_Info 0 "off" 1 "on ";
VAL_ 375 FC_Obj18_HeadOrientation 0 "Unknown" 1 "Head Front" 2 "Head Left Front" 3 "Head Left" 4 "Head Left Back" 5 "Head Back" 6 "Head Right Back" 7 "Head Right" 8 "Head right front" 9 "Reserved";
VAL_ 375 FC_Obj18_Type 0 "Not Detected;
0x1=car" 2 "truck" 3 "bicycle/motorbike" 4 "pedestrian" 5 "general" 6 "animal" 7 "uncertain" 8 " bus; 
 0x9~0xF = Reserved;";

VAL_ 376 FC_Obj19WSInfoPosType 0 "Unknown" 1 "RearLeft" 2 "RearCenter" 3 "RearRgiht" 4 "FrontLeft" 5 "FrontCenter" 6 "FrontRgiht" 7 "LeftCenter" 8 "RgihtCenter" 9 "Center" 10 "预留;";
VAL_ 376 FC_Obj19_TurnLight 0 "";
VAL_ 376 FC_Obj19_valid 0 "";
VAL_ 376 FC_Obj19_objCutInLane 0 "invalid" 1 "measured;
0x2=predicted;";
VAL_ 376 FC_Obj19_objCutInFlag 0 "invalid" 1 "cutin_hostLane" 2 "cutin_fov";
VAL_ 376 FC_Obj19_LaneAssignment 0 "UNKNOWN    
1=LEFT_LEFT    
2=LEFT    
3=HOST    
4=RIGHT     
5=RIGHT_RIGHT
0x6-0x7=Reserved";
VAL_ 376 FC_Obj19_MotionType 0 "Unknown" 1 "Moving" 2 "Stationary" 3 "Stopped" 4 "Moving Slowly";
VAL_ 376 FC_obj19_Brakelight_Info 0 "off" 1 "on ";
VAL_ 376 FC_Obj19_HeadOrientation 0 "Unknown" 1 "Head Front" 2 "Head Left Front" 3 "Head Left" 4 "Head Left Back" 5 "Head Back" 6 "Head Right Back" 7 "Head Right" 8 "Head right front" 9 "Reserved";
VAL_ 376 FC_Obj19_Type 0 "Not Detected;
0x1=car" 2 "truck" 3 "bicycle/motorbike" 4 "pedestrian" 5 "general" 6 "animal" 7 "uncertain" 8 " bus; 
 0x9~0xF = Reserved;";

VAL_ 377 FC_Obj20WSInfoPosType 0 "Unknown" 1 "RearLeft" 2 "RearCenter" 3 "RearRgiht" 4 "FrontLeft" 5 "FrontCenter" 6 "FrontRgiht" 7 "LeftCenter" 8 "RgihtCenter" 9 "Center" 10 "预留;";
VAL_ 377 FC_Obj20_TurnLight 0 "";
VAL_ 377 FC_Obj20_valid 0 "";
VAL_ 377 FC_Obj20_objCutInLane 0 "invalid" 1 "measured;
0x2=predicted;";
VAL_ 377 FC_Obj20_objCutInFlag 0 "invalid" 1 "cutin_hostLane" 2 "cutin_fov";
VAL_ 377 FC_Obj20_LaneAssignment 0 "UNKNOWN    
1=LEFT_LEFT    
2=LEFT    
3=HOST    
4=RIGHT     
5=RIGHT_RIGHT
0x6-0x7=Reserved";
VAL_ 377 FC_Obj20_MotionType 0 "Unknown" 1 "Moving" 2 "Stationary" 3 "Stopped" 4 "Moving Slowly";
VAL_ 377 FC_obj20_Brakelight_Info 0 "off" 1 "on ";
VAL_ 377 FC_Obj20_HeadOrientation 0 "Unknown" 1 "Head Front" 2 "Head Left Front" 3 "Head Left" 4 "Head Left Back" 5 "Head Back" 6 "Head Right Back" 7 "Head Right" 8 "Head right front" 9 "Reserved";
VAL_ 377 FC_Obj20_Type 0 "Not Detected;
0x1=car" 2 "truck" 3 "bicycle/motorbike" 4 "pedestrian" 5 "general" 6 "animal" 7 "uncertain" 8 " bus; 
 0x9~0xF = Reserved;";

VAL_ 400 FC_SenceMode 0 "";
VAL_ 400 FC_WorkMode 0 "";
VAL_ 400 FC_CameraFailureStatus 0 " no failure" 1 "Blind" 3 "reversible failure" 4 " irrversible failure" 5 "vehicle information failure
0x6-0x7=Reserevd";
VAL_ 400 FC_CameraCalibrationStatus 0 " Calibration is ok" 1 " Calibration In Process" 2 " Calibration never done" 3 "  Calibration Failed";
VAL_ 400 FC_CIPVFlag 0 "not CIPV    
0x1=CIPV";

VAL_ 403 FC_ObjTiOut 0 "no timeout" 1 "timeout";

VAL_ 405 FC_TLA4_ShapeType 0 "Unknown" 1 "Vertical -light
0x2=Horizontal -light
0x3=invalid";
VAL_ 405 FC_TLA4_BlindingStatus 0 "not detected" 1 "light;
0x2=flashing;
0x3=off";
VAL_ 405 FC_TLA4_direction 0 "";
VAL_ 405 FC_TLA4_Color 0 "No detected;
0x1=Red;
0x2=Green;
0x3=Yellow;
0x4=Off;
0x5=Other;
0x6=reserved;
0x7=invalid;";
VAL_ 405 FC_TLA4_ClassificationType 0 "no detected" 1 "Circle;
0x2=Arrow;
0x3=X_Type;
0x4=Turn Round;
0x5=Arrow+Turn Round;
0x6=Other;
0x7=Invalid;";
VAL_ 405 FC_TLA3_ShapeType 0 "Unknown" 1 "Vertical -light
0x2=Horizontal -light
0x3=invalid";
VAL_ 405 FC_TLA3_BlindingStatus 0 "not detected" 1 "light;
0x2=flashing;
0x3=off";
VAL_ 405 FC_TLA3_direction 0 "";
VAL_ 405 FC_TLA3_Color 0 "No detected;
0x1=Red;
0x2=Green;
0x3=Yellow;
0x4=Off;
0x5=Other;
0x6=reserved;
0x7=invalid;";
VAL_ 405 FC_TLA3_ClassificationType 0 "no detected" 1 "Circle;
0x2=Arrow;
0x3=X_Type;
0x4=Turn Round;
0x5=Arrow+Turn Round;
0x6=Other;
0x7=Invalid;";
VAL_ 405 FC_TLA2_ShapeType 0 "Unknown" 1 "Vertical -light
0x2=Horizontal -light
0x3=invalid";
VAL_ 405 FC_TLA2_BlindingStatus 0 "not detected" 1 "light;
0x2=flashing;
0x3=off";
VAL_ 405 FC_TLA2_direction 0 "";
VAL_ 405 FC_TLA2_Color 0 "No detected;
0x1=Red;
0x2=Green;
0x3=Yellow;
0x4=Off;
0x5=Other;
0x6=reserved;
0x7=invalid;";
VAL_ 405 FC_TLA2_ClassificationType 0 "no detected" 1 "Circle;
0x2=Arrow;
0x3=X_Type;
0x4=Turn Round;
0x5=Arrow+Turn Round;
0x6=Other;
0x7=Invalid;";
VAL_ 405 FC_TLA1_ShapeType 0 "Unknown" 1 "Vertical -light
0x2=Horizontal -light
0x3=invalid";
VAL_ 405 FC_TLA1_BlindingStatus 0 "not detected" 1 "light;
0x2=flashing;
0x3=off";
VAL_ 405 FC_TLA1_direction 0 "";
VAL_ 405 FC_TLA1_Color 0 "No detected;
0x1=Red;
0x2=Green;
0x3=Yellow;
0x4=Off;
0x5=Other;
0x6=reserved;
0x7=invalid;";
VAL_ 405 FC_TLA1_ClassificationType 0 "no detected" 1 "Circle;
0x2=Arrow;
0x3=X_Type;
0x4=Turn Round;
0x5=Arrow+Turn Round;
0x6=Other;
0x7=Invalid;";

VAL_ 406 FC_TFLTiOut 0 "no timeout" 1 "timeout";
VAL_ 406 FC_TLAMainObjectID 0 "Unknown
0x1-0x8=TLAx";
VAL_ 406 FC_TLAObjectsNumber 0 "";
VAL_ 406 FC_TLA8_ShapeType 0 "Unknown" 1 "Vertical -light
0x2=Horizontal -light
0x3=invalid";
VAL_ 406 FC_TLA8_BlindingStatus 0 "not detected" 1 "light;
0x2=flashing;
0x3=off";
VAL_ 406 FC_TLA8_direction 0 "";
VAL_ 406 FC_TLA8_Color 0 "No detected;
0x1=Red;
0x2=Green;
0x3=Yellow;
0x4=Off;
0x5=Other;
0x6=reserved;
0x7=invalid;";
VAL_ 406 FC_TLA8_ClassificationType 0 "no detected" 1 "Circle;
0x2=Arrow;
0x3=X_Type;
0x4=Turn Round;
0x5=Arrow+Turn Round;
0x6=Other;
0x7=Invalid;";
VAL_ 406 FC_TLA7_ShapeType 0 "Unknown" 1 "Vertical -light
0x2=Horizontal -light
0x3=invalid";
VAL_ 406 FC_TLA7_BlindingStatus 0 "not detected" 1 "light;
0x2=flashing;
0x3=off";
VAL_ 406 FC_TLA7_direction 0 "";
VAL_ 406 FC_TLA7_Color 0 "No detected;
0x1=Red;
0x2=Green;
0x3=Yellow;
0x4=Off;
0x5=Other;
0x6=reserved;
0x7=invalid;";
VAL_ 406 FC_TLA7_ClassificationType 0 "no detected" 1 "Circle;
0x2=Arrow;
0x3=X_Type;
0x4=Turn Round;
0x5=Arrow+Turn Round;
0x6=Other;
0x7=Invalid;";
VAL_ 406 FC_TLA6_ShapeType 0 "Unknown" 1 "Vertical -light
0x2=Horizontal -light
0x3=invalid";
VAL_ 406 FC_TLA6_BlindingStatus 0 "not detected" 1 "light;
0x2=flashing;
0x3=off";
VAL_ 406 FC_TLA6_direction 0 "";
VAL_ 406 FC_TLA6_Color 0 "No detected;
0x1=Red;
0x2=Green;
0x3=Yellow;
0x4=Off;
0x5=Other;
0x6=reserved;
0x7=invalid;";
VAL_ 406 FC_TLA6_ClassificationType 0 "no detected" 1 "Circle;
0x2=Arrow;
0x3=X_Type;
0x4=Turn Round;
0x5=Arrow+Turn Round;
0x6=Other;
0x7=Invalid;";
VAL_ 406 FC_TLA5_ShapeType 0 "Unknown" 1 "Vertical -light
0x2=Horizontal -light
0x3=invalid";
VAL_ 406 FC_TLA5_BlindingStatus 0 "not detected" 1 "light;
0x2=flashing;
0x3=off";
VAL_ 406 FC_TLA5_direction 0 "";
VAL_ 406 FC_TLA5_Color 0 "No detected;
0x1=Red;
0x2=Green;
0x3=Yellow;
0x4=Off;
0x5=Other;
0x6=reserved;
0x7=invalid;";
VAL_ 406 FC_TLA5_ClassificationType 0 "no detected" 1 "Circle;
0x2=Arrow;
0x3=X_Type;
0x4=Turn Round;
0x5=Arrow+Turn Round;
0x6=Other;
0x7=Invalid;";

VAL_ 407 FC_Pole2_Type 0 "";
VAL_ 407 FC_Pole2_Detected 0 "no detected" 1 "detected";
VAL_ 407 FC_Pole1_Type 0 "";
VAL_ 407 FC_Pole1_Detected 0 "no detected" 1 "detected";
VAL_ 407 FC_SpeedBump_Detect 0 "no detected" 1 "detected";
VAL_ 407 FC_Crosswalk_Detect 0 "no detected" 1 "detected";
VAL_ 407 FC_StopLine_Detected 0 "no detected" 1 "detected";
VAL_ 407 FC_TSRWarningSign 0 "";
VAL_ 407 FC_TSRProhibitionSign 0 "";
VAL_ 407 FC_TSRMandatorySign 0 "";
VAL_ 407 FC_TSRHostSpdLimitUnits 0 "";
VAL_ 407 FC_SpeedLimitType_1 0 "Unkonw、0x1=匝道限速、0x2=货车限速、0x3=轿车限速、0x4=非机动车限速、 0x5=客车限速、0x6~0x7 reserve";
VAL_ 407 FC_SpeedLimit_1 0 "";

VAL_ 408 FC_RoadSignCenterLatRange_3 0 "(-8)+(0.05*X)" 321 "Reserved";
VAL_ 408 FC_RoadSignCenterLngRange_3 0 "(0.1*X)m" 501 "Reserved";
VAL_ 408 FC_RoadSignType_3 0 "no detect;
0x1=Forward;
0x2=Left;
0x3=Right;
0x4=Turn Round to Left;
0x5=Turn Round to Right;
0x6=Forward +Left" 7 "Forward +Right" 8 "Forward +TurnRdToLeft" 9 "Forward +TurnRdToRight" 10 "TurnRd To Left or Right;
0xB=Left +TurnRd to Left;
0xC=Right +TurnRd to Right;
0xD=Left +TurnRd to Right;
0xE=Right +TurnRd to left;
0xF=Left +Forward+Right;
0x10=Left +Forward +TurnRd to Right;
0x11=Right +Forward +TurnRd to Left;
0x12=TurnRd to Rt+Forward +TurnRd to Lt;
0x13~0x1E=Reserved;
0x1F=invalid;";
VAL_ 408 FC_RoadSignCenterLatRange_2 0 "(-8)+(0.05*X)" 321 "Reserved";
VAL_ 408 FC_RoadSignCenterLngRange_2 0 "(0.1*X)m" 501 "Reserved";
VAL_ 408 FC_RoadSignType_2 0 "no detect;
0x1=Forward;
0x2=Left;
0x3=Right;
0x4=Turn Round to Left;
0x5=Turn Round to Right;
0x6=Forward +Left" 7 "Forward +Right" 8 "Forward +TurnRdToLeft" 9 "Forward +TurnRdToRight" 10 "TurnRd To Left or Right;
0xB=Left +TurnRd to Left;
0xC=Right +TurnRd to Right;
0xD=Left +TurnRd to Right;
0xE=Right +TurnRd to left;
0xF=Left +Forward+Right;
0x10=Left +Forward +TurnRd to Right;
0x11=Right +Forward +TurnRd to Left;
0x12=TurnRd to Rt+Forward +TurnRd to Lt;
0x13~0x1E=Reserved;
0x1F=invalid;";
VAL_ 408 FC_RoadSignCenterLatRange_1 0 "(-8)+(0.05*X)" 321 "Reserved";
VAL_ 408 FC_RoadSignCenterLngRange_1 0 "(0.1*X)m" 501 "Reserved";
VAL_ 408 FC_RoadSignType_1 0 "no detect;
0x1=Forward;
0x2=Left;
0x3=Right;
0x4=Turn Round to Left;
0x5=Turn Round to Right;
0x6=Forward +Left" 7 "Forward +Right" 8 "Forward +TurnRdToLeft" 9 "Forward +TurnRdToRight" 10 "TurnRd To Left or Right;
0xB=Left +TurnRd to Left;
0xC=Right +TurnRd to Right;
0xD=Left +TurnRd to Right;
0xE=Right +TurnRd to left;
0xF=Left +Forward+Right;
0x10=Left +Forward +TurnRd to Right;
0x11=Right +Forward +TurnRd to Left;
0x12=TurnRd to Rt+Forward +TurnRd to Lt;
0x13~0x1E=Reserved;
0x1F=invalid;";

VAL_ 264 FC_AEBTargetStatus 0 "";
VAL_ 264 FC_RLaneMarkerType 0 "";
VAL_ 264 FC_HostLaneRightStatus 0 "";
VAL_ 264 FC_RLaneDistanceFus 0 "-5-1" 120 "reserved";
VAL_ 264 FC_LLaneMarkerType 0 "";
VAL_ 264 FC_HostLaneLeftStatus 0 "";
VAL_ 264 FC_LLaneDistanceFus 0 "-1-5" 121 "reserved";
VAL_ 264 FC_HMAEnableStatus 0 "off" 1 "on";
VAL_ 264 FC_HMALightDistribution 0 " High beam not recommended" 1 " High beam recommended";
VAL_ 264 FC_HMAStatus 0 " Off" 1 " Standby" 2 " Active" 3 " Failure";
VAL_ 264 FC_LaneCurvature_0m 0 "-0.03-0.03" 121 "reserved";
VAL_ 264 FC_Voiceinfo 0 "no voice" 1 "latentWarning voive" 2 "FCW/AEB voice" 3 " reserved" 6 "Lane Left dangerous warning? voice" 7 "Lane Right dangerous warning? voice" 8 " reserved" 14 "TrafficWarning" 15 "reserved";
VAL_ 264 FC_AEBEnable 0 "off" 1 "on";
VAL_ 264 FC_FCWSettingStatus 0 "early" 1 "normal" 2 "late" 3 "Off" 4 "Reserved";
VAL_ 264 FC_FCWPreWarning 0 " no warning" 1 " warning";
VAL_ 264 FC_FCWLatentWarning 0 " no warning" 1 " warning";
VAL_ 264 FC_FCWActive 0 " not Active" 1 " Active.";
VAL_ 264 FC_FCWStatus 0 "off" 1 "on" 2 " reserved" 3 "failure";
VAL_ 264 FC_AEBTargetLatRange 0 "" 1001 "";
VAL_ 264 FC_AEBTargetLngRange 0 "-70~180" 501 "reserved" 511 "no display";
VAL_ 264 FC_AEBTargetDetection 0 "no detected" 1 "detected";
VAL_ 264 FC_AEBTargetType 0 "";
VAL_ 264 FC_AEBTargetRelSpeed 0 "" 501 "";
VAL_ 264 FC_AEBTextInfo 0 "no display" 1 "AEB Error by camera" 2 "AEB Error by FR" 3 "AEB Error by Dasy" 4 "AEB Error by FCR" 5 "AEB Error by EPBi" 6 "AEB Error by SAS" 7 "AEB Error by SRS" 8 "AEB Error by EMS" 9 "AEB Error by TCU" 10 "AEB Error by other" 11 "reserved" 12 "reserved" 13 "reserved" 14 "reserved" 15 "reserved";
VAL_ 264 FC_AEBStatus 0 "off" 1 "on" 2 " reserved" 3 "failure";
VAL_ 264 FC_ABAActive 0 " not Active" 1 " Active.";
VAL_ 264 FC_ABAlevel 0 "level 0" 1 "level 1" 2 "level 2" 3 "level 3";
VAL_ 264 FC_AWBActive 0 " not Active" 1 " Active.";
VAL_ 264 FC_AWBlevel 0 "no level" 1 "level 1" 2 "level 2" 3 "level 3" 4 "level 4" 5 "reserved";
VAL_ 264 FC_PrefillActive 0 " not Active" 1 " Active.";
VAL_ 264 FC_AEBVehilceHoldReq 0 "No hold" 1 "hold";
VAL_ 264 FC_AEBCtrlType 0 "no request" 1 "AEB C&U（AEB-Vehicle）" 2 "AEB VRU" 3 "AEB Cyclist" 4 "EBA" 5 "FCTB" 6 "RCTB" 7 "Reserved";
VAL_ 264 FC_AEBActive 0 " not Active" 1 " Active.";
VAL_ 264 FC_AEBTargetmode 0 "none" 1 "video only mode" 2 "rader only mode" 3 "fusion mode";
VAL_ 264 FC_ELKEnableStatus 0 "off" 1 "on";
VAL_ 264 FC_ELKInterventionMode 0 " off" 1 " Road edge" 2 " Overtaking" 3 " Oncoming.";
VAL_ 264 FC_ELKMode 0 " off" 1 " passive" 2 "active" 3 " fault" 4 " reserved.";
VAL_ 264 FC_LDWShakeLevStatus 0 "reserved" 1 "low" 2 "normal" 3 "high";
VAL_ 264 FC_LASWarningModeSelectionSts 0 "Reserved" 1 "sound" 2 "vibration" 3 "sound and vibration" 4 "Reserved";
VAL_ 264 FC_LASModeSelectionStatus 0 "Reserved" 1 "LDW" 2 "LKA" 3 "LCS" 4 "Reserved" 7 "OFF";
VAL_ 264 FC_LKATakeoverReq 0 "Not Req" 1 "Req";
VAL_ 264 FC_LKAStatus 0 "Off" 1 "Standby" 2 "Active" 3 "Failure";
VAL_ 264 FC_LDWVibrationWarningReq 0 " No Warning" 1 " Left Warning" 2 "Right Warning" 3 " reserved";
VAL_ 264 FC_LDWStatus 0 "Off" 1 "Standby" 2 "Active" 3 "Failure";

VAL_ 263 FC_LatAngReqActive 0 "not Active" 1 "Active";
VAL_ 263 FC_LatAngReq 14410 "Reserved";
VAL_ 263 FC_MotorTorqueMinLimitRequest 2047 " Reserved";
VAL_ 263 FC_MotorTorqueMaxLimitRequest 2047 " Reserved";

VAL_ 261 ESP_IMUCalibrated 0 "";
VAL_ 261 ESP_YawRateValid 0 "";
VAL_ 261 ESP_LongAccelValid 0 "";
VAL_ 261 ESP_LatAccelValid 0 "";
VAL_ 261 EpsSteerAgSensFilr 0 "";
VAL_ 261 EpsSasSteerAgVld 0 "";
VAL_ 261 EpsSasCalSts 0 "";
VAL_ 261 VcuRdySts 0 "";
VAL_ 261 VcuVehGearPosnVld 0 "";
VAL_ 261 VcuGearPosn 0 "";
VAL_ 261 WhlSpdRiReDir 0 "";
VAL_ 261 WhlSpdRiReDataVld 0 "";
VAL_ 261 WhlSpdRiFrntDir 0 "";
VAL_ 261 WhlSpdRiFrntDataVld 0 "";
VAL_ 261 WhlSpdLeReDir 0 "";
VAL_ 261 WhlSpdLeReDataVld 0 "";
VAL_ 261 WhlSpdLeFrntDir 0 "";
VAL_ 261 WhlSpdLeFrntDataVld 0 "";
VAL_ 261 EspVehSpdVld 0 "";

VAL_ 512 ADC_SYNC_Sync_Time 0 "0x20:SYNC. SyncTimeSec = 32bit LSB of the 48 bits Seconds part of the time
 
Type=0x28:FUP.SyncTimeNSec = 32 bit time stamp in nanoseconds";
VAL_ 512 ADC_SYNC_UserByte_OVS_SGW 0 "0x20:SYNC.用户自定义数据，默认为0.

Type=0x28:FUP.
bit1-bit0:OVS(Overflow of seconds)
bit2:SGW
bit7-bit3：reserved。";
VAL_ 512 ADC_SYNC_Type 32 "SYNC
0x28=FUP";

VAL_ 411 ACC_ACCMode 0 "";
VAL_ 411 ADC_SenceMode 0 "";
VAL_ 411 BcmPwrStsFb 0 "";
VAL_ 411 TboxLocalTiVld 0 "";
VAL_ 411 ADC_WorkMode 0 "";
VAL_ 411 ACC_IACCHWAMode 0 "";
VAL_ 411 ADS_UDLCStatus 0 "";
VAL_ 411 ADS_Fail 0 "";

VAL_ 518 FR_SwVers6 48 "";
VAL_ 518 FR_SwVers5 46 "";
VAL_ 518 FR_SwVers4 48 "";
VAL_ 518 FR_SwVers3 46 "";
VAL_ 518 FR_SwVers2 48 "";
VAL_ 518 FR_SwVers1 87 "";
VAL_ 518 FR_SwVers0 83 "";
VAL_ 518 FR_HwVers6 48 "";
VAL_ 518 FR_HwVers5 46 "";
VAL_ 518 FR_HwVers4 48 "";
VAL_ 518 FR_HwVers3 46 "";
VAL_ 518 FR_HwVers2 48 "";
VAL_ 518 FR_HwVers1 87 "";
VAL_ 518 FR_HwVers0 72 "";

VAL_ 519 FC_SwVers6 48 "";
VAL_ 519 FC_SwVers5 46 "";
VAL_ 519 FC_SwVers4 48 "";
VAL_ 519 FC_SwVers3 46 "";
VAL_ 519 FC_SwVers2 48 "";
VAL_ 519 FC_SwVers1 87 "";
VAL_ 519 FC_SwVers0 83 "";
VAL_ 519 FC_HwVers6 48 "";
VAL_ 519 FC_HwVers5 46 "";
VAL_ 519 FC_HwVers4 48 "";
VAL_ 519 FC_HwVers3 46 "";
VAL_ 519 FC_HwVers2 48 "";
VAL_ 519 FC_HwVers1 87 "";
VAL_ 519 FC_HwVers0 72 "";

VAL_ 837 RLR_ElkOBJ2_Measured 0 "unknown" 1 "Measured" 2 "Predicted" 3 "Reserved";
VAL_ 837 RLR_ElkOBJ2_Location 0 "unknown" 1 "Left Lane" 2 "Right  Lane" 3 "Ego Lane";
VAL_ 837 RLR_ElkOBJ2_Type 0 "Not Detected" 1 "car" 2 "truck" 3 "bicycle/motorbike" 4 "pedestrian" 5 "general" 6 "animal" 7 "uncertain";
VAL_ 837 RLR_ElkOBJ1_Measured 0 "unknown" 1 "Measured" 2 "Predicted" 3 "Reserved";
VAL_ 837 RLR_ElkOBJ1_Location 0 "unknown" 1 "Left Lane" 2 "Right  Lane" 3 "Ego Lane";
VAL_ 837 RLR_ElkOBJ1_Type 0 "Not Detected" 1 "car" 2 "truck" 3 "bicycle/motorbike" 4 "pedestrian" 5 "general" 6 "animal" 7 "uncertain";

VAL_ 838 RLR_ElkOBJ4_Measured 0 "unknown" 1 "Measured" 2 "Predicted" 3 "Reserved";
VAL_ 838 RLR_ElkOBJ4_Location 0 "unknown" 1 "Left Lane" 2 "Right  Lane" 3 "Ego Lane";
VAL_ 838 RLR_ElkOBJ4_Type 0 "Not Detected" 1 "car" 2 "truck" 3 "bicycle/motorbike" 4 "pedestrian" 5 "general" 6 "animal" 7 "uncertain";
VAL_ 838 RLR_ElkOBJ3_Measured 0 "unknown" 1 "Measured" 2 "Predicted" 3 "Reserved";
VAL_ 838 RLR_ElkOBJ3_Location 0 "unknown" 1 "Left Lane" 2 "Right  Lane" 3 "Ego Lane";
VAL_ 838 RLR_ElkOBJ3_Type 0 "Not Detected" 1 "car" 2 "truck" 3 "bicycle/motorbike" 4 "pedestrian" 5 "general" 6 "animal" 7 "uncertain";

VAL_ 836 RRR_WorkMode 0 "";
VAL_ 836 RLR_WorkMode 0 "";
VAL_ 836 RLR_Left_ELK_oAlert 0 "";
VAL_ 836 RLR_ELK_oStatus 0 "";
VAL_ 836 RLR_ELK_oAlert 0 "";

VAL_ 1428 FR_NotSleep_BYTE7BIT1 0 "";
VAL_ 1428 FR_NotSleep_BYTE7BIT0 0 "";
VAL_ 1428 FR_WakeUp_BYTE4BIT1 0 "";
VAL_ 1428 FR_WakeUp_BYTE4BIT0 0 "";

VAL_ 384 FC_StaticObj10_LaneAssi 0 "UNKNOWN    
0x1=InsideLane 
0x2=OutsideLane
0x3=Reserved";
VAL_ 384 FC_StaticObj9_LaneAssi 0 "UNKNOWN    
0x1=InsideLane 
0x2=OutsideLane
0x3=Reserved";
VAL_ 384 FC_StaticObj8_LaneAssi 0 "UNKNOWN    
0x1=InsideLane 
0x2=OutsideLane
0x3=Reserved";
VAL_ 384 FC_StaticObj7_LaneAssi 0 "UNKNOWN    
0x1=InsideLane 
0x2=OutsideLane
0x3=Reserved";
VAL_ 384 FC_StaticObj6_LaneAssi 0 "UNKNOWN    
0x1=InsideLane 
0x2=OutsideLane
0x3=Reserved";
VAL_ 384 FC_StaticObj5_LaneAssi 0 "UNKNOWN    
0x1=InsideLane 
0x2=OutsideLane
0x3=Reserved";
VAL_ 384 FC_StaticObj4_LaneAssi 0 "UNKNOWN    
0x1=InsideLane 
0x2=OutsideLane
0x3=Reserved";
VAL_ 384 FC_StaticObj3_LaneAssi 0 "UNKNOWN    
0x1=InsideLane 
0x2=OutsideLane
0x3=Reserved";
VAL_ 384 FC_StaticObj2_LaneAssi 0 "UNKNOWN    
0x1=InsideLane 
0x2=OutsideLane
0x3=Reserved";
VAL_ 384 FC_StaticObj1_LaneAssi 0 "UNKNOWN    
0x1=InsideLane 
0x2=OutsideLane
0x3=Reserved";
VAL_ 384 FC_StaticObj10_Type 0 "Not Detected" 1 "三角警示牌" 2 "水马" 3 "锥形筒" 4 "其它" 5 "隔离柱" 6 "预留";
VAL_ 384 FC_StaticObj9_Type 0 "Not Detected" 1 "三角警示牌" 2 "水马" 3 "锥形筒" 4 "其它" 5 "隔离柱" 6 "预留";
VAL_ 384 FC_StaticObj8_Type 0 "Not Detected" 1 "三角警示牌" 2 "水马" 3 "锥形筒" 4 "其它" 5 "隔离柱" 6 "预留";
VAL_ 384 FC_StaticObj7_Type 0 "Not Detected" 1 "三角警示牌" 2 "水马" 3 "锥形筒" 4 "其它" 5 "隔离柱" 6 "预留";
VAL_ 384 FC_StaticObj6_Type 0 "Not Detected" 1 "三角警示牌" 2 "水马" 3 "锥形筒" 4 "其它" 5 "隔离柱" 6 "预留";
VAL_ 384 FC_StaticObj5_Type 0 "Not Detected" 1 "三角警示牌" 2 "水马" 3 "锥形筒" 4 "其它" 5 "隔离柱" 6 "预留";
VAL_ 384 FC_StaticObj4_Type 0 "Not Detected" 1 "三角警示牌" 2 "水马" 3 "锥形筒" 4 "其它" 5 "隔离柱" 6 "预留";
VAL_ 384 FC_StaticObj3_Type 0 "Not Detected" 1 "三角警示牌" 2 "水马" 3 "锥形筒" 4 "其它" 5 "隔离柱" 6 "预留";
VAL_ 384 FC_StaticObj2_Type 0 "Not Detected" 1 "三角警示牌" 2 "水马" 3 "锥形筒" 4 "其它" 5 "隔离柱" 6 "预留";
VAL_ 384 FC_StaticObj1_Type 0 "Not Detected" 1 "三角警示牌" 2 "水马" 3 "锥形筒" 4 "其它" 5 "隔离柱" 6 "预留";

VAL_ 513 TC397_TimeSyncInit 0 "";

VAL_ 497 ADC_UTCTiVld 0 "";

VAL_ 498 FC_UTCTiVld 0 "";

VAL_ 385 FC_StaticObj20_LaneAssi 0 "UNKNOWN    
0x1=InsideLane 
0x2=OutsideLane
0x3=Reserved";
VAL_ 385 FC_StaticObj19_LaneAssi 0 "UNKNOWN    
0x1=InsideLane 
0x2=OutsideLane
0x3=Reserved";
VAL_ 385 FC_StaticObj18_LaneAssi 0 "UNKNOWN    
0x1=InsideLane 
0x2=OutsideLane
0x3=Reserved";
VAL_ 385 FC_StaticObj17_LaneAssi 0 "UNKNOWN    
0x1=InsideLane 
0x2=OutsideLane
0x3=Reserved";
VAL_ 385 FC_StaticObj16_LaneAssi 0 "UNKNOWN    
0x1=InsideLane 
0x2=OutsideLane
0x3=Reserved";
VAL_ 385 FC_StaticObj15_LaneAssi 0 "UNKNOWN    
0x1=InsideLane 
0x2=OutsideLane
0x3=Reserved";
VAL_ 385 FC_StaticObj14_LaneAssi 0 "UNKNOWN    
0x1=InsideLane 
0x2=OutsideLane
0x3=Reserved";
VAL_ 385 FC_StaticObj13_LaneAssi 0 "UNKNOWN    
0x1=InsideLane 
0x2=OutsideLane
0x3=Reserved";
VAL_ 385 FC_StaticObj12_LaneAssi 0 "UNKNOWN    
0x1=InsideLane 
0x2=OutsideLane
0x3=Reserved";
VAL_ 385 FC_StaticObj11_LaneAssi 0 "UNKNOWN    
0x1=InsideLane 
0x2=OutsideLane
0x3=Reserved";
VAL_ 385 FC_StaticObj20_Type 0 "Not Detected" 1 "三角警示牌" 2 "水马" 3 "锥形筒" 4 "其它" 5 "隔离柱" 6 "预留";
VAL_ 385 FC_StaticObj19_Type 0 "Not Detected" 1 "三角警示牌" 2 "水马" 3 "锥形筒" 4 "其它" 5 "隔离柱" 6 "预留";
VAL_ 385 FC_StaticObj18_Type 0 "Not Detected" 1 "三角警示牌" 2 "水马" 3 "锥形筒" 4 "其它" 5 "隔离柱" 6 "预留";
VAL_ 385 FC_StaticObj17_Type 0 "Not Detected" 1 "三角警示牌" 2 "水马" 3 "锥形筒" 4 "其它" 5 "隔离柱" 6 "预留";
VAL_ 385 FC_StaticObj16_Type 0 "Not Detected" 1 "三角警示牌" 2 "水马" 3 "锥形筒" 4 "其它" 5 "隔离柱" 6 "预留";
VAL_ 385 FC_StaticObj15_Type 0 "Not Detected" 1 "三角警示牌" 2 "水马" 3 "锥形筒" 4 "其它" 5 "隔离柱" 6 "预留";
VAL_ 385 FC_StaticObj14_Type 0 "Not Detected" 1 "三角警示牌" 2 "水马" 3 "锥形筒" 4 "其它" 5 "隔离柱" 6 "预留";
VAL_ 385 FC_StaticObj13_Type 0 "Not Detected" 1 "三角警示牌" 2 "水马" 3 "锥形筒" 4 "其它" 5 "隔离柱" 6 "预留";
VAL_ 385 FC_StaticObj12_Type 0 "Not Detected" 1 "三角警示牌" 2 "水马" 3 "锥形筒" 4 "其它" 5 "隔离柱" 6 "预留";
VAL_ 385 FC_StaticObj11_Type 0 "Not Detected" 1 "三角警示牌" 2 "水马" 3 "锥形筒" 4 "其它" 5 "隔离柱" 6 "预留";
